VERSION "created by canmatrix"

NS_ :

BS_:

BU_: BDC_Body CHC DME1 EME FLA NiVi ZGW Kombi Kombi_Basis Diagnosetool_FA_CAN CDC_ZGW DME2 ELV Gliwa_T1_Host FA_CAN_Dummy

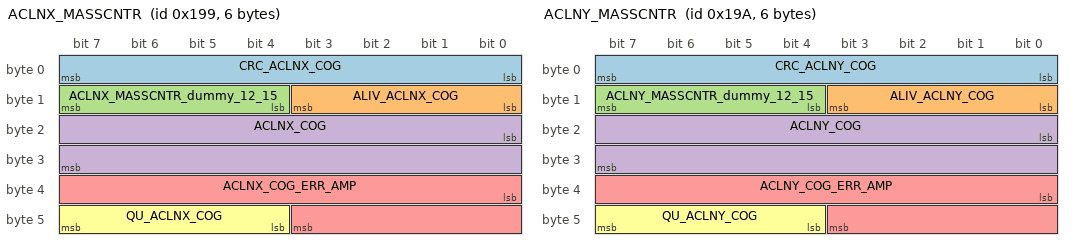
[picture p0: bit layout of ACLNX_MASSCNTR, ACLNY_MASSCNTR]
BO_ 409 ACLNX_MASSCNTR: 6 ZGW
 SG_ CRC_ACLNX_COG : 0|8@1+ (1,0) [0|255] "This unit fulfills the required AUTOSAR reference to a unit. No real unit is defined." Vector__XXX
 SG_ ALIV_ACLNX_COG : 8|4@1+ (1,0) [0|14] "This unit fulfills the required AUTOSAR reference to a unit. No real unit is defined." Vector__XXX
 SG_ ACLNX_MASSCNTR_dummy_12_15 : 12|4@1+ (1,0) [-8|7] "" Vector__XXX
 SG_ ACLNX_COG : 16|16@1+ (0.002,-65) [-65.130|-64.870] "m/s²" Vector__XXX
 SG_ ACLNX_COG_ERR_AMP : 32|12@1+ (0.005,0) [0.000|0.100] "m/s²" Vector__XXX
 SG_ QU_ACLNX_COG : 44|4@1+ (1,0) [0|15] "" Vector__XXX

BO_ 410 ACLNY_MASSCNTR: 6 ZGW
 SG_ CRC_ACLNY_COG : 0|8@1+ (1,0) [0|255] "This unit fulfills the required AUTOSAR reference to a unit. No real unit is defined." Vector__XXX
 SG_ ALIV_ACLNY_COG : 8|4@1+ (1,0) [0|14] "This unit fulfills the required AUTOSAR reference to a unit. No real unit is defined." Vector__XXX
 SG_ ACLNY_MASSCNTR_dummy_12_15 : 12|4@1+ (1,0) [-8|7] "" Vector__XXX
 SG_ ACLNY_COG : 16|16@1+ (0.002,-65) [-65.130|-64.870] "m/s²" Vector__XXX
 SG_ ACLNY_COG_ERR_AMP : 32|12@1+ (0.005,0) [0.000|0.100] "m/s²" Vector__XXX
 SG_ QU_ACLNY_COG : 44|4@1+ (1,0) [0|15] "" Vector__XXX

BO_ 517 ACOU_RQ_KI: 2 Kombi
 SG_ RQ_ACOU_KI : 0|4@1+ (1,0) [0|15] "" ZGW

BO_ 999 ACTVN_CARS: 8 ZGW
 SG_ CTR_ACTVN_CARS : 0|8@1+ (1,0) [0|255] "" BDC_Body
 SG_ CTR_FBD_CARS : 8|8@1+ (1,0) [0|255] "" BDC_Body
 SG_ CTR_PRSL_PROFIL_CARS : 16|8@1+ (1,0) [0|255] "" BDC_Body

BO_ 192 ALIVE_ZGM: 2 ZGW
 SG_ ALIV_COU_ZGM : 0|4@1+ (1,0) [0|15] "" Kombi,Diagnosetool_FA_CAN,Kombi_Basis
 SG_ INFO_BUS_ZGM : 8|8@1+ (1,0) [0|255] "" Diagnosetool_FA_CAN

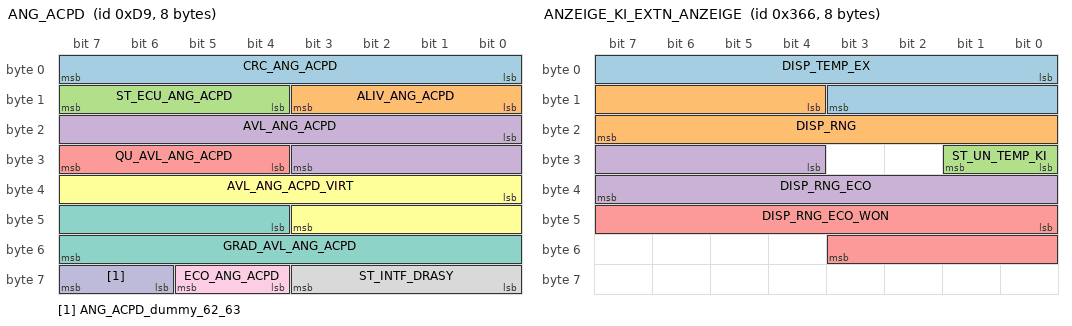
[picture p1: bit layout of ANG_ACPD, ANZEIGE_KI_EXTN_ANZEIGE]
BO_ 217 ANG_ACPD: 8 DME1
 SG_ CRC_ANG_ACPD : 0|8@1+ (1,0) [0|255] "This unit fulfills the required AUTOSAR reference to a unit. No real unit is defined." Vector__XXX
 SG_ ALIV_ANG_ACPD : 8|4@1+ (1,0) [0|14] "This unit fulfills the required AUTOSAR reference to a unit. No real unit is defined." Vector__XXX
 SG_ ST_ECU_ANG_ACPD : 12|4@1+ (1,0) [0|15] "" Vector__XXX
 SG_ AVL_ANG_ACPD : 16|12@1+ (0.025,0) [0.000|2.500] "%" Vector__XXX
 SG_ QU_AVL_ANG_ACPD : 28|4@1+ (1,0) [0|15] "" Vector__XXX
 SG_ AVL_ANG_ACPD_VIRT : 32|12@1+ (0.025,0) [0.000|2.500] "%" Vector__XXX
 SG_ GRAD_AVL_ANG_ACPD : 44|12@1+ (4,-8187) [-40935|24569] "%/s" Vector__XXX
 SG_ ST_INTF_DRASY : 56|4@1+ (1,0) [0|15] "" Vector__XXX
 SG_ ECO_ANG_ACPD : 60|2@1+ (1,0) [0|3] "" Vector__XXX
 SG_ ANG_ACPD_dummy_62_63 : 62|2@1+ (1,0) [-2|1] "" Vector__XXX

BO_ 870 ANZEIGE_KI_EXTN_ANZEIGE: 8 Kombi
 SG_ DISP_TEMP_EX : 0|12@1+ (0.5,-40) [-60|44] "This unit fulfills the required AUTOSAR reference to a unit. No real unit is defined." ZGW
 SG_ DISP_RNG : 12|12@1+ (1,0) [0|4000] "This unit fulfills the required AUTOSAR reference to a unit. No real unit is defined." ZGW
 SG_ ST_UN_TEMP_KI : 24|2@1+ (1,0) [0|3] "" ZGW
 SG_ DISP_RNG_ECO : 28|12@1+ (1,0) [0|4000] "This unit fulfills the required AUTOSAR reference to a unit. No real unit is defined." ZGW
 SG_ DISP_RNG_ECO_WON : 40|12@1+ (0.1,0) [0|40.92] "This unit fulfills the required AUTOSAR reference to a unit. No real unit is defined." ZGW

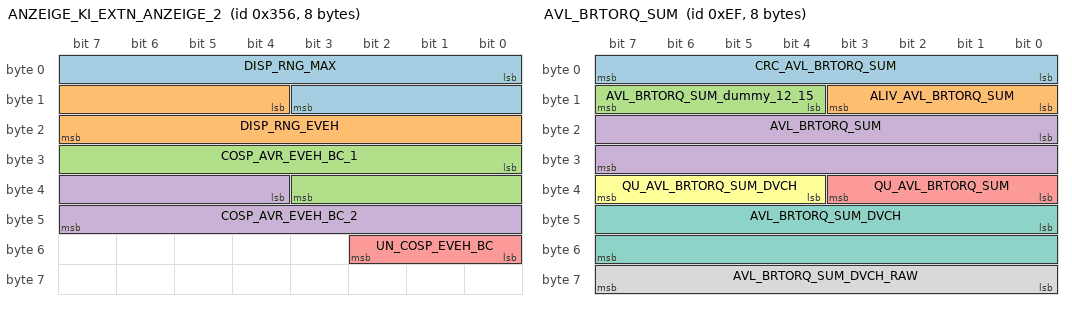
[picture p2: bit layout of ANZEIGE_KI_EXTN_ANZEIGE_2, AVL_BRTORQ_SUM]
BO_ 854 ANZEIGE_KI_EXTN_ANZEIGE_2: 8 Kombi
 SG_ DISP_RNG_MAX : 0|12@1+ (1,0) [0|4000] "This unit fulfills the required AUTOSAR reference to a unit. No real unit is defined." ZGW
 SG_ DISP_RNG_EVEH : 12|12@1+ (1,0) [0|4000] "This unit fulfills the required AUTOSAR reference to a unit. No real unit is defined." ZGW,BDC_Body
 SG_ COSP_AVR_EVEH_BC_1 : 24|12@1+ (0.1,0) [0|40] "This unit fulfills the required AUTOSAR reference to a unit. No real unit is defined." ZGW
 SG_ COSP_AVR_EVEH_BC_2 : 36|12@1+ (0.1,0) [0|40] "This unit fulfills the required AUTOSAR reference to a unit. No real unit is defined." ZGW
 SG_ UN_COSP_EVEH_BC : 48|3@1+ (1,0) [0|7] "" ZGW

BO_ 239 AVL_BRTORQ_SUM: 8 ZGW
 SG_ CRC_AVL_BRTORQ_SUM : 0|8@1+ (1,0) [0|255] "This unit fulfills the required AUTOSAR reference to a unit. No real unit is defined." Vector__XXX
 SG_ ALIV_AVL_BRTORQ_SUM : 8|4@1+ (1,0) [0|14] "This unit fulfills the required AUTOSAR reference to a unit. No real unit is defined." Vector__XXX
 SG_ AVL_BRTORQ_SUM_dummy_12_15 : 12|4@1+ (1,0) [-8|7] "" Vector__XXX
 SG_ AVL_BRTORQ_SUM : 16|16@1+ (1,-32000) [-64000|-32000] "Nm" Vector__XXX
 SG_ QU_AVL_BRTORQ_SUM : 32|4@1+ (1,0) [0|15] "" Vector__XXX
 SG_ QU_AVL_BRTORQ_SUM_DVCH : 36|4@1+ (1,0) [0|15] "" Vector__XXX
 SG_ AVL_BRTORQ_SUM_DVCH : 40|16@1+ (1,-32000) [-64000|-32000] "Nm" Vector__XXX
 SG_ AVL_BRTORQ_SUM_DVCH_RAW : 56|8@1+ (1,-252) [-504|-252] "Nm" Vector__XXX

BO_ 264 AVL_DT_LE: 8 EME
 SG_ AVL_OPMO_CHGE : 40|4@1+ (1,0) [0|15] "" Vector__XXX

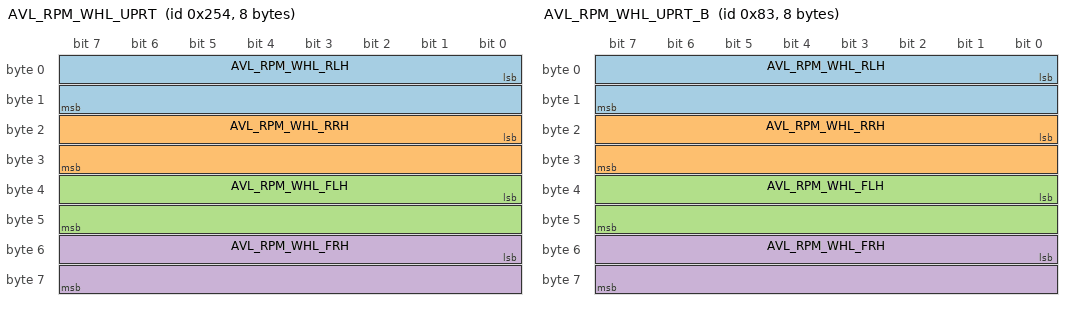
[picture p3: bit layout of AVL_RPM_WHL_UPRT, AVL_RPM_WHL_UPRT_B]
BO_ 596 AVL_RPM_WHL_UPRT: 8 ZGW
 SG_ AVL_RPM_WHL_RLH : 0|16@1+ (0.015625,-511.984375) [-518.234375|-505.734375] "rad/s" Kombi,BDC_Body,Kombi_Basis,DME1
 SG_ AVL_RPM_WHL_RRH : 16|16@1+ (0.015625,-511.984375) [-518.234375|-505.734375] "rad/s" Kombi,BDC_Body,Kombi_Basis,DME1
 SG_ AVL_RPM_WHL_FLH : 32|16@1+ (0.015625,-511.984375) [-518.234375|-505.734375] "rad/s" Kombi,BDC_Body,Kombi_Basis,DME1
 SG_ AVL_RPM_WHL_FRH : 48|16@1+ (0.015625,-511.984375) [-518.234375|-505.734375] "rad/s" Kombi,BDC_Body,Kombi_Basis,DME1

BO_ 131 AVL_RPM_WHL_UPRT_B: 8 ZGW
 SG_ AVL_RPM_WHL_RLH : 0|16@1+ (0.015625,-511.984375) [-518.234375|-505.734375] "rad/s" Kombi,DME1
 SG_ AVL_RPM_WHL_RRH : 16|16@1+ (0.015625,-511.984375) [-518.234375|-505.734375] "rad/s" Kombi,DME1
 SG_ AVL_RPM_WHL_FLH : 32|16@1+ (0.015625,-511.984375) [-518.234375|-505.734375] "rad/s" Kombi,DME1
 SG_ AVL_RPM_WHL_FRH : 48|16@1+ (0.015625,-511.984375) [-518.234375|-505.734375] "rad/s" Kombi,DME1

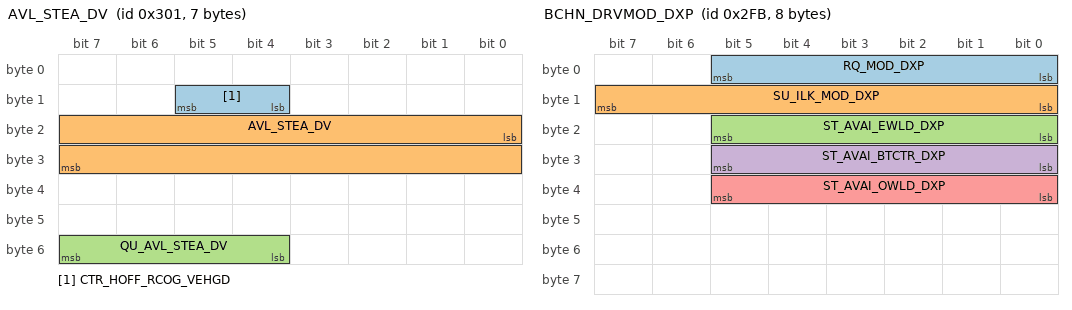
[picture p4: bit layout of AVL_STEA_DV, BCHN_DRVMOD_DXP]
BO_ 769 AVL_STEA_DV: 7 ZGW
 SG_ CTR_HOFF_RCOG_VEHGD : 12|2@1+ (1,0) [0|3] "" BDC_Body
 SG_ AVL_STEA_DV : 16|16@1+ (0.0439453125,-1439.9560546875) [-1503.23537349700927734375|-1376.67673587799072265625] "°" BDC_Body
 SG_ QU_AVL_STEA_DV : 52|4@1+ (1,0) [0|15] "" BDC_Body

BO_ 714 A_TEMP: 2 Kombi
 SG_ TEMP_EX : 0|8@1+ (0.5,-40) [-40|85] "°C" CDC_ZGW,BDC_Body,FLA,ELV,EME,DME2,DME1,CHC,ZGW,NiVi
 SG_ TEMP_EX_UNFILT : 8|8@1+ (0.5,-40) [-40|85] "°C" ZGW,DME2,DME1

BO_ 763 BCHN_DRVMOD_DXP: 8 DME1
 SG_ RQ_MOD_DXP : 0|6@1+ (1,0) [0|63] "" BDC_Body
 SG_ SU_ILK_MOD_DXP : 8|8@1+ (1,0) [0|255] "" BDC_Body
 SG_ ST_AVAI_EWLD_DXP : 16|6@1+ (1,0) [0|63] "" ZGW,BDC_Body
 SG_ ST_AVAI_BTCTR_DXP : 24|6@1+ (1,0) [0|63] "" ZGW,BDC_Body
 SG_ ST_AVAI_OWLD_DXP : 32|6@1+ (1,0) [0|63] "" ZGW,BDC_Body

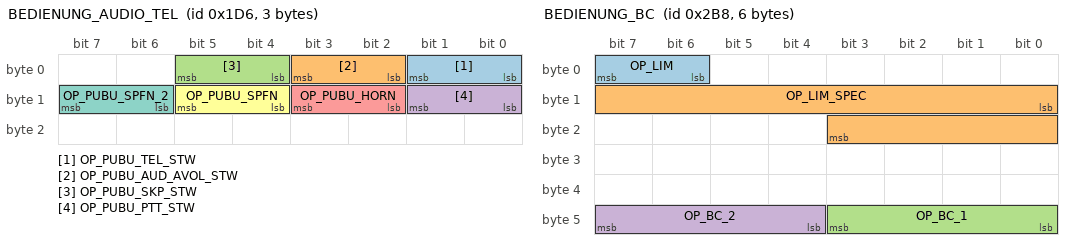
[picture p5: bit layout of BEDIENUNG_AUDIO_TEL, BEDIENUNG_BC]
BO_ 470 BEDIENUNG_AUDIO_TEL: 3 BDC_Body
 SG_ OP_PUBU_TEL_STW : 0|2@1+ (1,0) [0|3] "" ZGW
 SG_ OP_PUBU_AUD_AVOL_STW : 2|2@1+ (1,0) [0|3] "" ZGW
 SG_ OP_PUBU_SKP_STW : 4|2@1+ (1,0) [0|3] "" ZGW
 SG_ OP_PUBU_PTT_STW : 8|2@1+ (1,0) [0|3] "" ZGW
 SG_ OP_PUBU_HORN : 10|2@1+ (1,0) [0|3] "" ZGW
 SG_ OP_PUBU_SPFN : 12|2@1+ (1,0) [0|3] "" ZGW
 SG_ OP_PUBU_SPFN_2 : 14|2@1+ (1,0) [0|3] "" ZGW

BO_ 696 BEDIENUNG_BC: 6 ZGW
 SG_ OP_LIM : 6|2@1+ (1,0) [0|3] "" Kombi,Kombi_Basis
 SG_ OP_LIM_SPEC : 8|12@1+ (1,0) [0|4094] "This unit fulfills the required AUTOSAR reference to a unit. No real unit is defined." Kombi,Kombi_Basis
 SG_ OP_BC_1 : 40|4@1+ (1,0) [0|15] "" Kombi,Kombi_Basis
 SG_ OP_BC_2 : 44|4@1+ (1,0) [0|15] "" Kombi,Kombi_Basis

BO_ 494 BEDIENUNG_LENKSTOCK: 2 BDC_Body
 SG_ OP_COLS : 0|8@1+ (1,0) [0|255] "" NiVi,FLA,Kombi_Basis,ZGW,Kombi
 SG_ ST_PUBU_MAB_ASST : 8|2@1+ (1,0) [0|3] "" ZGW

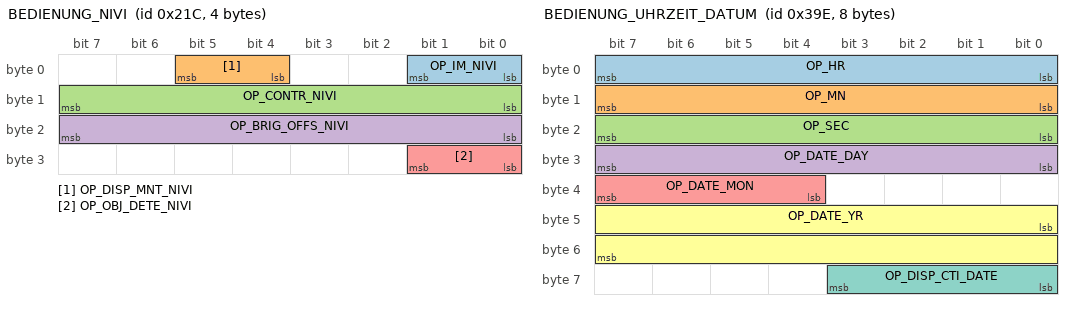
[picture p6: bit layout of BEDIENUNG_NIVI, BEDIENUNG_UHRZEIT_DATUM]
BO_ 540 BEDIENUNG_NIVI: 4 ZGW
 SG_ OP_IM_NIVI : 0|2@1+ (1,0) [0|3] "" NiVi
 SG_ OP_DISP_MNT_NIVI : 4|2@1+ (1,0) [0|3] "" NiVi
 SG_ OP_CONTR_NIVI : 8|8@1+ (1,0) [0|100] "%" NiVi
 SG_ OP_BRIG_OFFS_NIVI : 16|8@1+ (1,0) [0|100] "%" NiVi
 SG_ OP_OBJ_DETE_NIVI : 24|2@1+ (1,0) [0|3] "" NiVi

BO_ 552 BEDIENUNG_SONDERFUNKTION: 2 ZGW
 SG_ ID_SPFN : 0|16@1+ (1,0) [0|65534] "This unit fulfills the required AUTOSAR reference to a unit. No real unit is defined." DME2,DME1

BO_ 926 BEDIENUNG_UHRZEIT_DATUM: 8 ZGW
 SG_ OP_HR : 0|8@1+ (1,0) [0|254] "h" Kombi,Kombi_Basis
 SG_ OP_MN : 8|8@1+ (1,0) [0|254] "min" Kombi,Kombi_Basis
 SG_ OP_SEC : 16|8@1+ (1,0) [0|254] "s" Kombi,Kombi_Basis
 SG_ OP_DATE_DAY : 24|8@1+ (1,0) [0|254] "This unit fulfills the required AUTOSAR reference to a unit. No real unit is defined." Kombi,Kombi_Basis
 SG_ OP_DATE_MON : 36|4@1+ (1,0) [0|14] "This unit fulfills the required AUTOSAR reference to a unit. No real unit is defined." Kombi,Kombi_Basis
 SG_ OP_DATE_YR : 40|16@1+ (1,0) [0|65534] "This unit fulfills the required AUTOSAR reference to a unit. No real unit is defined." Kombi,Kombi_Basis
 SG_ OP_DISP_CTI_DATE : 56|4@1+ (1,0) [0|15] "" Kombi,Kombi_Basis

BO_ 678 BEDIENUNG_WISCHER: 2 BDC_Body
 SG_ OP_WISW : 0|8@1+ (1,0) [0|255] "" ZGW
 SG_ OP_WIPO : 8|3@1+ (1,0) [0|7] "" ZGW
 SG_ ALIV_WISW : 11|4@1+ (1,0) [0|15] "" ZGW

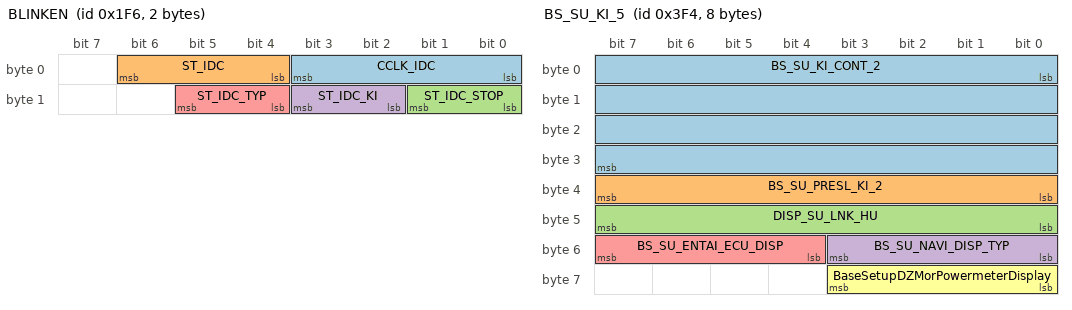
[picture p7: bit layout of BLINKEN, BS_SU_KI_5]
BO_ 502 BLINKEN: 2 BDC_Body
 SG_ CCLK_IDC : 0|4@1+ (1,0) [0|15] "" ZGW,Kombi,Kombi_Basis
 SG_ ST_IDC : 4|3@1+ (1,0) [0|7] "" DME2,DME1,Kombi_Basis,ZGW,Kombi
 SG_ ST_IDC_STOP : 8|2@1+ (1,0) [0|3] "" ZGW,Kombi,Kombi_Basis
 SG_ ST_IDC_KI : 10|2@1+ (1,0) [0|3] "" ZGW,Kombi,Kombi_Basis
 SG_ ST_IDC_TYP : 12|2@1+ (1,0) [0|3] "" ZGW

BO_ 641 BN_UVL: 2 DME1
 SG_ MEAQ_U_14V : 0|12@1+ (15,0) [0|900000] "mV" ZGW,BDC_Body

BO_ 677 BRIG_SURR: 2 BDC_Body
 SG_ VL_BRIG_ENVI : 0|8@1+ (100,0) [0|2540000] "lx" ZGW,Kombi,Kombi_Basis,NiVi
 SG_ VL_BRIG_PFIE : 8|8@1+ (0.0067,0) [0.0000|0.01140206] "W/m²" ZGW,Kombi,Kombi_Basis

BO_ 946 BS_SU_KI_4: 8 Kombi
 SG_ BS_SU_KI_BC : 0|32@1+ (1,0) [0|4294967295] "" ZGW
 SG_ BS_SU_KI_CONT : 32|16@1+ (1,0) [0|65535] "" ZGW
 SG_ BS_SU_PRESL_KI : 48|8@1+ (1,0) [0|255] "" ZGW

BO_ 1012 BS_SU_KI_5: 8 Kombi
 SG_ BS_SU_KI_CONT_2 : 0|32@1+ (1,0) [0|4294967295] "" ZGW
 SG_ BS_SU_PRESL_KI_2 : 32|8@1+ (1,0) [0|255] "" ZGW
 SG_ DISP_SU_LNK_HU : 40|8@1+ (1,0) [0|255] "" ZGW
 SG_ BS_SU_NAVI_DISP_TYP : 48|4@1+ (1,0) [0|15] "" ZGW
 SG_ BS_SU_ENTAI_ECU_DISP : 52|4@1+ (1,0) [0|15] "" ZGW
 SG_ BaseSetupDZMorPowermeterDisplay : 56|4@1+ (1,0) [0|15] "" ZGW

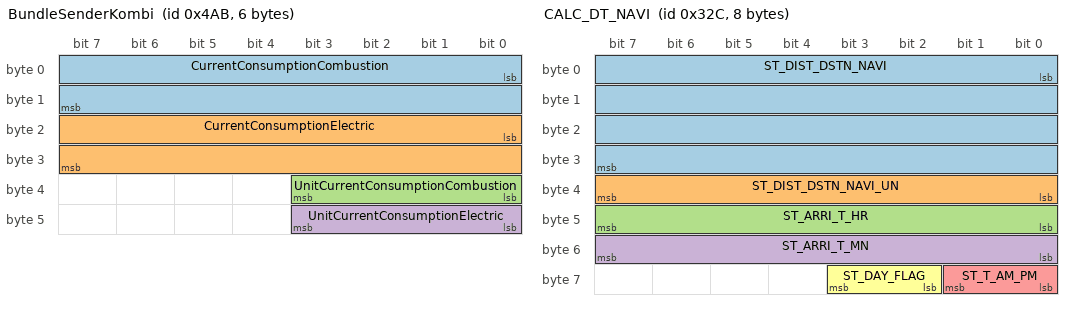
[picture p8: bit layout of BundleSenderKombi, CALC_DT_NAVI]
BO_ 1195 BundleSenderKombi: 6 Kombi
 SG_ CurrentConsumptionCombustion : 0|16@1+ (0.1,0) [0|655.32] "This unit fulfills the required AUTOSAR reference to a unit. No real unit is defined." CDC_ZGW
 SG_ CurrentConsumptionElectric : 16|16@1+ (0.1,0) [0|655.32] "This unit fulfills the required AUTOSAR reference to a unit. No real unit is defined." CDC_ZGW
 SG_ UnitCurrentConsumptionCombustion : 32|4@1+ (1,0) [0|15] "" CDC_ZGW
 SG_ UnitCurrentConsumptionElectric : 40|4@1+ (1,0) [0|15] "" CDC_ZGW

BO_ 812 CALC_DT_NAVI: 8 ZGW
 SG_ ST_DIST_DSTN_NAVI : 0|32@1+ (0.001,0) [0.000|4294.967294] "This unit fulfills the required AUTOSAR reference to a unit. No real unit is defined." Kombi,Kombi_Basis
 SG_ ST_DIST_DSTN_NAVI_UN : 32|8@1+ (1,0) [0|255] "" Kombi,Kombi_Basis
 SG_ ST_ARRI_T_HR : 40|8@1+ (1,0) [0|23] "h" Kombi,Kombi_Basis
 SG_ ST_ARRI_T_MN : 48|8@1+ (1,0) [0|59] "min" Kombi,Kombi_Basis
 SG_ ST_T_AM_PM : 56|2@1+ (1,0) [0|3] "" Kombi,Kombi_Basis
 SG_ ST_DAY_FLAG : 58|2@1+ (1,0) [0|3] "" Kombi,Kombi_Basis

BO_ 1184 CAS_ST_1: 8 BDC_Body
 SG_ DT_APPL_CAS_ST_1 : 0|64@1+ (1,0) [0|18446744073709551615] "This unit fulfills the required AUTOSAR reference to a unit. No real unit is defined." BDC_Body

BO_ 1186 CAS_ST_2: 8 BDC_Body
 SG_ DT_APPL_CAS_ST_2 : 0|64@1+ (1,0) [0|18446744073709551615] "This unit fulfills the required AUTOSAR reference to a unit. No real unit is defined." BDC_Body

BO_ 110 CCLK_COU_SYNCN_CAN: 8 ZGW
 SG_ CCLK_COU_SYNCN_CAN_TYP : 0|8@1+ (1,0) [0|255] "" Vector__XXX
 SG_ CCLK_COU_SYNCN_CAN_IDENT : 8|16@1+ (1,0) [0|65532] "This unit fulfills the required AUTOSAR reference to a unit. No real unit is defined." Vector__XXX
 SG_ CCLK_COU_SYNCN_CAN_SEC : 24|32@1+ (1,0) [0|4294967292] "s" Vector__XXX

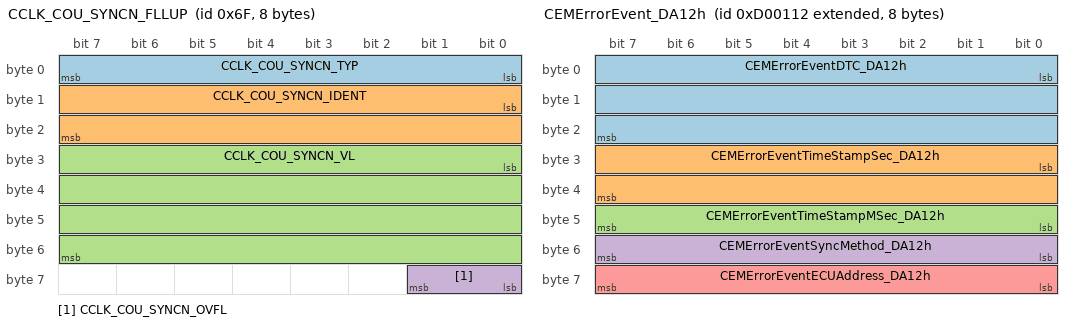
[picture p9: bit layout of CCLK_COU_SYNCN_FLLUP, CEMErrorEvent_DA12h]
BO_ 111 CCLK_COU_SYNCN_FLLUP: 8 ZGW
 SG_ CCLK_COU_SYNCN_TYP : 0|8@1+ (1,0) [0|255] "" Vector__XXX
 SG_ CCLK_COU_SYNCN_IDENT : 8|16@1+ (1,0) [0|65532] "This unit fulfills the required AUTOSAR reference to a unit. No real unit is defined." Vector__XXX
 SG_ CCLK_COU_SYNCN_VL : 24|32@1+ (1,0) [0|3999999999] "ns/4" Vector__XXX
 SG_ CCLK_COU_SYNCN_OVFL : 56|2@1+ (1,0) [0|3] "" Vector__XXX

BO_ 2161115410 CEMErrorEvent_DA12h: 8 DME1
 SG_ CEMErrorEventDTC_DA12h : 0|24@1+ (1,0) [0|16777212] "This unit fulfills the required AUTOSAR reference to a unit. No real unit is defined." Vector__XXX
 SG_ CEMErrorEventTimeStampSec_DA12h : 24|16@1+ (1,0) [0|65532] "s" Vector__XXX
 SG_ CEMErrorEventTimeStampMSec_DA12h : 40|8@1+ (1,0) [0|199] "ms" Vector__XXX
 SG_ CEMErrorEventSyncMethod_DA12h : 48|8@1+ (1,0) [0|252] "This unit fulfills the required AUTOSAR reference to a unit. No real unit is defined." Vector__XXX
 SG_ CEMErrorEventECUAddress_DA12h : 56|8@1+ (1,0) [0|207] "This unit fulfills the required AUTOSAR reference to a unit. No real unit is defined." Vector__XXX

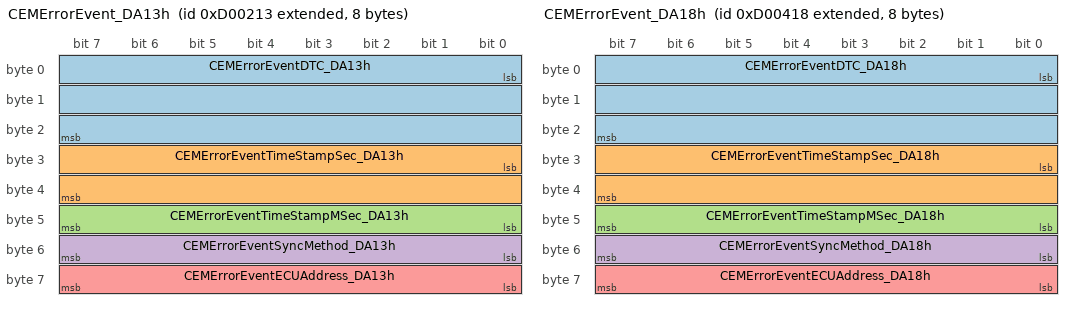
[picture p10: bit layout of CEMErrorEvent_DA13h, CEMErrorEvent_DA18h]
BO_ 2161115667 CEMErrorEvent_DA13h: 8 DME2
 SG_ CEMErrorEventDTC_DA13h : 0|24@1+ (1,0) [0|16777212] "This unit fulfills the required AUTOSAR reference to a unit. No real unit is defined." Vector__XXX
 SG_ CEMErrorEventTimeStampSec_DA13h : 24|16@1+ (1,0) [0|65532] "s" Vector__XXX
 SG_ CEMErrorEventTimeStampMSec_DA13h : 40|8@1+ (1,0) [0|199] "ms" Vector__XXX
 SG_ CEMErrorEventSyncMethod_DA13h : 48|8@1+ (1,0) [0|252] "This unit fulfills the required AUTOSAR reference to a unit. No real unit is defined." Vector__XXX
 SG_ CEMErrorEventECUAddress_DA13h : 56|8@1+ (1,0) [0|207] "This unit fulfills the required AUTOSAR reference to a unit. No real unit is defined." Vector__XXX

BO_ 2161116184 CEMErrorEvent_DA18h: 8 DME1
 SG_ CEMErrorEventDTC_DA18h : 0|24@1+ (1,0) [0|16777212] "This unit fulfills the required AUTOSAR reference to a unit. No real unit is defined." Vector__XXX
 SG_ CEMErrorEventTimeStampSec_DA18h : 24|16@1+ (1,0) [0|65532] "s" Vector__XXX
 SG_ CEMErrorEventTimeStampMSec_DA18h : 40|8@1+ (1,0) [0|199] "ms" Vector__XXX
 SG_ CEMErrorEventSyncMethod_DA18h : 48|8@1+ (1,0) [0|252] "This unit fulfills the required AUTOSAR reference to a unit. No real unit is defined." Vector__XXX
 SG_ CEMErrorEventECUAddress_DA18h : 56|8@1+ (1,0) [0|207] "This unit fulfills the required AUTOSAR reference to a unit. No real unit is defined." Vector__XXX

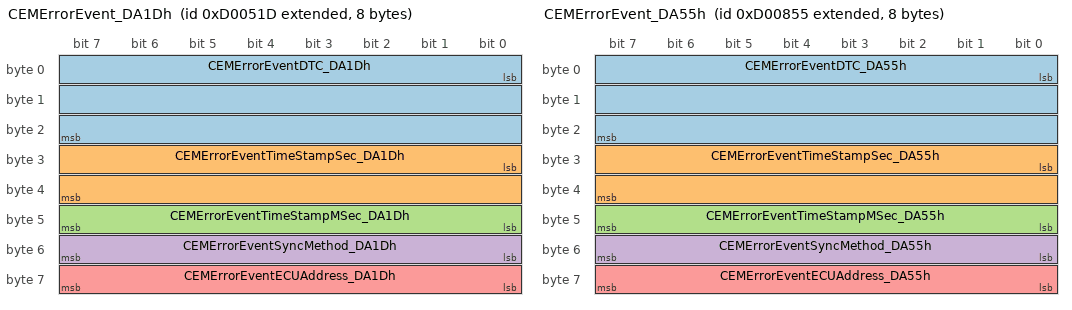
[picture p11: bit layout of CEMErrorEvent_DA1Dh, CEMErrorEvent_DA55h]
BO_ 2161116445 CEMErrorEvent_DA1Dh: 8 DME1
 SG_ CEMErrorEventDTC_DA1Dh : 0|24@1+ (1,0) [0|16777212] "This unit fulfills the required AUTOSAR reference to a unit. No real unit is defined." Vector__XXX
 SG_ CEMErrorEventTimeStampSec_DA1Dh : 24|16@1+ (1,0) [0|65532] "s" Vector__XXX
 SG_ CEMErrorEventTimeStampMSec_DA1Dh : 40|8@1+ (1,0) [0|199] "ms" Vector__XXX
 SG_ CEMErrorEventSyncMethod_DA1Dh : 48|8@1+ (1,0) [0|252] "This unit fulfills the required AUTOSAR reference to a unit. No real unit is defined." Vector__XXX
 SG_ CEMErrorEventECUAddress_DA1Dh : 56|8@1+ (1,0) [0|207] "This unit fulfills the required AUTOSAR reference to a unit. No real unit is defined." Vector__XXX

BO_ 2161117269 CEMErrorEvent_DA55h: 8 DME1
 SG_ CEMErrorEventDTC_DA55h : 0|24@1+ (1,0) [0|16777212] "This unit fulfills the required AUTOSAR reference to a unit. No real unit is defined." Vector__XXX
 SG_ CEMErrorEventTimeStampSec_DA55h : 24|16@1+ (1,0) [0|65532] "s" Vector__XXX
 SG_ CEMErrorEventTimeStampMSec_DA55h : 40|8@1+ (1,0) [0|199] "ms" Vector__XXX
 SG_ CEMErrorEventSyncMethod_DA55h : 48|8@1+ (1,0) [0|252] "This unit fulfills the required AUTOSAR reference to a unit. No real unit is defined." Vector__XXX
 SG_ CEMErrorEventECUAddress_DA55h : 56|8@1+ (1,0) [0|207] "This unit fulfills the required AUTOSAR reference to a unit. No real unit is defined." Vector__XXX

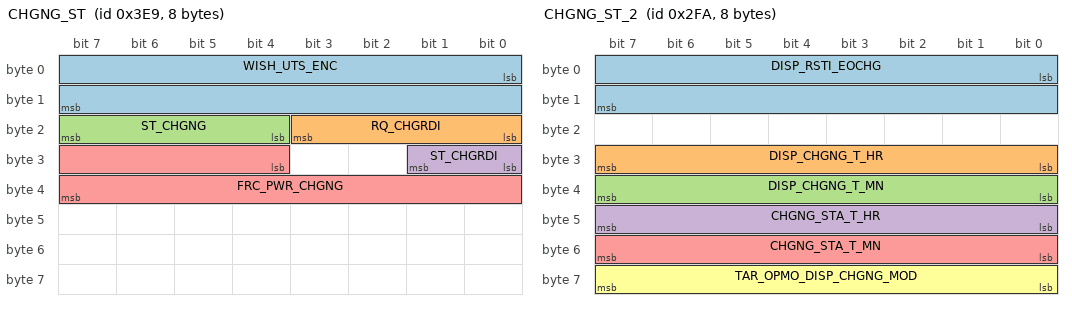
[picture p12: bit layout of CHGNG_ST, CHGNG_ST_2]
BO_ 1001 CHGNG_ST: 8 EME
 SG_ WISH_UTS_ENC : 0|16@1+ (1,0) [0|65534] "Wh" Vector__XXX
 SG_ RQ_CHGRDI : 16|4@1+ (1,0) [0|15] "" Vector__XXX
 SG_ ST_CHGNG : 20|4@1+ (1,0) [0|15] "" CDC_ZGW,Kombi,BDC_Body,ZGW
 SG_ ST_CHGRDI : 24|2@1+ (1,0) [0|3] "" Vector__XXX
 SG_ FRC_PWR_CHGNG : 28|12@1+ (25,0) [0|2558750] "W" ZGW

BO_ 762 CHGNG_ST_2: 8 EME
 SG_ DISP_RSTI_EOCHG : 0|16@1+ (1,0) [0|65532] "min" ZGW,Kombi,BDC_Body,Kombi_Basis
 SG_ DISP_CHGNG_T_HR : 24|8@1+ (1,0) [0|23] "h" ZGW,Kombi,Kombi_Basis
 SG_ DISP_CHGNG_T_MN : 32|8@1+ (1,0) [0|59] "min" ZGW,Kombi,Kombi_Basis
 SG_ CHGNG_STA_T_HR : 40|8@1+ (1,0) [0|23] "h" ZGW,Kombi,Kombi_Basis
 SG_ CHGNG_STA_T_MN : 48|8@1+ (1,0) [0|59] "min" ZGW,Kombi,Kombi_Basis
 SG_ TAR_OPMO_DISP_CHGNG_MOD : 56|8@1+ (1,0) [0|255] "" ZGW,Kombi,Kombi_Basis

BO_ 971 CHNO_COV_V: 4 ZGW
 SG_ CHNO_MILE_WHL : 0|16@1+ (1,0) [0|65534] "1/km" Kombi,Kombi_Basis
 SG_ CHNO_V_VEH_COG : 16|16@1+ (1,0) [0|65534] "1/km" Kombi,Kombi_Basis

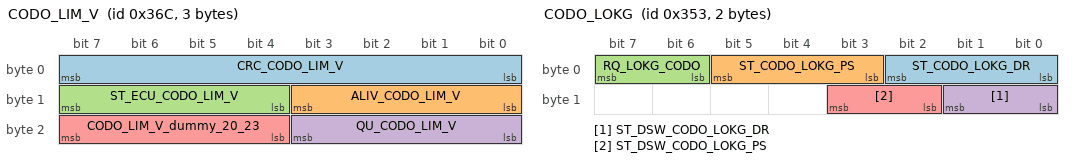
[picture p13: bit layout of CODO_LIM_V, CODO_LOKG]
BO_ 876 CODO_LIM_V: 3 ZGW
 SG_ CRC_CODO_LIM_V : 0|8@1+ (1,0) [0|255] "This unit fulfills the required AUTOSAR reference to a unit. No real unit is defined." Vector__XXX
 SG_ ALIV_CODO_LIM_V : 8|4@1+ (1,0) [0|14] "This unit fulfills the required AUTOSAR reference to a unit. No real unit is defined." Vector__XXX
 SG_ ST_ECU_CODO_LIM_V : 12|4@1+ (1,0) [0|15] "" Vector__XXX
 SG_ QU_CODO_LIM_V : 16|4@1+ (1,0) [0|15] "" Vector__XXX
 SG_ CODO_LIM_V_dummy_20_23 : 20|4@1+ (1,0) [-8|7] "" Vector__XXX

BO_ 851 CODO_LOKG: 2 ZGW
 SG_ ST_CODO_LOKG_DR : 0|3@1+ (1,0) [0|7] "" BDC_Body
 SG_ ST_CODO_LOKG_PS : 3|3@1+ (1,0) [0|7] "" BDC_Body
 SG_ RQ_LOKG_CODO : 6|2@1+ (1,0) [0|3] "" BDC_Body
 SG_ ST_DSW_CODO_LOKG_DR : 8|2@1+ (1,0) [0|3] "" BDC_Body
 SG_ ST_DSW_CODO_LOKG_PS : 10|2@1+ (1,0) [0|3] "" BDC_Body

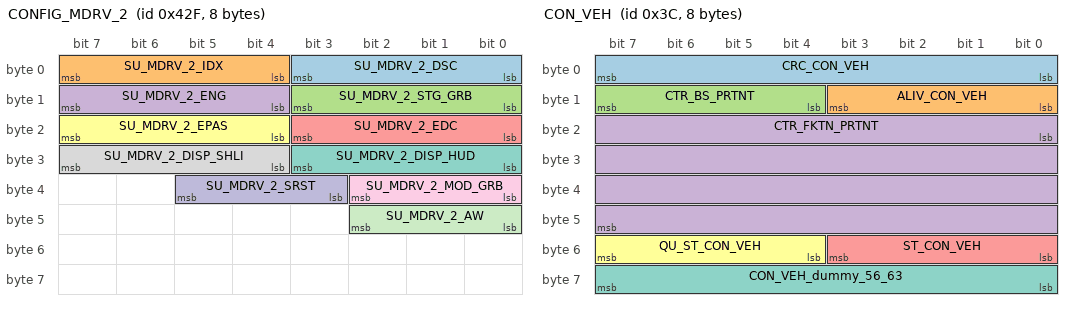
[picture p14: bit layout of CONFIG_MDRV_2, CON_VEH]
BO_ 1071 CONFIG_MDRV_2: 8 ZGW
 SG_ SU_MDRV_2_DSC : 0|4@1+ (1,0) [0|15] "" DME2,DME1
 SG_ SU_MDRV_2_IDX : 4|4@1+ (1,0) [0|15] "" DME2,DME1
 SG_ SU_MDRV_2_STG_GRB : 8|4@1+ (1,0) [0|15] "" DME2,DME1
 SG_ SU_MDRV_2_ENG : 12|4@1+ (1,0) [0|15] "" DME2,DME1
 SG_ SU_MDRV_2_EDC : 16|4@1+ (1,0) [0|15] "" DME2,DME1
 SG_ SU_MDRV_2_EPAS : 20|4@1+ (1,0) [0|15] "" DME2,DME1
 SG_ SU_MDRV_2_DISP_HUD : 24|4@1+ (1,0) [0|15] "" DME2,DME1
 SG_ SU_MDRV_2_DISP_SHLI : 28|4@1+ (1,0) [0|15] "" DME2,DME1
 SG_ SU_MDRV_2_MOD_GRB : 32|3@1+ (1,0) [0|7] "" DME2,DME1
 SG_ SU_MDRV_2_SRST : 35|3@1+ (1,0) [0|7] "" DME2,DME1
 SG_ SU_MDRV_2_AW : 40|3@1+ (1,0) [0|7] "" DME2,DME1

BO_ 775 CON_LVCH: 4 CHC
 SG_ CON_LVCH : 0|8@1+ (1,0) [0|255] "" ZGW
 SG_ REAS_PREV_LVCH : 8|10@1+ (1,0) [0|1023] "" ZGW

BO_ 60 CON_VEH: 8 BDC_Body
 SG_ CRC_CON_VEH : 0|8@1+ (1,0) [0|255] "This unit fulfills the required AUTOSAR reference to a unit. No real unit is defined." Vector__XXX
 SG_ ALIV_CON_VEH : 8|4@1+ (1,0) [0|14] "This unit fulfills the required AUTOSAR reference to a unit. No real unit is defined." Vector__XXX
 SG_ CTR_BS_PRTNT : 12|4@1+ (1,0) [0|15] "" Vector__XXX
 SG_ CTR_FKTN_PRTNT : 16|32@1+ (1,0) [0|4294967295] "" Vector__XXX
 SG_ ST_CON_VEH : 48|4@1+ (1,0) [0|15] "" Vector__XXX
 SG_ QU_ST_CON_VEH : 52|4@1+ (1,0) [0|15] "" Vector__XXX
 SG_ CON_VEH_dummy_56_63 : 56|8@1+ (1,0) [-128|127] "" Vector__XXX

BO_ 818 COSP_INFO_DT: 7 Kombi
 SG_ Multiplexor M : 0|8@1+ (1,0) [-128|127] "" Vector__XXX

BO_ 908 CTR_ACCM: 2 EME
 SG_ RLS_ACCM : 0|2@1+ (1,0) [0|3] "" ZGW
 SG_ RLS_PRECOND_PAIC : 2|2@1+ (1,0) [0|3] "" ZGW,BDC_Body

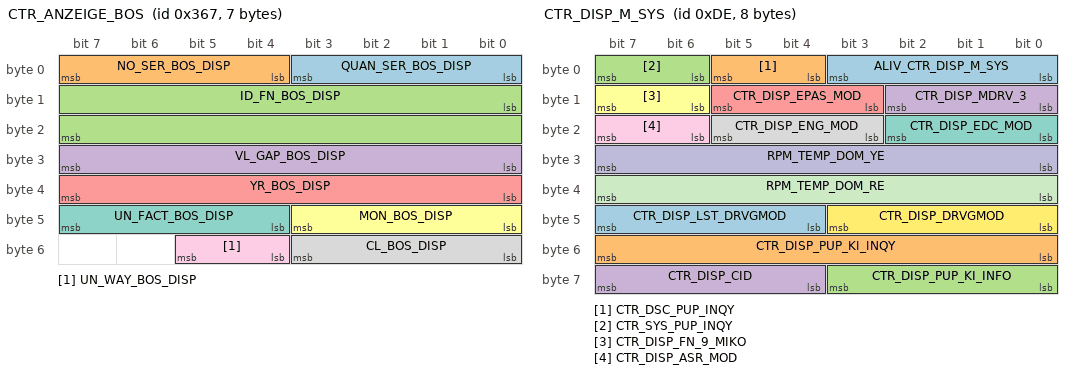
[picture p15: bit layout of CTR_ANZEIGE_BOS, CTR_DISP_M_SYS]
BO_ 871 CTR_ANZEIGE_BOS: 7 Kombi_Basis
 SG_ QUAN_SER_BOS_DISP : 0|4@1+ (1,0) [1|14] "This unit fulfills the required AUTOSAR reference to a unit. No real unit is defined." ZGW
 SG_ NO_SER_BOS_DISP : 4|4@1+ (1,0) [1|14] "This unit fulfills the required AUTOSAR reference to a unit. No real unit is defined." ZGW
 SG_ ID_FN_BOS_DISP : 8|16@1+ (1,0) [0|65535] "" ZGW
 SG_ VL_GAP_BOS_DISP : 24|8@1+ (1,0) [-64|63] "This unit fulfills the required AUTOSAR reference to a unit. No real unit is defined." ZGW
 SG_ YR_BOS_DISP : 32|8@1+ (1,2000) [4001|4254] "This unit fulfills the required AUTOSAR reference to a unit. No real unit is defined." ZGW
 SG_ MON_BOS_DISP : 40|4@1+ (1,0) [1|12] "This unit fulfills the required AUTOSAR reference to a unit. No real unit is defined." ZGW
 SG_ UN_FACT_BOS_DISP : 44|4@1+ (1,0) [0|15] "" ZGW
 SG_ CL_BOS_DISP : 48|4@1+ (1,0) [0|15] "" ZGW
 SG_ UN_WAY_BOS_DISP : 52|2@1+ (1,0) [0|3] "" ZGW

BO_ 700 CTR_CHGINTF_CSM: 2 ZGW
 SG_ CTR_CHGP_LOK_CSM : 0|2@1+ (1,0) [0|3] "" EME

BO_ 524 CTR_CONN_IDT_CHGNG: 8 ZGW
 SG_ CTR_SLCTN_RMV : 0|2@1+ (1,0) [0|3] "" EME

BO_ 978 CTR_DIAG_OBD_ENGMG: 2 DME1
 SG_ RQ_ENGMG_RST_OBD_DIAG : 2|2@1+ (1,0) [0|3] "" BDC_Body

BO_ 222 CTR_DISP_M_SYS: 8 DME1
 SG_ ALIV_CTR_DISP_M_SYS : 0|4@1+ (1,0) [0|14] "This unit fulfills the required AUTOSAR reference to a unit. No real unit is defined." ZGW,Kombi,DME2
 SG_ CTR_DSC_PUP_INQY : 4|2@1+ (1,0) [0|3] "" Kombi,DME2
 SG_ CTR_SYS_PUP_INQY : 6|2@1+ (1,0) [0|3] "" Kombi,DME2
 SG_ CTR_DISP_MDRV_3 : 8|3@1+ (1,0) [0|7] "" Kombi,DME2
 SG_ CTR_DISP_EPAS_MOD : 11|3@1+ (1,0) [0|7] "" ZGW,Kombi,DME2
 SG_ CTR_DISP_FN_9_MIKO : 14|2@1+ (1,0) [0|3] "" BDC_Body
 SG_ CTR_DISP_EDC_MOD : 16|3@1+ (1,0) [0|7] "" ZGW,Kombi,DME2
 SG_ CTR_DISP_ENG_MOD : 19|3@1+ (1,0) [0|7] "" ZGW,Kombi,DME2
 SG_ CTR_DISP_ASR_MOD : 22|2@1+ (1,0) [0|3] "" ZGW
 SG_ RPM_TEMP_DOM_YE : 24|8@1+ (50,0) [0|635000] "1/min" Kombi,DME2
 SG_ RPM_TEMP_DOM_RE : 32|8@1+ (50,0) [0|635000] "1/min" Kombi,DME2
 SG_ CTR_DISP_DRVGMOD : 40|4@1+ (1,0) [0|15] "" ZGW,Kombi
 SG_ CTR_DISP_LST_DRVGMOD : 44|4@1+ (1,0) [0|15] "" Kombi
 SG_ CTR_DISP_PUP_KI_INQY : 48|8@1+ (1,0) [0|255] "" Kombi
 SG_ CTR_DISP_PUP_KI_INFO : 56|4@1+ (1,0) [0|15] "" Kombi
 SG_ CTR_DISP_CID : 60|4@1+ (1,0) [0|15] "" ZGW

BO_ 853 CTR_DRVBH_2: 2 ZGW
 SG_ CTR_DRVBH_2_DISP : 0|3@1+ (1,0) [0|7] "" Kombi,Kombi_Basis

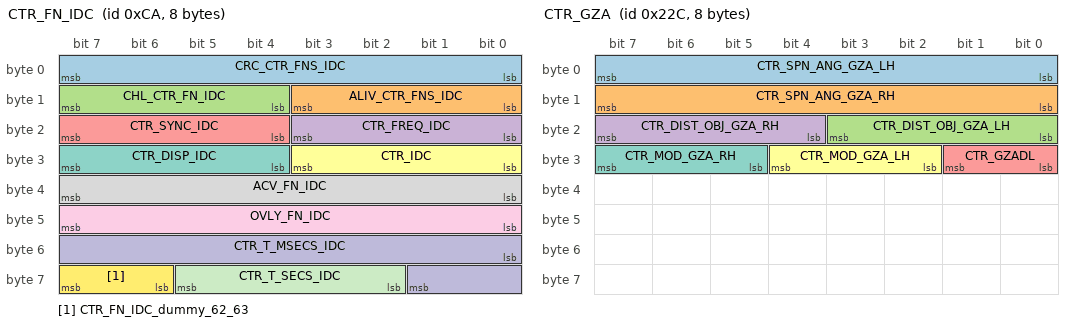
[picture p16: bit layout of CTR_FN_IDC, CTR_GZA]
BO_ 202 CTR_FN_IDC: 8 BDC_Body
 SG_ CRC_CTR_FNS_IDC : 0|8@1+ (1,0) [0|255] "This unit fulfills the required AUTOSAR reference to a unit. No real unit is defined." Vector__XXX
 SG_ ALIV_CTR_FNS_IDC : 8|4@1+ (1,0) [0|14] "This unit fulfills the required AUTOSAR reference to a unit. No real unit is defined." Vector__XXX
 SG_ CHL_CTR_FN_IDC : 12|4@1+ (1,0) [0|14] "This unit fulfills the required AUTOSAR reference to a unit. No real unit is defined." Vector__XXX
 SG_ CTR_FREQ_IDC : 16|4@1+ (1,0) [0|15] "" Vector__XXX
 SG_ CTR_SYNC_IDC : 20|4@1+ (1,0) [0|15] "" Vector__XXX
 SG_ CTR_IDC : 24|4@1+ (1,0) [0|15] "" Vector__XXX
 SG_ CTR_DISP_IDC : 28|4@1+ (1,0) [0|15] "" Vector__XXX
 SG_ ACV_FN_IDC : 32|8@1+ (1,0) [0|255] "" Vector__XXX
 SG_ OVLY_FN_IDC : 40|8@1+ (1,0) [0|255] "" Vector__XXX
 SG_ CTR_T_MSECS_IDC : 48|10@1+ (4194304,0) [0|16765353300328448] "StbmTicks" Vector__XXX
 SG_ CTR_T_SECS_IDC : 58|4@1+ (1,0) [0|9] "s" Vector__XXX
 SG_ CTR_FN_IDC_dummy_62_63 : 62|2@1+ (1,0) [-2|1] "" Vector__XXX

BO_ 556 CTR_GZA: 8 NiVi
 SG_ CTR_SPN_ANG_GZA_LH : 0|8@1+ (0.1,-12.5) [-13.75|-11.25] "°" BDC_Body
 SG_ CTR_SPN_ANG_GZA_RH : 8|8@1+ (0.1,-12.5) [-13.75|-11.25] "°" BDC_Body
 SG_ CTR_DIST_OBJ_GZA_LH : 16|4@1+ (5,20) [120|470] "m" BDC_Body
 SG_ CTR_DIST_OBJ_GZA_RH : 20|4@1+ (5,20) [120|470] "m" BDC_Body
 SG_ CTR_GZADL : 24|2@1+ (1,0) [0|3] "" BDC_Body
 SG_ CTR_MOD_GZA_LH : 26|3@1+ (1,0) [0|7] "" BDC_Body
 SG_ CTR_MOD_GZA_RH : 29|3@1+ (1,0) [0|7] "" BDC_Body

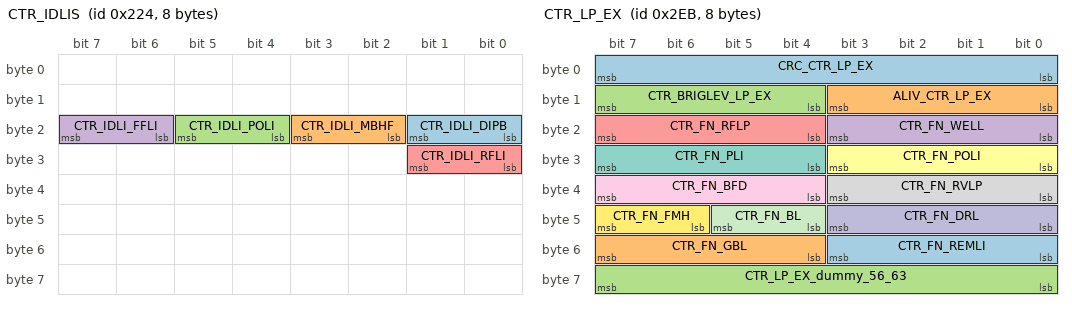
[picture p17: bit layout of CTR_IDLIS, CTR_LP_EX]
BO_ 548 CTR_IDLIS: 8 BDC_Body
 SG_ CTR_IDLI_DIPB : 16|2@1+ (1,0) [0|3] "" Kombi,Kombi_Basis
 SG_ CTR_IDLI_MBHF : 18|2@1+ (1,0) [0|3] "" Kombi,Kombi_Basis
 SG_ CTR_IDLI_POLI : 20|2@1+ (1,0) [0|3] "" Kombi,Kombi_Basis
 SG_ CTR_IDLI_FFLI : 22|2@1+ (1,0) [0|3] "" Kombi,Kombi_Basis
 SG_ CTR_IDLI_RFLI : 24|2@1+ (1,0) [0|3] "" Kombi,Kombi_Basis

BO_ 574 CTR_IDT_CHGNG_CA: 8 BDC_Body
 SG_ CTR_SWO_IDT_CHGNG_CA : 0|2@1+ (1,0) [0|3] "" EME

BO_ 747 CTR_LP_EX: 8 ZGW
 SG_ CRC_CTR_LP_EX : 0|8@1+ (1,0) [0|255] "This unit fulfills the required AUTOSAR reference to a unit. No real unit is defined." Vector__XXX
 SG_ ALIV_CTR_LP_EX : 8|4@1+ (1,0) [0|14] "This unit fulfills the required AUTOSAR reference to a unit. No real unit is defined." Vector__XXX
 SG_ CTR_BRIGLEV_LP_EX : 12|4@1+ (1,0) [0|15] "" Vector__XXX
 SG_ CTR_FN_WELL : 16|4@1+ (1,0) [0|15] "" Vector__XXX
 SG_ CTR_FN_RFLP : 20|4@1+ (1,0) [0|15] "" Vector__XXX
 SG_ CTR_FN_POLI : 24|4@1+ (1,0) [0|15] "" Vector__XXX
 SG_ CTR_FN_PLI : 28|4@1+ (1,0) [0|15] "" Vector__XXX
 SG_ CTR_FN_RVLP : 32|4@1+ (1,0) [0|15] "" Vector__XXX
 SG_ CTR_FN_BFD : 36|4@1+ (1,0) [0|15] "" Vector__XXX
 SG_ CTR_FN_DRL : 40|4@1+ (1,0) [0|15] "" Vector__XXX
 SG_ CTR_FN_BL : 44|2@1+ (1,0) [0|3] "" Vector__XXX
 SG_ CTR_FN_FMH : 46|2@1+ (1,0) [0|3] "" Vector__XXX
 SG_ CTR_FN_REMLI : 48|4@1+ (1,0) [0|15] "" Vector__XXX
 SG_ CTR_FN_GBL : 52|4@1+ (1,0) [0|15] "" Vector__XXX
 SG_ CTR_LP_EX_dummy_56_63 : 56|8@1+ (1,0) [-128|127] "" Vector__XXX

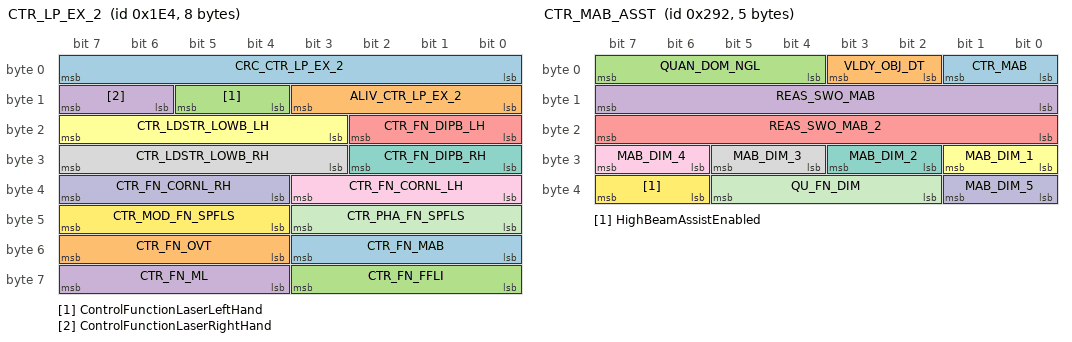
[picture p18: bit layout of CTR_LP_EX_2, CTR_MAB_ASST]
BO_ 484 CTR_LP_EX_2: 8 ZGW
 SG_ CRC_CTR_LP_EX_2 : 0|8@1+ (1,0) [0|255] "This unit fulfills the required AUTOSAR reference to a unit. No real unit is defined." Vector__XXX
 SG_ ALIV_CTR_LP_EX_2 : 8|4@1+ (1,0) [0|14] "This unit fulfills the required AUTOSAR reference to a unit. No real unit is defined." Vector__XXX
 SG_ ControlFunctionLaserLeftHand : 12|2@1+ (1,0) [0|3] "" Vector__XXX
 SG_ ControlFunctionLaserRightHand : 14|2@1+ (1,0) [0|3] "" Vector__XXX
 SG_ CTR_FN_DIPB_LH : 16|3@1+ (1,0) [0|7] "" Vector__XXX
 SG_ CTR_LDSTR_LOWB_LH : 19|5@1+ (1,0) [0|31] "" Vector__XXX
 SG_ CTR_FN_DIPB_RH : 24|3@1+ (1,0) [0|7] "" Vector__XXX
 SG_ CTR_LDSTR_LOWB_RH : 27|5@1+ (1,0) [0|31] "" Vector__XXX
 SG_ CTR_FN_CORNL_LH : 32|4@1+ (1,0) [0|15] "" Vector__XXX
 SG_ CTR_FN_CORNL_RH : 36|4@1+ (1,0) [0|15] "" Vector__XXX
 SG_ CTR_PHA_FN_SPFLS : 40|4@1+ (1,0) [0|15] "" Vector__XXX
 SG_ CTR_MOD_FN_SPFLS : 44|4@1+ (1,0) [0|15] "" Vector__XXX
 SG_ CTR_FN_MAB : 48|4@1+ (1,0) [0|15] "" Vector__XXX
 SG_ CTR_FN_OVT : 52|4@1+ (1,0) [0|15] "" Vector__XXX
 SG_ CTR_FN_FFLI : 56|4@1+ (1,0) [0|15] "" Vector__XXX
 SG_ CTR_FN_ML : 60|4@1+ (1,0) [0|15] "" Vector__XXX

BO_ 773 CTR_LVCH: 4 ZGW
 SG_ TAR_LEV_LVCH : 0|4@1+ (1,0) [0|15] "" CHC

BO_ 658 CTR_MAB_ASST: 5 FLA
 SG_ CTR_MAB : 0|2@1+ (1,0) [0|3] "" BDC_Body
 SG_ VLDY_OBJ_DT : 2|2@1+ (1,0) [0|3] "" NiVi
 SG_ QUAN_DOM_NGL : 4|4@1+ (1,0) [0|12] "This unit fulfills the required AUTOSAR reference to a unit. No real unit is defined." BDC_Body
 SG_ REAS_SWO_MAB : 8|8@1+ (1,0) [0|255] "" BDC_Body
 SG_ REAS_SWO_MAB_2 : 16|8@1+ (1,0) [0|255] "" BDC_Body
 SG_ MAB_DIM_1 : 24|2@1+ (1,0) [0|3] "" BDC_Body
 SG_ MAB_DIM_2 : 26|2@1+ (1,0) [0|3] "" BDC_Body
 SG_ MAB_DIM_3 : 28|2@1+ (1,0) [0|3] "" BDC_Body
 SG_ MAB_DIM_4 : 30|2@1+ (1,0) [0|3] "" BDC_Body
 SG_ MAB_DIM_5 : 32|2@1+ (1,0) [0|3] "" BDC_Body
 SG_ QU_FN_DIM : 34|4@1+ (1,0) [0|15] "" BDC_Body
 SG_ HighBeamAssistEnabled : 38|2@1+ (1,0) [0|3] "" BDC_Body

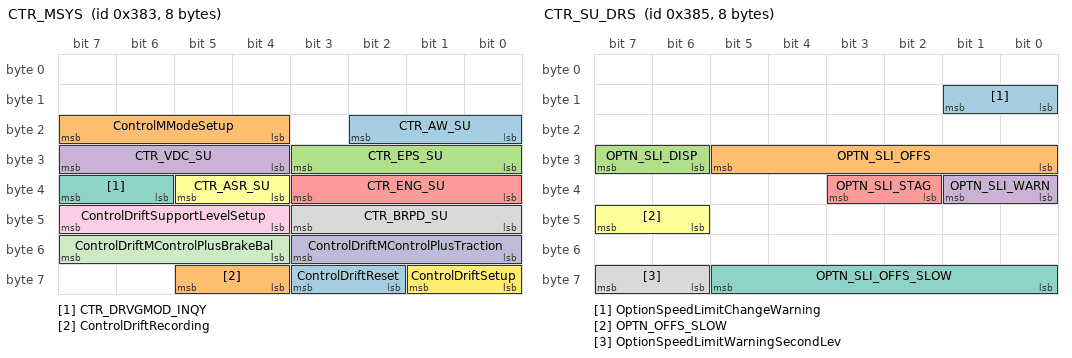
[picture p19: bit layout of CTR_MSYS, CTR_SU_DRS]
BO_ 899 CTR_MSYS: 8 ZGW
 SG_ CTR_AW_SU : 16|3@1+ (1,0) [0|7] "" DME2,DME1
 SG_ ControlMModeSetup : 20|4@1+ (1,0) [0|15] "" DME1
 SG_ CTR_EPS_SU : 24|4@1+ (1,0) [0|15] "" DME2,DME1
 SG_ CTR_VDC_SU : 28|4@1+ (1,0) [0|15] "" DME2,DME1
 SG_ CTR_ENG_SU : 32|4@1+ (1,0) [0|15] "" DME2,DME1
 SG_ CTR_ASR_SU : 36|2@1+ (1,0) [0|3] "" DME2,DME1
 SG_ CTR_DRVGMOD_INQY : 38|2@1+ (1,0) [0|3] "" DME2,DME1
 SG_ CTR_BRPD_SU : 40|4@1+ (1,0) [0|15] "" DME2,DME1
 SG_ ControlDriftSupportLevelSetup : 44|4@1+ (1,0) [0|15] "" DME1
 SG_ ControlDriftMControlPlusTraction : 48|4@1+ (1,0) [0|15] "" DME1
 SG_ ControlDriftMControlPlusBrakeBal : 52|4@1+ (1,0) [0|15] "" DME1
 SG_ ControlDriftSetup : 56|2@1+ (1,0) [0|3] "" DME1
 SG_ ControlDriftReset : 58|2@1+ (1,0) [0|3] "" DME1
 SG_ ControlDriftRecording : 60|2@1+ (1,0) [0|3] "" DME1

BO_ 640 CTR_SFYC_1: 2 ZGW
 SG_ RQ_BST_RPM_IDLG_SFYC : 12|2@1+ (1,0) [0|3] "" DME2,DME1

BO_ 223 CTR_SHLI: 2 DME1
 SG_ CTR_DISP_SHLI_SEG : 0|4@1+ (1,0) [0|15] "" ZGW,Kombi
 SG_ CTR_DISP_SHLI_FLS : 4|2@1+ (1,0) [0|3] "" ZGW,Kombi

BO_ 901 CTR_SU_DRS: 8 ZGW
 SG_ OptionSpeedLimitChangeWarning : 8|2@1+ (1,0) [0|3] "" Kombi
 SG_ OPTN_SLI_OFFS : 24|6@1+ (1,-30) [-60|0] "This unit fulfills the required AUTOSAR reference to a unit. No real unit is defined." Kombi,Kombi_Basis
 SG_ OPTN_SLI_DISP : 30|2@1+ (1,0) [0|3] "" Kombi,Kombi_Basis
 SG_ OPTN_SLI_WARN : 32|2@1+ (1,0) [0|3] "" Kombi,Kombi_Basis
 SG_ OPTN_SLI_STAG : 34|2@1+ (1,0) [0|3] "" Kombi,Kombi_Basis
 SG_ OPTN_OFFS_SLOW : 46|2@1+ (1,0) [0|3] "" Kombi,Kombi_Basis
 SG_ OPTN_SLI_OFFS_SLOW : 56|6@1+ (1,-30) [-60|0] "This unit fulfills the required AUTOSAR reference to a unit. No real unit is defined." Kombi,Kombi_Basis
 SG_ OptionSpeedLimitWarningSecondLev : 62|2@1+ (1,0) [0|3] "" Kombi

BO_TX_BU_ 517 : Kombi,Kombi_Basis;
BO_TX_BU_ 870 : Kombi,Kombi_Basis;
BO_TX_BU_ 854 : Kombi,Kombi_Basis;
BO_TX_BU_ 714 : Kombi,Kombi_Basis;
BO_TX_BU_ 946 : Kombi,Kombi_Basis;
BO_TX_BU_ 1012 : Kombi,Kombi_Basis;
BO_TX_BU_ 818 : Kombi,Kombi_Basis;
BO_TX_BU_ 658 : FLA,ZGW;
CM_ BO_ 2161115410  "Botschaft zur aktiven Fehlermeldung der SG zum Diagnosemaster, siehe LH 10000504, DMA_PA_9071. Ersetzt DID 1704 zu SP2021.
==========
PDU for active error messages from ECUs to the Diagnosemaster, q.v. LH 10000504, DMA_PA_9071. Replaces DID 1704h with SP2021.";
CM_ BO_ 2161115667  "Botschaft zur aktiven Fehlermeldung der SG zum Diagnosemaster, siehe LH 10000504, DMA_PA_9071. Ersetzt DID 1704 zu SP2021.
==========
PDU for active error messages from ECUs to the Diagnosemaster, q.v. LH 10000504, DMA_PA_9071. Replaces DID 1704h with SP2021.";
CM_ BO_ 2161116184  "Botschaft zur aktiven Fehlermeldung der SG zum Diagnosemaster, siehe LH 10000504, DMA_PA_9071. Ersetzt DID 1704 zu SP2021.
==========
PDU for active error messages from ECUs to the Diagnosemaster, q.v. LH 10000504, DMA_PA_9071. Replaces DID 1704h with SP2021.";
CM_ BO_ 2161116445  "Botschaft zur aktiven Fehlermeldung der SG zum Diagnosemaster, siehe LH 10000504, DMA_PA_9071. Ersetzt DID 1704 zu SP2021.
==========
PDU for active error messages from ECUs to the Diagnosemaster, q.v. LH 10000504, DMA_PA_9071. Replaces DID 1704h with SP2021.";
CM_ BO_ 2161117269  "Botschaft zur aktiven Fehlermeldung der SG zum Diagnosemaster, siehe LH 10000504, DMA_PA_9071. Ersetzt DID 1704 zu SP2021.
==========
PDU for active error messages from ECUs to the Diagnosemaster, q.v. LH 10000504, DMA_PA_9071. Replaces DID 1704h with SP2021.";
CM_ BO_ 818  "Die gemultiplexten PDUs werden auf Anfrage versendet, indem die PDU 0 auf Anfrage und anschlie�end alle folgenden PDUs in aufsteigender Reihenfolge mit einer Entprellzeit von 200ms untereinander versendet werden.
Die Entprellzeit von 200ms der einzelnen PDUs untereinander ist vom Sender der Nachricht zu garantieren.
Wenn w�hrend des Versendevorgangs eine neue Anfrage eintrifft, so wird der aktuelle Sendevorgang abgebrochen und die �bertragung mit der Versendung der PDU 0 mit einer Entprellzeit von 200ms erneut begonnen.
Diese gemultiplexten PDUs beschreiben die Verbrauchscharakteristik der Fahrer-Fahrzeug-Einheit �ber der Geschwindigkeit.
==========
The multiplexed PDUs are sent upon request by sending the PDU 0 upon request and subsequently all following PDUs in ascending order with a debounce time of 200 ms to each other.
The debounce time of 200 ms of the individual PDUs to each other, shall be ensured by the sender of the message.
If, during the sending procedure, a new request arrives, then the current sending procedure is canceled and the transmission is restarted with sending the PDU 0 with a debounce time of 200 ms.
These multiplexed PDUs describe the consumption characteristics of the driver-vehicle unit across speed.";
CM_ BO_ 202  "Mit dieser Nachricht werden Richtungs- und Warnblinkfunktionen im Fahrzeug angefordert.
==========
Turn indicator light and hazard warning flasher functions in the vehicle are requested with this message.";
CM_ BO_ 223  "In diesem Frame wird die Ansteuerung der Shiftlights versendet.
==========
The actuation of the shift lights is sent in this frame.";

CM_ BU_ DME1 "Use this for all petrol engines with 8 or less cylinders. For 12 cylinder engines use a second DME e.g. DME1 & DME2";
CM_ BU_ NiVi "NIVI3 ist 2018-2020 �bernahme-SG.
Nachfolger (NiVi4) wird nicht zur Initialanlage angelegt.
Es wird eine \"Night Vision 2\" erstmalig im PL6 verbaut (Aufgrund der BNDB Namenskonvention wird aber der Name NiVi beibehalten).
In diesem erfolgt aus funktionaler Sicht keine Trennung zwischen Nachtsichtkamera und Steuerger�t.
Die Kamera erfasst die Umgebung und leitet das Videosignal �ber eine LVDS-oder Differential FBAS-Verbindung an das Steuerger�t.
In diesem erfolgt die Bearbeitung der Bilder, die Weiterleitung an das Wiedergabeger�t, sowie die Bearbeitung der Einstellungen der Kamera bzw. der Einstellm�glichkeiten durch den Nutzer.
Funktionsumfang NiVi2 (Objekterkennung) f�r I250 best�tigt, bis dahin Funktionsumfang NiVi1 f�r EBG abgebildet!";
CM_ BU_ Kombi "Das Kombi ist der Check-Control-Master. Es ist berechtigt alle Fahrer-Check-Warnungen zu steuern (z.B.: T�r offen, �lstand niedrig...)";
CM_ BU_ Kombi_Basis "In the PL2 the Kombi is the check control master.  It authorises and controls the display of all driver check warnings (eg: door open, oil low...)";
CM_ BU_ Diagnosetool_FA_CAN "Diagnosetool f�r den direkten Anschlu� an den FA-CAN ab L6";
CM_ BU_ CDC_ZGW "Virtuelles Steuerger�t";
CM_ BU_ DME2 "F�r 8 und 12 Zylinder Motor";

BA_DEF_ BO_ "FrameTriggeringName" STRING;
BA_DEF_ BO_ "GenMsgCycleTime" INT 0 65535;
BA_DEF_ BO_ "GenMsgDelayTime" INT 0 65535;
BA_DEF_ BO_ "GenMsgSendType" ENUM  "cyclicX","spontanX","cyclicIfActiveX","spontanWithDelay","cyclicAndSpontanX","cyclicAndSpontanWithDelay","spontanWithRepitition","cyclicIfActiveAndSpontanWD","cyclicIfActiveFast","cyclicWithRepeatOnDemand","none";
BA_DEF_ BO_ "GenMsgStartValue" STRING;
BA_DEF_ BO_ "PduName" STRING;
BA_DEF_ BO_ "SystemMessageLongSymbol" STRING;
BA_DEF_ SG_ "CompuMethodName" STRING;
BA_DEF_ SG_ "GenSigStartValue" FLOAT 0 100000000000;
BA_DEF_ SG_ "ISignalName" STRING;
BA_DEF_ SG_ "LongName" STRING;
BA_DEF_ SG_ "SysSignalName" STRING;
BA_DEF_ SG_ "SystemSignalLongSymbol" STRING;
BA_DEF_ BU_ "NWM-Knoten" ENUM  "nein","ja";
BA_DEF_ BU_ "NWM-Stationsadresse" HEX 0 63;
BA_ "NWM-Knoten" BU_ BDC_Body 0;
BA_ "NWM-Stationsadresse" BU_ BDC_Body 0;
BA_ "NWM-Knoten" BU_ CHC 0;
BA_ "NWM-Stationsadresse" BU_ CHC 0;
BA_ "NWM-Knoten" BU_ DME1 0;
BA_ "NWM-Stationsadresse" BU_ DME1 0;
BA_ "NWM-Knoten" BU_ EME 0;
BA_ "NWM-Stationsadresse" BU_ EME 0;
BA_ "NWM-Knoten" BU_ FLA 0;
BA_ "NWM-Stationsadresse" BU_ FLA 0;
BA_ "NWM-Knoten" BU_ NiVi 0;
BA_ "NWM-Stationsadresse" BU_ NiVi 0;
BA_ "NWM-Knoten" BU_ ZGW 0;
BA_ "NWM-Stationsadresse" BU_ ZGW 0;
BA_ "NWM-Knoten" BU_ Kombi 0;
BA_ "NWM-Stationsadresse" BU_ Kombi 0;
BA_ "NWM-Knoten" BU_ Kombi_Basis 0;
BA_ "NWM-Stationsadresse" BU_ Kombi_Basis 0;
BA_ "NWM-Knoten" BU_ Diagnosetool_FA_CAN 0;
BA_ "NWM-Stationsadresse" BU_ Diagnosetool_FA_CAN 0;
BA_ "NWM-Knoten" BU_ CDC_ZGW 0;
BA_ "NWM-Stationsadresse" BU_ CDC_ZGW 0;
BA_ "NWM-Knoten" BU_ DME2 0;
BA_ "NWM-Stationsadresse" BU_ DME2 0;
BA_ "NWM-Knoten" BU_ ELV 0;
BA_ "NWM-Stationsadresse" BU_ ELV 0;
BA_ "NWM-Knoten" BU_ Gliwa_T1_Host 0;
BA_ "NWM-Stationsadresse" BU_ Gliwa_T1_Host 0;
BA_ "NWM-Knoten" BU_ FA_CAN_Dummy 0;
BA_ "NWM-Stationsadresse" BU_ FA_CAN_Dummy 0;

BA_ "FrameTriggeringName" BO_ 409 "frTrig_CAN_963411889_409_963393525_963411732_963424759_FA_CAN";
BA_ "GenMsgCycleTime" BO_ 409 20;
BA_ "GenMsgSendType" BO_ 409 0;
BA_ "GenMsgStartValue" BO_ 409 "0080bfff0000";
BA_ "PduName" BO_ 409 "ACLNX_MASSCNTR";
BA_ "FrameTriggeringName" BO_ 410 "frTrig_CAN_963411810_410_963398219_963411732_963424759_FA_CAN";
BA_ "GenMsgCycleTime" BO_ 410 20;
BA_ "GenMsgSendType" BO_ 410 0;
BA_ "GenMsgStartValue" BO_ 410 "0080bfff0000";
BA_ "PduName" BO_ 410 "ACLNY_MASSCNTR";
BA_ "FrameTriggeringName" BO_ 517 "frTrig_CAN_963411900_517_963391935_963411732_963424759_FA_CAN";
BA_ "GenMsgCycleTime" BO_ 517 2000;
BA_ "GenMsgDelayTime" BO_ 517 50;
BA_ "GenMsgSendType" BO_ 517 4;
BA_ "GenMsgStartValue" BO_ 517 "0000";
BA_ "PduName" BO_ 517 "ACOU_RQ_KI";
BA_ "FrameTriggeringName" BO_ 999 "frTrig_CAN_963412051_999_963403428_963411732_963424759_FA_CAN";
BA_ "GenMsgCycleTime" BO_ 999 5000;
BA_ "GenMsgDelayTime" BO_ 999 100;
BA_ "GenMsgSendType" BO_ 999 4;
BA_ "GenMsgStartValue" BO_ 999 "0000000000000000";
BA_ "PduName" BO_ 999 "ACTVN_CARS";
BA_ "FrameTriggeringName" BO_ 192 "frTrig_CAN_963412038_192_963393653_963411732_963424759_FA_CAN";
BA_ "GenMsgCycleTime" BO_ 192 200;
BA_ "GenMsgSendType" BO_ 192 0;
BA_ "GenMsgStartValue" BO_ 192 "0000";
BA_ "PduName" BO_ 192 "ALIVE_ZGM";
BA_ "FrameTriggeringName" BO_ 217 "frTrig_CAN_963411847_217_963396007_963411732_963424759_FA_CAN";
BA_ "GenMsgCycleTime" BO_ 217 10;
BA_ "GenMsgSendType" BO_ 217 0;
BA_ "GenMsgStartValue" BO_ 217 "0000000000f07f80";
BA_ "PduName" BO_ 217 "ANG_ACPD";
BA_ "FrameTriggeringName" BO_ 870 "frTrig_CAN_963411804_870_963403204_963411732_963424759_FA_CAN";
BA_ "GenMsgCycleTime" BO_ 870 5000;
BA_ "GenMsgDelayTime" BO_ 870 100;
BA_ "GenMsgSendType" BO_ 870 4;
BA_ "GenMsgStartValue" BO_ 870 "5000000000000000";
BA_ "PduName" BO_ 870 "ANZEIGE_KI_EXTN_ANZEIGE";
BA_ "FrameTriggeringName" BO_ 854 "frTrig_CAN_963412073_854_963401013_963411732_963424759_FA_CAN";
BA_ "GenMsgCycleTime" BO_ 854 5000;
BA_ "GenMsgDelayTime" BO_ 854 50;
BA_ "GenMsgSendType" BO_ 854 4;
BA_ "GenMsgStartValue" BO_ 854 "0000000000000000";
BA_ "PduName" BO_ 854 "ANZEIGE_KI_EXTN_ANZEIGE_2";
BA_ "FrameTriggeringName" BO_ 239 "frTrig_CAN_963411989_239_963401190_963411732_963424759_FA_CAN";
BA_ "GenMsgCycleTime" BO_ 239 20;
BA_ "GenMsgSendType" BO_ 239 0;
BA_ "GenMsgStartValue" BO_ 239 "0080008300008304";
BA_ "PduName" BO_ 239 "AVL_BRTORQ_SUM";
BA_ "FrameTriggeringName" BO_ 264 "frTrig_CAN_963412045_264_963391881_963411732_963424759_FA_CAN";
BA_ "GenMsgCycleTime" BO_ 264 100;
BA_ "GenMsgSendType" BO_ 264 0;
BA_ "GenMsgStartValue" BO_ 264 "0000000000000000";
BA_ "PduName" BO_ 264 "AVL_DT_LE";
BA_ "FrameTriggeringName" BO_ 596 "frTrig_CAN_963411953_596_963393769_963411732_963424759_FA_CAN";
BA_ "GenMsgCycleTime" BO_ 596 20;
BA_ "GenMsgSendType" BO_ 596 0;
BA_ "GenMsgStartValue" BO_ 596 "70fe70fe70fe70fe";
BA_ "PduName" BO_ 596 "AVL_RPM_WHL_UPRT";
BA_ "FrameTriggeringName" BO_ 131 "frTrig_CAN_963411835_131_963403214_963411732_963424759_FA_CAN";
BA_ "GenMsgCycleTime" BO_ 131 20;
BA_ "GenMsgSendType" BO_ 131 0;
BA_ "GenMsgStartValue" BO_ 131 "70fe70fe70fe70fe";
BA_ "PduName" BO_ 131 "AVL_RPM_WHL_UPRT";
BA_ "FrameTriggeringName" BO_ 769 "frTrig_CAN_963412114_769_963405073_963411732_963424759_FA_CAN";
BA_ "GenMsgCycleTime" BO_ 769 200;
BA_ "GenMsgSendType" BO_ 769 0;
BA_ "GenMsgStartValue" BO_ 769 "000060fa000000";
BA_ "PduName" BO_ 769 "AVL_STEA_DV";
BA_ "FrameTriggeringName" BO_ 714 "frTrig_CAN_963412015_714_963391250_963411732_963424759_FA_CAN";
BA_ "GenMsgCycleTime" BO_ 714 1000;
BA_ "GenMsgDelayTime" BO_ 714 100;
BA_ "GenMsgSendType" BO_ 714 4;
BA_ "GenMsgStartValue" BO_ 714 "5050";
BA_ "PduName" BO_ 714 "A_TEMP";
BA_ "FrameTriggeringName" BO_ 763 "frTrig_CAN_963411765_763_963401070_963411732_963424759_FA_CAN";
BA_ "GenMsgCycleTime" BO_ 763 1000;
BA_ "GenMsgDelayTime" BO_ 763 100;
BA_ "GenMsgSendType" BO_ 763 4;
BA_ "GenMsgStartValue" BO_ 763 "0000000000000000";
BA_ "PduName" BO_ 763 "BCHN_DRVMOD_DXP";
BA_ "FrameTriggeringName" BO_ 470 "frTrig_CAN_963412158_470_963388908_963411732_963424759_FA_CAN";
BA_ "GenMsgCycleTime" BO_ 470 1000;
BA_ "GenMsgDelayTime" BO_ 470 100;
BA_ "GenMsgSendType" BO_ 470 4;
BA_ "GenMsgStartValue" BO_ 470 "000000";
BA_ "PduName" BO_ 470 "BEDIENUNG_AUDIO_TEL";
BA_ "FrameTriggeringName" BO_ 696 "frTrig_CAN_963412050_696_963398947_963411732_963424759_FA_CAN";
BA_ "GenMsgDelayTime" BO_ 696 200;
BA_ "GenMsgSendType" BO_ 696 1;
BA_ "GenMsgStartValue" BO_ 696 "000000000000";
BA_ "PduName" BO_ 696 "BEDIENUNG_BC";
BA_ "FrameTriggeringName" BO_ 494 "frTrig_CAN_963411743_494_963398875_963411732_963424759_FA_CAN";
BA_ "GenMsgCycleTime" BO_ 494 1000;
BA_ "GenMsgDelayTime" BO_ 494 100;
BA_ "GenMsgSendType" BO_ 494 4;
BA_ "GenMsgStartValue" BO_ 494 "0000";
BA_ "PduName" BO_ 494 "BEDIENUNG_LENKSTOCK";
BA_ "FrameTriggeringName" BO_ 540 "frTrig_CAN_963411904_540_963394189_963411732_963424759_FA_CAN";
BA_ "GenMsgDelayTime" BO_ 540 0;
BA_ "GenMsgSendType" BO_ 540 1;
BA_ "GenMsgStartValue" BO_ 540 "00000000";
BA_ "PduName" BO_ 540 "BEDIENUNG_NIVI";
BA_ "FrameTriggeringName" BO_ 552 "frTrig_CAN_963412028_552_963395902_963411732_963424759_FA_CAN";
BA_ "GenMsgDelayTime" BO_ 552 200;
BA_ "GenMsgSendType" BO_ 552 1;
BA_ "GenMsgStartValue" BO_ 552 "0000";
BA_ "PduName" BO_ 552 "BEDIENUNG_SONDERFUNKTION";
BA_ "FrameTriggeringName" BO_ 926 "frTrig_CAN_963412087_926_963391787_963411732_963424759_FA_CAN";
BA_ "GenMsgDelayTime" BO_ 926 200;
BA_ "GenMsgSendType" BO_ 926 1;
BA_ "GenMsgStartValue" BO_ 926 "0000000000000000";
BA_ "PduName" BO_ 926 "BEDIENUNG_UHRZEIT_DATUM";
BA_ "FrameTriggeringName" BO_ 678 "frTrig_CAN_963412136_678_963395969_963411732_963424759_FA_CAN";
BA_ "GenMsgCycleTime" BO_ 678 1000;
BA_ "GenMsgDelayTime" BO_ 678 100;
BA_ "GenMsgSendType" BO_ 678 4;
BA_ "GenMsgStartValue" BO_ 678 "0000";
BA_ "PduName" BO_ 678 "BEDIENUNG_WISCHER";
BA_ "FrameTriggeringName" BO_ 502 "frTrig_CAN_963411866_502_963388818_963411732_963424759_FA_CAN";
BA_ "GenMsgCycleTime" BO_ 502 640;
BA_ "GenMsgDelayTime" BO_ 502 50;
BA_ "GenMsgSendType" BO_ 502 4;
BA_ "GenMsgStartValue" BO_ 502 "0000";
BA_ "PduName" BO_ 502 "BLINKEN";
BA_ "FrameTriggeringName" BO_ 641 "frTrig_CAN_963412036_641_963391960_963411732_963424759_FA_CAN";
BA_ "GenMsgCycleTime" BO_ 641 100;
BA_ "GenMsgSendType" BO_ 641 0;
BA_ "GenMsgStartValue" BO_ 641 "0000";
BA_ "PduName" BO_ 641 "BN_UVL";
BA_ "FrameTriggeringName" BO_ 677 "frTrig_CAN_963412052_677_963396693_963411732_963424759_FA_CAN";
BA_ "GenMsgCycleTime" BO_ 677 200;
BA_ "GenMsgSendType" BO_ 677 0;
BA_ "GenMsgStartValue" BO_ 677 "0000";
BA_ "PduName" BO_ 677 "BRIG_SURR";
BA_ "FrameTriggeringName" BO_ 946 "frTrig_CAN_963411885_946_963394209_963411732_963424759_FA_CAN";
BA_ "GenMsgCycleTime" BO_ 946 5000;
BA_ "GenMsgDelayTime" BO_ 946 200;
BA_ "GenMsgSendType" BO_ 946 4;
BA_ "GenMsgStartValue" BO_ 946 "0000000000000000";
BA_ "PduName" BO_ 946 "BS_SU_KI_4";
BA_ "FrameTriggeringName" BO_ 1012 "frTrig_CAN_963411781_1012_963398753_963411732_963424759_FA_CAN";
BA_ "GenMsgCycleTime" BO_ 1012 5000;
BA_ "GenMsgDelayTime" BO_ 1012 200;
BA_ "GenMsgSendType" BO_ 1012 4;
BA_ "GenMsgStartValue" BO_ 1012 "0000000000000000";
BA_ "PduName" BO_ 1012 "BS_SU_KI_5";
BA_ "FrameTriggeringName" BO_ 1195 "frTrig_CAN_963412097_1195_963398767_963411732_963424759_FA_CAN";
BA_ "GenMsgCycleTime" BO_ 1195 1000;
BA_ "GenMsgSendType" BO_ 1195 0;
BA_ "GenMsgStartValue" BO_ 1195 "000000000000";
BA_ "PduName" BO_ 1195 "BundleSenderKombi";
BA_ "FrameTriggeringName" BO_ 812 "frTrig_CAN_963411988_812_963389073_963411732_963424759_FA_CAN";
BA_ "GenMsgDelayTime" BO_ 812 200;
BA_ "GenMsgSendType" BO_ 812 1;
BA_ "GenMsgStartValue" BO_ 812 "0000000000000000";
BA_ "PduName" BO_ 812 "CALC_DT_NAVI";
BA_ "FrameTriggeringName" BO_ 1184 "frTrig_CAN_963411878_1184_963403392_963411732_963424759_FA_CAN";
BA_ "GenMsgDelayTime" BO_ 1184 50;
BA_ "GenMsgSendType" BO_ 1184 1;
BA_ "GenMsgStartValue" BO_ 1184 "0000000000000000";
BA_ "PduName" BO_ 1184 "CAS_ST_1";
BA_ "FrameTriggeringName" BO_ 1186 "frTrig_CAN_963412014_1186_963405836_963411732_963424759_FA_CAN";
BA_ "GenMsgDelayTime" BO_ 1186 50;
BA_ "GenMsgSendType" BO_ 1186 1;
BA_ "GenMsgStartValue" BO_ 1186 "0000000000000000";
BA_ "PduName" BO_ 1186 "CAS_ST_2";
BA_ "FrameTriggeringName" BO_ 110 "frTrig_CAN_963411820_110_963400657_963411732_963424759_FA_CAN";
BA_ "GenMsgCycleTime" BO_ 110 1000;
BA_ "GenMsgSendType" BO_ 110 0;
BA_ "GenMsgStartValue" BO_ 110 "0000000000000000";
BA_ "PduName" BO_ 110 "CCLK_COU_SYNCN_CAN";
BA_ "FrameTriggeringName" BO_ 111 "frTrig_CAN_963412091_111_963402592_963411732_963424759_FA_CAN";
BA_ "GenMsgCycleTime" BO_ 111 1000;
BA_ "GenMsgDelayTime" BO_ 111 200;
BA_ "GenMsgSendType" BO_ 111 4;
BA_ "GenMsgStartValue" BO_ 111 "0000000000000000";
BA_ "PduName" BO_ 111 "CCLK_COU_SYNCN_FLLUP";
BA_ "FrameTriggeringName" BO_ 2161115410 "frTrig_CAN_963411840_13631762_963396492_963411732_963424759_FA_CAN";
BA_ "GenMsgDelayTime" BO_ 2161115410 50;
BA_ "GenMsgSendType" BO_ 2161115410 1;
BA_ "GenMsgStartValue" BO_ 2161115410 "0000000000000000";
BA_ "PduName" BO_ 2161115410 "CEMErrorEvent_DA12h";
BA_ "FrameTriggeringName" BO_ 2161115667 "frTrig_CAN_963411841_13632019_963403222_963411732_963424759_FA_CAN";
BA_ "GenMsgDelayTime" BO_ 2161115667 50;
BA_ "GenMsgSendType" BO_ 2161115667 1;
BA_ "GenMsgStartValue" BO_ 2161115667 "0000000000000000";
BA_ "PduName" BO_ 2161115667 "CEMErrorEvent_DA13h";
BA_ "FrameTriggeringName" BO_ 2161116184 "frTrig_CAN_963411842_13632536_963396497_963411732_963424759_FA_CAN";
BA_ "GenMsgDelayTime" BO_ 2161116184 50;
BA_ "GenMsgSendType" BO_ 2161116184 1;
BA_ "GenMsgStartValue" BO_ 2161116184 "0000000000000000";
BA_ "PduName" BO_ 2161116184 "CEMErrorEvent_DA18h";
BA_ "FrameTriggeringName" BO_ 2161116445 "frTrig_CAN_963411832_13632797_963398894_963411732_963424759_FA_CAN";
BA_ "GenMsgDelayTime" BO_ 2161116445 50;
BA_ "GenMsgSendType" BO_ 2161116445 1;
BA_ "GenMsgStartValue" BO_ 2161116445 "0000000000000000";
BA_ "PduName" BO_ 2161116445 "CEMErrorEvent_DA1Dh";
BA_ "FrameTriggeringName" BO_ 2161117269 "frTrig_CAN_963411833_13633621_963396487_963411732_963424759_FA_CAN";
BA_ "GenMsgDelayTime" BO_ 2161117269 50;
BA_ "GenMsgSendType" BO_ 2161117269 1;
BA_ "GenMsgStartValue" BO_ 2161117269 "0000000000000000";
BA_ "PduName" BO_ 2161117269 "CEMErrorEvent_DA55h";
BA_ "FrameTriggeringName" BO_ 1001 "frTrig_CAN_963412077_1001_963400754_963411732_963424759_FA_CAN";
BA_ "GenMsgCycleTime" BO_ 1001 200;
BA_ "GenMsgDelayTime" BO_ 1001 40;
BA_ "GenMsgSendType" BO_ 1001 4;
BA_ "GenMsgStartValue" BO_ 1001 "0000000000000000";
BA_ "PduName" BO_ 1001 "CHGNG_ST";
BA_ "FrameTriggeringName" BO_ 762 "frTrig_CAN_963411915_762_963403062_963411732_963424759_FA_CAN";
BA_ "GenMsgCycleTime" BO_ 762 1000;
BA_ "GenMsgDelayTime" BO_ 762 100;
BA_ "GenMsgSendType" BO_ 762 4;
BA_ "GenMsgStartValue" BO_ 762 "0000000000000000";
BA_ "PduName" BO_ 762 "CHGNG_ST_2";
BA_ "FrameTriggeringName" BO_ 971 "frTrig_CAN_963411860_971_963400850_963411732_963424759_FA_CAN";
BA_ "GenMsgCycleTime" BO_ 971 5000;
BA_ "GenMsgSendType" BO_ 971 0;
BA_ "GenMsgStartValue" BO_ 971 "00000000";
BA_ "PduName" BO_ 971 "CHNO_COV_V";
BA_ "FrameTriggeringName" BO_ 876 "frTrig_CAN_963411941_876_963400614_963411732_963424759_FA_CAN";
BA_ "GenMsgCycleTime" BO_ 876 100;
BA_ "GenMsgSendType" BO_ 876 0;
BA_ "GenMsgStartValue" BO_ 876 "000080";
BA_ "PduName" BO_ 876 "CODO_LIM_V";
BA_ "FrameTriggeringName" BO_ 851 "frTrig_CAN_963411803_851_963391231_963411732_963424759_FA_CAN";
BA_ "GenMsgCycleTime" BO_ 851 10000;
BA_ "GenMsgDelayTime" BO_ 851 100;
BA_ "GenMsgSendType" BO_ 851 4;
BA_ "GenMsgStartValue" BO_ 851 "0000";
BA_ "PduName" BO_ 851 "CODO_LOKG";
BA_ "FrameTriggeringName" BO_ 1071 "frTrig_CAN_963411785_1071_963391755_963411732_963424759_FA_CAN";
BA_ "GenMsgDelayTime" BO_ 1071 200;
BA_ "GenMsgSendType" BO_ 1071 1;
BA_ "GenMsgStartValue" BO_ 1071 "0000000000000000";
BA_ "PduName" BO_ 1071 "CONFIG_MDRV_2";
BA_ "FrameTriggeringName" BO_ 775 "frTrig_CAN_963412167_775_963389588_963411732_963424759_FA_CAN";
BA_ "GenMsgCycleTime" BO_ 775 2000;
BA_ "GenMsgDelayTime" BO_ 775 100;
BA_ "GenMsgSendType" BO_ 775 4;
BA_ "GenMsgStartValue" BO_ 775 "00000000";
BA_ "PduName" BO_ 775 "CON_LVCH";
BA_ "FrameTriggeringName" BO_ 60 "frTrig_CAN_963411975_60_963393657_963411732_963424759_FA_CAN";
BA_ "GenMsgCycleTime" BO_ 60 100;
BA_ "GenMsgDelayTime" BO_ 60 20;
BA_ "GenMsgSendType" BO_ 60 4;
BA_ "GenMsgStartValue" BO_ 60 "0000000000000080";
BA_ "PduName" BO_ 60 "CON_VEH";
BA_ "FrameTriggeringName" BO_ 818 "frTrig_CAN_963412144_818_963405652_963411732_963424759_FA_CAN";
BA_ "GenMsgSendType" BO_ 818 1;
BA_ "GenMsgStartValue" BO_ 818 "00000000000000";
BA_ "PduName" BO_ 818 "COSP_INFO_DT";
BA_ "FrameTriggeringName" BO_ 908 "frTrig_CAN_963411919_908_963396521_963411732_963424759_FA_CAN";
BA_ "GenMsgCycleTime" BO_ 908 1000;
BA_ "GenMsgDelayTime" BO_ 908 200;
BA_ "GenMsgSendType" BO_ 908 4;
BA_ "GenMsgStartValue" BO_ 908 "0000";
BA_ "PduName" BO_ 908 "CTR_ACCM";
BA_ "FrameTriggeringName" BO_ 871 "frTrig_CAN_963412146_871_963394213_963411732_963424759_FA_CAN";
BA_ "GenMsgCycleTime" BO_ 871 15000;
BA_ "GenMsgDelayTime" BO_ 871 200;
BA_ "GenMsgSendType" BO_ 871 4;
BA_ "GenMsgStartValue" BO_ 871 "11000000d10100";
BA_ "PduName" BO_ 871 "CTR_ANZEIGE_BOS";
BA_ "FrameTriggeringName" BO_ 700 "frTrig_CAN_963411903_700_963403242_963411732_963424759_FA_CAN";
BA_ "GenMsgDelayTime" BO_ 700 100;
BA_ "GenMsgSendType" BO_ 700 1;
BA_ "GenMsgStartValue" BO_ 700 "0000";
BA_ "PduName" BO_ 700 "CTR_CHGINTF_CSM";
BA_ "FrameTriggeringName" BO_ 524 "frTrig_CAN_963411987_524_963391615_963411732_963424759_FA_CAN";
BA_ "GenMsgDelayTime" BO_ 524 50;
BA_ "GenMsgSendType" BO_ 524 1;
BA_ "GenMsgStartValue" BO_ 524 "0000000000000000";
BA_ "PduName" BO_ 524 "CTR_CONN_IDT_CHGNG";
BA_ "FrameTriggeringName" BO_ 978 "frTrig_CAN_963412078_978_963396559_963411732_963424759_FA_CAN";
BA_ "GenMsgCycleTime" BO_ 978 1000;
BA_ "GenMsgDelayTime" BO_ 978 50;
BA_ "GenMsgSendType" BO_ 978 4;
BA_ "GenMsgStartValue" BO_ 978 "0000";
BA_ "PduName" BO_ 978 "CTR_DIAG_OBD_ENGMG";
BA_ "FrameTriggeringName" BO_ 222 "frTrig_CAN_963411869_222_963394182_963411732_963424759_FA_CAN";
BA_ "GenMsgCycleTime" BO_ 222 100;
BA_ "GenMsgDelayTime" BO_ 222 10;
BA_ "GenMsgSendType" BO_ 222 4;
BA_ "GenMsgStartValue" BO_ 222 "0000000000000000";
BA_ "PduName" BO_ 222 "CTR_DISP_M_SYS";
BA_ "FrameTriggeringName" BO_ 853 "frTrig_CAN_963412101_853_963391800_963411732_963424759_FA_CAN";
BA_ "GenMsgDelayTime" BO_ 853 300;
BA_ "GenMsgSendType" BO_ 853 1;
BA_ "GenMsgStartValue" BO_ 853 "0000";
BA_ "PduName" BO_ 853 "CTR_DRVBH_2";
BA_ "FrameTriggeringName" BO_ 202 "frTrig_CAN_963411744_202_963402572_963411732_963424759_FA_CAN";
BA_ "GenMsgCycleTime" BO_ 202 80;
BA_ "GenMsgDelayTime" BO_ 202 40;
BA_ "GenMsgSendType" BO_ 202 4;
BA_ "GenMsgStartValue" BO_ 202 "0000000000000080";
BA_ "PduName" BO_ 202 "CTR_FN_IDC";
BA_ "FrameTriggeringName" BO_ 556 "frTrig_CAN_963412093_556_963405848_963411732_963424759_FA_CAN";
BA_ "GenMsgCycleTime" BO_ 556 34;
BA_ "GenMsgDelayTime" BO_ 556 10;
BA_ "GenMsgSendType" BO_ 556 4;
BA_ "GenMsgStartValue" BO_ 556 "f4f4440000000000";
BA_ "PduName" BO_ 556 "CTR_GZA";
BA_ "FrameTriggeringName" BO_ 548 "frTrig_CAN_963411863_548_963389438_963411732_963424759_FA_CAN";
BA_ "GenMsgCycleTime" BO_ 548 5000;
BA_ "GenMsgDelayTime" BO_ 548 50;
BA_ "GenMsgSendType" BO_ 548 4;
BA_ "GenMsgStartValue" BO_ 548 "0000000000000000";
BA_ "PduName" BO_ 548 "CTR_IDLIS";
BA_ "FrameTriggeringName" BO_ 574 "frTrig_CAN_963412156_574_963394356_963411732_963424759_FA_CAN";
BA_ "GenMsgDelayTime" BO_ 574 50;
BA_ "GenMsgSendType" BO_ 574 1;
BA_ "GenMsgStartValue" BO_ 574 "0000000000000000";
BA_ "PduName" BO_ 574 "CTR_IDT_CHGNG_CA";
BA_ "FrameTriggeringName" BO_ 747 "frTrig_CAN_963411993_747_963393549_963411732_963424759_FA_CAN";
BA_ "GenMsgCycleTime" BO_ 747 50;
BA_ "GenMsgDelayTime" BO_ 747 10;
BA_ "GenMsgSendType" BO_ 747 4;
BA_ "GenMsgStartValue" BO_ 747 "0000000000000080";
BA_ "PduName" BO_ 747 "CTR_LP_EX";
BA_ "FrameTriggeringName" BO_ 484 "frTrig_CAN_963411776_484_963391208_963411732_963424759_FA_CAN";
BA_ "GenMsgCycleTime" BO_ 484 50;
BA_ "GenMsgDelayTime" BO_ 484 10;
BA_ "GenMsgSendType" BO_ 484 4;
BA_ "GenMsgStartValue" BO_ 484 "0000000000000000";
BA_ "PduName" BO_ 484 "CTR_LP_EX_2";
BA_ "FrameTriggeringName" BO_ 773 "frTrig_CAN_963412154_773_963403435_963411732_963424759_FA_CAN";
BA_ "GenMsgDelayTime" BO_ 773 100;
BA_ "GenMsgSendType" BO_ 773 1;
BA_ "GenMsgStartValue" BO_ 773 "00000000";
BA_ "PduName" BO_ 773 "CTR_LVCH";
BA_ "FrameTriggeringName" BO_ 658 "frTrig_CAN_963411896_658_963403400_963411732_963424759_FA_CAN";
BA_ "GenMsgCycleTime" BO_ 658 4000;
BA_ "GenMsgDelayTime" BO_ 658 50;
BA_ "GenMsgSendType" BO_ 658 4;
BA_ "GenMsgStartValue" BO_ 658 "0000000000";
BA_ "PduName" BO_ 658 "CTR_MAB_ASST";
BA_ "FrameTriggeringName" BO_ 899 "frTrig_CAN_963412088_899_963401099_963411732_963424759_FA_CAN";
BA_ "GenMsgDelayTime" BO_ 899 200;
BA_ "GenMsgSendType" BO_ 899 1;
BA_ "GenMsgStartValue" BO_ 899 "0000000000000000";
BA_ "PduName" BO_ 899 "CTR_MSYS";
BA_ "FrameTriggeringName" BO_ 640 "frTrig_CAN_963411973_640_963393529_963411732_963424759_FA_CAN";
BA_ "GenMsgCycleTime" BO_ 640 500;
BA_ "GenMsgDelayTime" BO_ 640 50;
BA_ "GenMsgSendType" BO_ 640 4;
BA_ "GenMsgStartValue" BO_ 640 "0000";
BA_ "PduName" BO_ 640 "CTR_SFYC_1";
BA_ "FrameTriggeringName" BO_ 223 "frTrig_CAN_963411789_223_963389425_963411732_963424759_FA_CAN";
BA_ "GenMsgDelayTime" BO_ 223 10;
BA_ "GenMsgSendType" BO_ 223 1;
BA_ "GenMsgStartValue" BO_ 223 "0000";
BA_ "PduName" BO_ 223 "CTR_SHLI";
BA_ "FrameTriggeringName" BO_ 901 "frTrig_CAN_963411952_901_963389279_963411732_963424759_FA_CAN";
BA_ "GenMsgCycleTime" BO_ 901 1000;
BA_ "GenMsgDelayTime" BO_ 901 160;
BA_ "GenMsgSendType" BO_ 901 4;
BA_ "GenMsgStartValue" BO_ 901 "0000001e0000001e";
BA_ "PduName" BO_ 901 "CTR_SU_DRS";

BA_ "CompuMethodName" SG_ 409 CRC_ACLNX_COG "CRC8";
BA_ "ISignalName" SG_ 409 CRC_ACLNX_COG "CRC_ACLNX_COG";
BA_ "LongName" SG_ 409 CRC_ACLNX_COG "CRC_Längsbeschleunigung_Schwerpunkt";
BA_ "SysSignalName" SG_ 409 CRC_ACLNX_COG "CRC_ACLNX_COG";
BA_ "CompuMethodName" SG_ 409 ALIV_ACLNX_COG "Aliv_4";
BA_ "ISignalName" SG_ 409 ALIV_ACLNX_COG "ALIV_ACLNX_COG";
BA_ "LongName" SG_ 409 ALIV_ACLNX_COG "Alive_Längsbeschleunigung_Schwerpunkt";
BA_ "SysSignalName" SG_ 409 ALIV_ACLNX_COG "ALIV_ACLNX_COG";
BA_ "ISignalName" SG_ 409 ACLNX_MASSCNTR_dummy_12_15 "ACLNX_MASSCNTR_dummy_12_15";
BA_ "LongName" SG_ 409 ACLNX_MASSCNTR_dummy_12_15 "ACLNX_MASSCNTR_dummy_12_15";
BA_ "SysSignalName" SG_ 409 ACLNX_MASSCNTR_dummy_12_15 "ACLNX_MASSCNTR_dummy_12_15";
BA_ "CompuMethodName" SG_ 409 ACLNX_COG "ACLNX_COG";
BA_ "GenSigStartValue" SG_ 409 ACLNX_COG -65;
BA_ "ISignalName" SG_ 409 ACLNX_COG "ACLNX_COG";
BA_ "LongName" SG_ 409 ACLNX_COG "Längsbeschleunigung_Schwerpunkt";
BA_ "SysSignalName" SG_ 409 ACLNX_COG "ACLNX_COG";
BA_ "CompuMethodName" SG_ 409 ACLNX_COG_ERR_AMP "ACLNX_COG_ERR_AMP";
BA_ "ISignalName" SG_ 409 ACLNX_COG_ERR_AMP "ACLNX_COG_ERR_AMP";
BA_ "LongName" SG_ 409 ACLNX_COG_ERR_AMP "Längsbeschleunigung_Schwerpunkt_Fehler_Amplitude";
BA_ "SysSignalName" SG_ 409 ACLNX_COG_ERR_AMP "ACLNX_COG_ERR_AMP";
BA_ "CompuMethodName" SG_ 409 QU_ACLNX_COG "QU_ACLNX_Schwerpunkt2";
BA_ "ISignalName" SG_ 409 QU_ACLNX_COG "QU_ACLNX_COG";
BA_ "LongName" SG_ 409 QU_ACLNX_COG "Qualifier_Längsbeschleunigung_Schwerpunkt";
BA_ "SysSignalName" SG_ 409 QU_ACLNX_COG "QU_ACLNX_COG";
BA_ "CompuMethodName" SG_ 410 CRC_ACLNY_COG "CRC8";
BA_ "ISignalName" SG_ 410 CRC_ACLNY_COG "CRC_ACLNY_COG";
BA_ "LongName" SG_ 410 CRC_ACLNY_COG "CRC_Querbeschleunigung_Schwerpunkt";
BA_ "SysSignalName" SG_ 410 CRC_ACLNY_COG "CRC_ACLNY_COG";
BA_ "CompuMethodName" SG_ 410 ALIV_ACLNY_COG "Aliv_4";
BA_ "ISignalName" SG_ 410 ALIV_ACLNY_COG "ALIV_ACLNY_COG";
BA_ "LongName" SG_ 410 ALIV_ACLNY_COG "Alive_Querbeschleunigung_Schwerpunkt";
BA_ "SysSignalName" SG_ 410 ALIV_ACLNY_COG "ALIV_ACLNY_COG";
BA_ "ISignalName" SG_ 410 ACLNY_MASSCNTR_dummy_12_15 "ACLNY_MASSCNTR_dummy_12_15";
BA_ "LongName" SG_ 410 ACLNY_MASSCNTR_dummy_12_15 "ACLNY_MASSCNTR_dummy_12_15";
BA_ "SysSignalName" SG_ 410 ACLNY_MASSCNTR_dummy_12_15 "ACLNY_MASSCNTR_dummy_12_15";
BA_ "CompuMethodName" SG_ 410 ACLNY_COG "ACLNY_COG";
BA_ "GenSigStartValue" SG_ 410 ACLNY_COG -65;
BA_ "ISignalName" SG_ 410 ACLNY_COG "ACLNY_COG";
BA_ "LongName" SG_ 410 ACLNY_COG "Querbeschleunigung_Schwerpunkt";
BA_ "SysSignalName" SG_ 410 ACLNY_COG "ACLNY_COG";
BA_ "CompuMethodName" SG_ 410 ACLNY_COG_ERR_AMP "ACLNY_COG_ERR_AMP";
BA_ "ISignalName" SG_ 410 ACLNY_COG_ERR_AMP "ACLNY_COG_ERR_AMP";
BA_ "LongName" SG_ 410 ACLNY_COG_ERR_AMP "Querbeschleunigung_Schwerpunkt_Fehler_Amplitude";
BA_ "SysSignalName" SG_ 410 ACLNY_COG_ERR_AMP "ACLNY_COG_ERR_AMP";
BA_ "CompuMethodName" SG_ 410 QU_ACLNY_COG "QU_ACLNY_COG";
BA_ "ISignalName" SG_ 410 QU_ACLNY_COG "QU_ACLNY_COG";
BA_ "LongName" SG_ 410 QU_ACLNY_COG "Qualifier_Querbeschleunigung_Schwerpunkt";
BA_ "SysSignalName" SG_ 410 QU_ACLNY_COG "QU_ACLNY_COG";
BA_ "CompuMethodName" SG_ 517 RQ_ACOU_KI "RQ_ACOU_KI";
BA_ "ISignalName" SG_ 517 RQ_ACOU_KI "RQ_ACOU_KI";
BA_ "LongName" SG_ 517 RQ_ACOU_KI "Anforderung_Akustik_Kombi";
BA_ "SysSignalName" SG_ 517 RQ_ACOU_KI "RQ_ACOU_KI";
BA_ "CompuMethodName" SG_ 999 CTR_ACTVN_CARS "CTR_ACTVN_CARS";
BA_ "ISignalName" SG_ 999 CTR_ACTVN_CARS "CTR_ACTVN_CARS";
BA_ "LongName" SG_ 999 CTR_ACTVN_CARS "Steuerung_Aktivierung_CarSharing";
BA_ "SysSignalName" SG_ 999 CTR_ACTVN_CARS "CTR_ACTVN_CARS";
BA_ "CompuMethodName" SG_ 999 CTR_FBD_CARS "CTR_FBD_CARS";
BA_ "ISignalName" SG_ 999 CTR_FBD_CARS "CTR_FBD_CARS";
BA_ "LongName" SG_ 999 CTR_FBD_CARS "Steuerung_Funkempfänger_CarSharing";
BA_ "SysSignalName" SG_ 999 CTR_FBD_CARS "CTR_FBD_CARS";
BA_ "CompuMethodName" SG_ 999 CTR_PRSL_PROFIL_CARS "CTR_PRSL_PROFIL_CARS";
BA_ "ISignalName" SG_ 999 CTR_PRSL_PROFIL_CARS "CTR_PRSL_PROFIL_CARS";
BA_ "LongName" SG_ 999 CTR_PRSL_PROFIL_CARS "Steuerung_Personalisierung_Profil_CarSharing";
BA_ "SysSignalName" SG_ 999 CTR_PRSL_PROFIL_CARS "CTR_PRSL_PROFIL_CARS";
BA_ "CompuMethodName" SG_ 192 ALIV_COU_ZGM "ENUM_4_noIniVal_noDflVal_15_noQuant_noOffs_plainNumber_noRng_3";
BA_ "ISignalName" SG_ 192 ALIV_COU_ZGM "ALIV_COU_ZGM";
BA_ "LongName" SG_ 192 ALIV_COU_ZGM "Alive_Zähler_ZGM";
BA_ "SysSignalName" SG_ 192 ALIV_COU_ZGM "ALIV_COU_ZGM";
BA_ "CompuMethodName" SG_ 192 INFO_BUS_ZGM "INFO_BUS_ZGM";
BA_ "ISignalName" SG_ 192 INFO_BUS_ZGM "INFO_BUS_ZGM";
BA_ "LongName" SG_ 192 INFO_BUS_ZGM "Information_Bus_ZGM";
BA_ "SysSignalName" SG_ 192 INFO_BUS_ZGM "INFO_BUS_ZGM";
BA_ "CompuMethodName" SG_ 217 CRC_ANG_ACPD "CRC8";
BA_ "ISignalName" SG_ 217 CRC_ANG_ACPD "CRC_ANG_ACPD";
BA_ "LongName" SG_ 217 CRC_ANG_ACPD "CRC_Winkel_Fahrpedal";
BA_ "SysSignalName" SG_ 217 CRC_ANG_ACPD "CRC_ANG_ACPD";
BA_ "CompuMethodName" SG_ 217 ALIV_ANG_ACPD "Aliv_4";
BA_ "ISignalName" SG_ 217 ALIV_ANG_ACPD "ALIV_ANG_ACPD";
BA_ "LongName" SG_ 217 ALIV_ANG_ACPD "Alive_Winkel_Fahrpedal";
BA_ "SysSignalName" SG_ 217 ALIV_ANG_ACPD "ALIV_ANG_ACPD";
BA_ "CompuMethodName" SG_ 217 ST_ECU_ANG_ACPD "ST_ECU";
BA_ "ISignalName" SG_ 217 ST_ECU_ANG_ACPD "ST_ECU_ANG_ACPD";
BA_ "LongName" SG_ 217 ST_ECU_ANG_ACPD "Status_STG_Winkel_Fahrpedal";
BA_ "SysSignalName" SG_ 217 ST_ECU_ANG_ACPD "ST_ECU_ANG_ACPD";
BA_ "CompuMethodName" SG_ 217 AVL_ANG_ACPD "ANG_ACPD_EXT";
BA_ "ISignalName" SG_ 217 AVL_ANG_ACPD "AVL_ANG_ACPD";
BA_ "LongName" SG_ 217 AVL_ANG_ACPD "actual-value_angle_accelerator-pedal";
BA_ "SysSignalName" SG_ 217 AVL_ANG_ACPD "AVL_ANG_ACPD";
BA_ "CompuMethodName" SG_ 217 QU_AVL_ANG_ACPD "QU_AVL_ANG_ACPD";
BA_ "ISignalName" SG_ 217 QU_AVL_ANG_ACPD "QU_AVL_ANG_ACPD";
BA_ "LongName" SG_ 217 QU_AVL_ANG_ACPD "Qualifier_Ist_Winkel_Fahrpedal";
BA_ "SysSignalName" SG_ 217 QU_AVL_ANG_ACPD "QU_AVL_ANG_ACPD";
BA_ "CompuMethodName" SG_ 217 AVL_ANG_ACPD_VIRT "ANG_ACPD_EXT";
BA_ "ISignalName" SG_ 217 AVL_ANG_ACPD_VIRT "AVL_ANG_ACPD_VIRT";
BA_ "LongName" SG_ 217 AVL_ANG_ACPD_VIRT "Ist_Winkel_Fahrpedal_Virtuell";
BA_ "SysSignalName" SG_ 217 AVL_ANG_ACPD_VIRT "AVL_ANG_ACPD_VIRT";
BA_ "CompuMethodName" SG_ 217 GRAD_AVL_ANG_ACPD "GRAD_AVL_ANG_ACPD";
BA_ "GenSigStartValue" SG_ 217 GRAD_AVL_ANG_ACPD 2047;
BA_ "ISignalName" SG_ 217 GRAD_AVL_ANG_ACPD "GRAD_AVL_ANG_ACPD";
BA_ "LongName" SG_ 217 GRAD_AVL_ANG_ACPD "Gradient_Ist_Winkel_Fahrpedal";
BA_ "SysSignalName" SG_ 217 GRAD_AVL_ANG_ACPD "GRAD_AVL_ANG_ACPD";
BA_ "CompuMethodName" SG_ 217 ST_INTF_DRASY "ST_INTF_DRASY";
BA_ "ISignalName" SG_ 217 ST_INTF_DRASY "ST_INTF_DRASY";
BA_ "LongName" SG_ 217 ST_INTF_DRASY "Status_Schnittstelle_Fahrerassistenzsystem";
BA_ "SysSignalName" SG_ 217 ST_INTF_DRASY "ST_INTF_DRASY";
BA_ "CompuMethodName" SG_ 217 ECO_ANG_ACPD "ECO_ANG_ACPD";
BA_ "ISignalName" SG_ 217 ECO_ANG_ACPD "ECO_ANG_ACPD";
BA_ "LongName" SG_ 217 ECO_ANG_ACPD "ECO_angle_accelerator-pedal";
BA_ "SysSignalName" SG_ 217 ECO_ANG_ACPD "ECO_ANG_ACPD";
BA_ "ISignalName" SG_ 217 ANG_ACPD_dummy_62_63 "ANG_ACPD_dummy_62_63";
BA_ "LongName" SG_ 217 ANG_ACPD_dummy_62_63 "ANG_ACPD_dummy_62_63";
BA_ "SysSignalName" SG_ 217 ANG_ACPD_dummy_62_63 "ANG_ACPD_dummy_62_63";
BA_ "CompuMethodName" SG_ 870 DISP_TEMP_EX "DISP_TEMP_EX";
BA_ "GenSigStartValue" SG_ 870 DISP_TEMP_EX 80;
BA_ "ISignalName" SG_ 870 DISP_TEMP_EX "DISP_TEMP_EX";
BA_ "LongName" SG_ 870 DISP_TEMP_EX "Anzeige_Temperatur_Außen";
BA_ "SysSignalName" SG_ 870 DISP_TEMP_EX "DISP_TEMP_EX";
BA_ "CompuMethodName" SG_ 870 DISP_RNG "DISP_RNG";
BA_ "ISignalName" SG_ 870 DISP_RNG "DISP_RNG";
BA_ "LongName" SG_ 870 DISP_RNG "Anzeige_Reichweite";
BA_ "SysSignalName" SG_ 870 DISP_RNG "DISP_RNG";
BA_ "CompuMethodName" SG_ 870 ST_UN_TEMP_KI "ST_UN_TEMP_KI";
BA_ "ISignalName" SG_ 870 ST_UN_TEMP_KI "ST_UN_TEMP_KI";
BA_ "LongName" SG_ 870 ST_UN_TEMP_KI "status_unit-of-measurement_temperature_instrument-pack";
BA_ "SysSignalName" SG_ 870 ST_UN_TEMP_KI "ST_UN_TEMP_KI";
BA_ "CompuMethodName" SG_ 870 DISP_RNG_ECO "DISP_RNG_ECO";
BA_ "ISignalName" SG_ 870 DISP_RNG_ECO "DISP_RNG_ECO";
BA_ "LongName" SG_ 870 DISP_RNG_ECO "Anzeige_Reichweite_ECO";
BA_ "SysSignalName" SG_ 870 DISP_RNG_ECO "DISP_RNG_ECO";
BA_ "CompuMethodName" SG_ 870 DISP_RNG_ECO_WON "DISP_RNG_ECO_WON";
BA_ "ISignalName" SG_ 870 DISP_RNG_ECO_WON "DISP_RNG_ECO_WON";
BA_ "LongName" SG_ 870 DISP_RNG_ECO_WON "Anzeige_Reichweite_ECO_Gewonnen";
BA_ "SysSignalName" SG_ 870 DISP_RNG_ECO_WON "DISP_RNG_ECO_WON";
BA_ "CompuMethodName" SG_ 854 DISP_RNG_MAX "DISP_RNG_MAX";
BA_ "ISignalName" SG_ 854 DISP_RNG_MAX "DISP_RNG_MAX";
BA_ "LongName" SG_ 854 DISP_RNG_MAX "Anzeige_Reichweite_Maximal";
BA_ "SysSignalName" SG_ 854 DISP_RNG_MAX "DISP_RNG_MAX";
BA_ "CompuMethodName" SG_ 854 DISP_RNG_EVEH "RNG_DISP";
BA_ "ISignalName" SG_ 854 DISP_RNG_EVEH "DISP_RNG_EVEH";
BA_ "LongName" SG_ 854 DISP_RNG_EVEH "Anzeige_Reichweite_Elektrisches-Fahrzeug";
BA_ "SysSignalName" SG_ 854 DISP_RNG_EVEH "DISP_RNG_EVEH";
BA_ "CompuMethodName" SG_ 854 COSP_AVR_EVEH_BC_1 "COSP_AVR_EVEH_BC";
BA_ "ISignalName" SG_ 854 COSP_AVR_EVEH_BC_1 "COSP_AVR_EVEH_BC_1";
BA_ "LongName" SG_ 854 COSP_AVR_EVEH_BC_1 "Verbrauch_Durchschnitt_Elektrisches-Fahrzeug_BC_1";
BA_ "SysSignalName" SG_ 854 COSP_AVR_EVEH_BC_1 "COSP_AVR_EVEH_BC_1";
BA_ "CompuMethodName" SG_ 854 COSP_AVR_EVEH_BC_2 "COSP_AVR_EVEH_BC";
BA_ "ISignalName" SG_ 854 COSP_AVR_EVEH_BC_2 "COSP_AVR_EVEH_BC_2";
BA_ "LongName" SG_ 854 COSP_AVR_EVEH_BC_2 "Verbrauch_Durchschnitt_Elektrisches-Fahrzeug_BC_2";
BA_ "SysSignalName" SG_ 854 COSP_AVR_EVEH_BC_2 "COSP_AVR_EVEH_BC_2";
BA_ "CompuMethodName" SG_ 854 UN_COSP_EVEH_BC "UN_COSP_EVEH_BC";
BA_ "ISignalName" SG_ 854 UN_COSP_EVEH_BC "UN_COSP_EVEH_BC";
BA_ "LongName" SG_ 854 UN_COSP_EVEH_BC "Einheit_Verbrauch_Elektrisches-Fahrzeug_BC";
BA_ "SysSignalName" SG_ 854 UN_COSP_EVEH_BC "UN_COSP_EVEH_BC";
BA_ "CompuMethodName" SG_ 239 CRC_AVL_BRTORQ_SUM "CRC8";
BA_ "ISignalName" SG_ 239 CRC_AVL_BRTORQ_SUM "CRC_AVL_BRTORQ_SUM";
BA_ "LongName" SG_ 239 CRC_AVL_BRTORQ_SUM "CRC_Ist_Bremsmoment_Summe";
BA_ "SysSignalName" SG_ 239 CRC_AVL_BRTORQ_SUM "CRC_AVL_BRTORQ_SUM";
BA_ "CompuMethodName" SG_ 239 ALIV_AVL_BRTORQ_SUM "Aliv_4";
BA_ "ISignalName" SG_ 239 ALIV_AVL_BRTORQ_SUM "ALIV_AVL_BRTORQ_SUM";
BA_ "LongName" SG_ 239 ALIV_AVL_BRTORQ_SUM "Alive_Ist_Bremsmoment_Summe";
BA_ "SysSignalName" SG_ 239 ALIV_AVL_BRTORQ_SUM "ALIV_AVL_BRTORQ_SUM";
BA_ "ISignalName" SG_ 239 AVL_BRTORQ_SUM_dummy_12_15 "AVL_BRTORQ_SUM_dummy_12_15";
BA_ "LongName" SG_ 239 AVL_BRTORQ_SUM_dummy_12_15 "AVL_BRTORQ_SUM_dummy_12_15";
BA_ "SysSignalName" SG_ 239 AVL_BRTORQ_SUM_dummy_12_15 "AVL_BRTORQ_SUM_dummy_12_15";
BA_ "CompuMethodName" SG_ 239 AVL_BRTORQ_SUM "WMOM_BRK";
BA_ "GenSigStartValue" SG_ 239 AVL_BRTORQ_SUM -32000;
BA_ "ISignalName" SG_ 239 AVL_BRTORQ_SUM "AVL_BRTORQ_SUM";
BA_ "LongName" SG_ 239 AVL_BRTORQ_SUM "Ist_Bremsmoment_Summe";
BA_ "SysSignalName" SG_ 239 AVL_BRTORQ_SUM "AVL_BRTORQ_SUM";
BA_ "CompuMethodName" SG_ 239 QU_AVL_BRTORQ_SUM "QU_AVL_BRTORQ_SUM";
BA_ "ISignalName" SG_ 239 QU_AVL_BRTORQ_SUM "QU_AVL_BRTORQ_SUM";
BA_ "LongName" SG_ 239 QU_AVL_BRTORQ_SUM "Qualifier_Ist_Bremsmoment_Summe";
BA_ "SysSignalName" SG_ 239 QU_AVL_BRTORQ_SUM "QU_AVL_BRTORQ_SUM";
BA_ "CompuMethodName" SG_ 239 QU_AVL_BRTORQ_SUM_DVCH "QU_AVL_BRTORQ_SUM_DVCH";
BA_ "ISignalName" SG_ 239 QU_AVL_BRTORQ_SUM_DVCH "QU_AVL_BRTORQ_SUM_DVCH";
BA_ "LongName" SG_ 239 QU_AVL_BRTORQ_SUM_DVCH "Qualifier_Ist_Bremsmoment_Summe_Fahrerwunsch";
BA_ "SysSignalName" SG_ 239 QU_AVL_BRTORQ_SUM_DVCH "QU_AVL_BRTORQ_SUM_DVCH";
BA_ "CompuMethodName" SG_ 239 AVL_BRTORQ_SUM_DVCH "WMOM_BRK";
BA_ "GenSigStartValue" SG_ 239 AVL_BRTORQ_SUM_DVCH -32000;
BA_ "ISignalName" SG_ 239 AVL_BRTORQ_SUM_DVCH "AVL_BRTORQ_SUM_DVCH";
BA_ "LongName" SG_ 239 AVL_BRTORQ_SUM_DVCH "Ist_Bremsmoment_Summe_Fahrerwunsch";
BA_ "SysSignalName" SG_ 239 AVL_BRTORQ_SUM_DVCH "AVL_BRTORQ_SUM_DVCH";
BA_ "CompuMethodName" SG_ 239 AVL_BRTORQ_SUM_DVCH_RAW "AVL_BRTORQ_SUM_DVCH_RAW";
BA_ "GenSigStartValue" SG_ 239 AVL_BRTORQ_SUM_DVCH_RAW -252;
BA_ "ISignalName" SG_ 239 AVL_BRTORQ_SUM_DVCH_RAW "AVL_BRTORQ_SUM_DVCH_RAW";
BA_ "LongName" SG_ 239 AVL_BRTORQ_SUM_DVCH_RAW "Ist_Bremsmoment_Summe_Fahrerwunsch_Roh";
BA_ "SysSignalName" SG_ 239 AVL_BRTORQ_SUM_DVCH_RAW "AVL_BRTORQ_SUM_DVCH_RAW";
BA_ "CompuMethodName" SG_ 264 AVL_OPMO_CHGE "AVL_OPMO_CHGE";
BA_ "ISignalName" SG_ 264 AVL_OPMO_CHGE "AVL_OPMO_CHGE";
BA_ "LongName" SG_ 264 AVL_OPMO_CHGE "Ist_Betriebsart_Ladeelektronik";
BA_ "SysSignalName" SG_ 264 AVL_OPMO_CHGE "AVL_OPMO_CHGE";
BA_ "CompuMethodName" SG_ 596 AVL_RPM_WHL_RLH "AVL_RPM_WHL";
BA_ "GenSigStartValue" SG_ 596 AVL_RPM_WHL_RLH -400;
BA_ "ISignalName" SG_ 596 AVL_RPM_WHL_RLH "AVL_RPM_WHL_RLH";
BA_ "LongName" SG_ 596 AVL_RPM_WHL_RLH "Ist_Drehzahl_Rad_HL";
BA_ "SysSignalName" SG_ 596 AVL_RPM_WHL_RLH "AVL_RPM_WHL_RLH";
BA_ "CompuMethodName" SG_ 596 AVL_RPM_WHL_RRH "AVL_RPM_WHL";
BA_ "GenSigStartValue" SG_ 596 AVL_RPM_WHL_RRH -400;
BA_ "ISignalName" SG_ 596 AVL_RPM_WHL_RRH "AVL_RPM_WHL_RRH";
BA_ "LongName" SG_ 596 AVL_RPM_WHL_RRH "Ist_Drehzahl_Rad_HR";
BA_ "SysSignalName" SG_ 596 AVL_RPM_WHL_RRH "AVL_RPM_WHL_RRH";
BA_ "CompuMethodName" SG_ 596 AVL_RPM_WHL_FLH "AVL_RPM_WHL";
BA_ "GenSigStartValue" SG_ 596 AVL_RPM_WHL_FLH -400;
BA_ "ISignalName" SG_ 596 AVL_RPM_WHL_FLH "AVL_RPM_WHL_FLH";
BA_ "LongName" SG_ 596 AVL_RPM_WHL_FLH "Ist_Drehzahl_Rad_VL";
BA_ "SysSignalName" SG_ 596 AVL_RPM_WHL_FLH "AVL_RPM_WHL_FLH";
BA_ "CompuMethodName" SG_ 596 AVL_RPM_WHL_FRH "AVL_RPM_WHL";
BA_ "GenSigStartValue" SG_ 596 AVL_RPM_WHL_FRH -400;
BA_ "ISignalName" SG_ 596 AVL_RPM_WHL_FRH "AVL_RPM_WHL_FRH";
BA_ "LongName" SG_ 596 AVL_RPM_WHL_FRH "Ist_Drehzahl_Rad_VR";
BA_ "SysSignalName" SG_ 596 AVL_RPM_WHL_FRH "AVL_RPM_WHL_FRH";
BA_ "CompuMethodName" SG_ 131 AVL_RPM_WHL_RLH "AVL_RPM_WHL";
BA_ "GenSigStartValue" SG_ 131 AVL_RPM_WHL_RLH -400;
BA_ "ISignalName" SG_ 131 AVL_RPM_WHL_RLH "AVL_RPM_WHL_RLH";
BA_ "LongName" SG_ 131 AVL_RPM_WHL_RLH "Ist_Drehzahl_Rad_HL";
BA_ "SysSignalName" SG_ 131 AVL_RPM_WHL_RLH "AVL_RPM_WHL_RLH";
BA_ "CompuMethodName" SG_ 131 AVL_RPM_WHL_RRH "AVL_RPM_WHL";
BA_ "GenSigStartValue" SG_ 131 AVL_RPM_WHL_RRH -400;
BA_ "ISignalName" SG_ 131 AVL_RPM_WHL_RRH "AVL_RPM_WHL_RRH";
BA_ "LongName" SG_ 131 AVL_RPM_WHL_RRH "Ist_Drehzahl_Rad_HR";
BA_ "SysSignalName" SG_ 131 AVL_RPM_WHL_RRH "AVL_RPM_WHL_RRH";
BA_ "CompuMethodName" SG_ 131 AVL_RPM_WHL_FLH "AVL_RPM_WHL";
BA_ "GenSigStartValue" SG_ 131 AVL_RPM_WHL_FLH -400;
BA_ "ISignalName" SG_ 131 AVL_RPM_WHL_FLH "AVL_RPM_WHL_FLH";
BA_ "LongName" SG_ 131 AVL_RPM_WHL_FLH "Ist_Drehzahl_Rad_VL";
BA_ "SysSignalName" SG_ 131 AVL_RPM_WHL_FLH "AVL_RPM_WHL_FLH";
BA_ "CompuMethodName" SG_ 131 AVL_RPM_WHL_FRH "AVL_RPM_WHL";
BA_ "GenSigStartValue" SG_ 131 AVL_RPM_WHL_FRH -400;
BA_ "ISignalName" SG_ 131 AVL_RPM_WHL_FRH "AVL_RPM_WHL_FRH";
BA_ "LongName" SG_ 131 AVL_RPM_WHL_FRH "Ist_Drehzahl_Rad_VR";
BA_ "SysSignalName" SG_ 131 AVL_RPM_WHL_FRH "AVL_RPM_WHL_FRH";
BA_ "CompuMethodName" SG_ 769 CTR_HOFF_RCOG_VEHGD "CTR_HOFF_RCOG";
BA_ "ISignalName" SG_ 769 CTR_HOFF_RCOG_VEHGD "CTR_HOFF_RCOG_VEHGD";
BA_ "LongName" SG_ 769 CTR_HOFF_RCOG_VEHGD "Steuerung_Hands-Off_Erkennung_Fahrzeugführung";
BA_ "SysSignalName" SG_ 769 CTR_HOFF_RCOG_VEHGD "CTR_HOFF_RCOG_VEHGD";
BA_ "CompuMethodName" SG_ 769 AVL_STEA_DV "STEA_Fahrer";
BA_ "GenSigStartValue" SG_ 769 AVL_STEA_DV -1440;
BA_ "ISignalName" SG_ 769 AVL_STEA_DV "AVL_STEA_DV";
BA_ "LongName" SG_ 769 AVL_STEA_DV "Ist_Lenkwinkel_Fahrer";
BA_ "SysSignalName" SG_ 769 AVL_STEA_DV "AVL_STEA_DV";
BA_ "CompuMethodName" SG_ 769 QU_AVL_STEA_DV "QU_AVL_STEA_DV_1";
BA_ "ISignalName" SG_ 769 QU_AVL_STEA_DV "QU_AVL_STEA_DV";
BA_ "LongName" SG_ 769 QU_AVL_STEA_DV "Qualifier_Ist_Lenkwinkel_Fahrer";
BA_ "SysSignalName" SG_ 769 QU_AVL_STEA_DV "QU_AVL_STEA_DV";
BA_ "CompuMethodName" SG_ 714 TEMP_EX "UI_8_noIniVal_noDflVal_255_0_50s_MI_40_noEnc_hasRng";
BA_ "GenSigStartValue" SG_ 714 TEMP_EX 80;
BA_ "ISignalName" SG_ 714 TEMP_EX "TEMP_EX";
BA_ "LongName" SG_ 714 TEMP_EX "temperature_exterior";
BA_ "SysSignalName" SG_ 714 TEMP_EX "TEMP_EX";
BA_ "CompuMethodName" SG_ 714 TEMP_EX_UNFILT "TEMP_EX_UNFILT";
BA_ "GenSigStartValue" SG_ 714 TEMP_EX_UNFILT 80;
BA_ "ISignalName" SG_ 714 TEMP_EX_UNFILT "TEMP_EX_UNFILT";
BA_ "LongName" SG_ 714 TEMP_EX_UNFILT "Temperatur_Außen_Ungefiltert";
BA_ "SysSignalName" SG_ 714 TEMP_EX_UNFILT "TEMP_EX_UNFILT";
BA_ "CompuMethodName" SG_ 763 RQ_MOD_DXP "RQ_MOD_DXP";
BA_ "ISignalName" SG_ 763 RQ_MOD_DXP "RQ_MOD_DXP";
BA_ "LongName" SG_ 763 RQ_MOD_DXP "Anforderung_Modus_Fahrerlebnis";
BA_ "SysSignalName" SG_ 763 RQ_MOD_DXP "RQ_MOD_DXP";
BA_ "CompuMethodName" SG_ 763 SU_ILK_MOD_DXP "SU_ILK_MOD_DXP";
BA_ "ISignalName" SG_ 763 SU_ILK_MOD_DXP "SU_ILK_MOD_DXP";
BA_ "LongName" SG_ 763 SU_ILK_MOD_DXP "Konfiguration_Sperre_Modus_Fahrerlebnis";
BA_ "SysSignalName" SG_ 763 SU_ILK_MOD_DXP "SU_ILK_MOD_DXP";
BA_ "CompuMethodName" SG_ 763 ST_AVAI_EWLD_DXP "ST_AVAI_DXP";
BA_ "ISignalName" SG_ 763 ST_AVAI_EWLD_DXP "ST_AVAI_EWLD_DXP";
BA_ "LongName" SG_ 763 ST_AVAI_EWLD_DXP "Status_Verfügbarkeit_Electric-Welt_Fahrerlebnis";
BA_ "SysSignalName" SG_ 763 ST_AVAI_EWLD_DXP "ST_AVAI_EWLD_DXP";
BA_ "CompuMethodName" SG_ 763 ST_AVAI_BTCTR_DXP "ST_AVAI_DXP";
BA_ "ISignalName" SG_ 763 ST_AVAI_BTCTR_DXP "ST_AVAI_BTCTR_DXP";
BA_ "LongName" SG_ 763 ST_AVAI_BTCTR_DXP "Status_Verfügbarkeit_BatteryControl_Fahrerlebnis";
BA_ "SysSignalName" SG_ 763 ST_AVAI_BTCTR_DXP "ST_AVAI_BTCTR_DXP";
BA_ "CompuMethodName" SG_ 763 ST_AVAI_OWLD_DXP "ST_AVAI_DXP";
BA_ "ISignalName" SG_ 763 ST_AVAI_OWLD_DXP "ST_AVAI_OWLD_DXP";
BA_ "LongName" SG_ 763 ST_AVAI_OWLD_DXP "Status_Verfügbarkeit_Andere-Welt_Fahrerlebnis";
BA_ "SysSignalName" SG_ 763 ST_AVAI_OWLD_DXP "ST_AVAI_OWLD_DXP";
BA_ "CompuMethodName" SG_ 470 OP_PUBU_TEL_STW "OP_PUBU_TEL_STW";
BA_ "ISignalName" SG_ 470 OP_PUBU_TEL_STW "OP_PUBU_TEL_STW";
BA_ "LongName" SG_ 470 OP_PUBU_TEL_STW "Bedienung_Taster_Telefon_Lenkrad";
BA_ "SysSignalName" SG_ 470 OP_PUBU_TEL_STW "OP_PUBU_TEL_STW";
BA_ "CompuMethodName" SG_ 470 OP_PUBU_AUD_AVOL_STW "AUD_AVOL";
BA_ "ISignalName" SG_ 470 OP_PUBU_AUD_AVOL_STW "OP_PUBU_AUD_AVOL_STW";
BA_ "LongName" SG_ 470 OP_PUBU_AUD_AVOL_STW "Bedienung_Taster_Audio_Lautstärke_Lenkrad";
BA_ "SysSignalName" SG_ 470 OP_PUBU_AUD_AVOL_STW "OP_PUBU_AUD_AVOL_STW";
BA_ "CompuMethodName" SG_ 470 OP_PUBU_SKP_STW "OP_PUBU_SKP_STW";
BA_ "ISignalName" SG_ 470 OP_PUBU_SKP_STW "OP_PUBU_SKP_STW";
BA_ "LongName" SG_ 470 OP_PUBU_SKP_STW "Bedienung_Taster_Skip_Lenkrad";
BA_ "SysSignalName" SG_ 470 OP_PUBU_SKP_STW "OP_PUBU_SKP_STW";
BA_ "CompuMethodName" SG_ 470 OP_PUBU_PTT_STW "OP_PUBU_PTT_STW";
BA_ "ISignalName" SG_ 470 OP_PUBU_PTT_STW "OP_PUBU_PTT_STW";
BA_ "LongName" SG_ 470 OP_PUBU_PTT_STW "Bedienung_Taster_PTT_Lenkrad";
BA_ "SysSignalName" SG_ 470 OP_PUBU_PTT_STW "OP_PUBU_PTT_STW";
BA_ "CompuMethodName" SG_ 470 OP_PUBU_HORN "OP_PUBU_HORN";
BA_ "ISignalName" SG_ 470 OP_PUBU_HORN "OP_PUBU_HORN";
BA_ "LongName" SG_ 470 OP_PUBU_HORN "Bedienung_Taster_Horn";
BA_ "SysSignalName" SG_ 470 OP_PUBU_HORN "OP_PUBU_HORN";
BA_ "CompuMethodName" SG_ 470 OP_PUBU_SPFN "PUBU_SPFN";
BA_ "ISignalName" SG_ 470 OP_PUBU_SPFN "OP_PUBU_SPFN";
BA_ "LongName" SG_ 470 OP_PUBU_SPFN "Bedienung_Taster_Sonderfunktion";
BA_ "SysSignalName" SG_ 470 OP_PUBU_SPFN "OP_PUBU_SPFN";
BA_ "CompuMethodName" SG_ 470 OP_PUBU_SPFN_2 "PUBU_SPFN_2";
BA_ "ISignalName" SG_ 470 OP_PUBU_SPFN_2 "OP_PUBU_SPFN_2";
BA_ "LongName" SG_ 470 OP_PUBU_SPFN_2 "Bedienung_Taster_Sonderfunktion_2";
BA_ "SysSignalName" SG_ 470 OP_PUBU_SPFN_2 "OP_PUBU_SPFN_2";
BA_ "CompuMethodName" SG_ 696 OP_LIM "OP_LIM";
BA_ "ISignalName" SG_ 696 OP_LIM "OP_LIM";
BA_ "LongName" SG_ 696 OP_LIM "Bedienung_Begrenzung";
BA_ "SysSignalName" SG_ 696 OP_LIM "OP_LIM";
BA_ "CompuMethodName" SG_ 696 OP_LIM_SPEC "OP_LIM_SPEC";
BA_ "ISignalName" SG_ 696 OP_LIM_SPEC "OP_LIM_SPEC";
BA_ "LongName" SG_ 696 OP_LIM_SPEC "Bedienung_Begrenzung_Vorgabe";
BA_ "SysSignalName" SG_ 696 OP_LIM_SPEC "OP_LIM_SPEC";
BA_ "CompuMethodName" SG_ 696 OP_BC_1 "OP_BC_1";
BA_ "ISignalName" SG_ 696 OP_BC_1 "OP_BC_1";
BA_ "LongName" SG_ 696 OP_BC_1 "Bedienung_BC_1";
BA_ "SysSignalName" SG_ 696 OP_BC_1 "OP_BC_1";
BA_ "CompuMethodName" SG_ 696 OP_BC_2 "OP_BC_2";
BA_ "ISignalName" SG_ 696 OP_BC_2 "OP_BC_2";
BA_ "LongName" SG_ 696 OP_BC_2 "Bedienung_BC_2";
BA_ "SysSignalName" SG_ 696 OP_BC_2 "OP_BC_2";
BA_ "CompuMethodName" SG_ 494 OP_COLS "OP_COLS";
BA_ "ISignalName" SG_ 494 OP_COLS "OP_COLS";
BA_ "LongName" SG_ 494 OP_COLS "Bedienung_Lenkstocktaster";
BA_ "SysSignalName" SG_ 494 OP_COLS "OP_COLS";
BA_ "CompuMethodName" SG_ 494 ST_PUBU_MAB_ASST "OP_PUBU";
BA_ "ISignalName" SG_ 494 ST_PUBU_MAB_ASST "ST_PUBU_MAB_ASST";
BA_ "LongName" SG_ 494 ST_PUBU_MAB_ASST "Status_Taster_Fernlicht_Assistent";
BA_ "SysSignalName" SG_ 494 ST_PUBU_MAB_ASST "ST_PUBU_MAB_ASST";
BA_ "CompuMethodName" SG_ 540 OP_IM_NIVI "IM_NIVI";
BA_ "ISignalName" SG_ 540 OP_IM_NIVI "OP_IM_NIVI";
BA_ "LongName" SG_ 540 OP_IM_NIVI "Bedienung_Bild_Night-Vision";
BA_ "SysSignalName" SG_ 540 OP_IM_NIVI "OP_IM_NIVI";
BA_ "CompuMethodName" SG_ 540 OP_DISP_MNT_NIVI "ENUM_2_noIniVal_noDflVal_3_noQuant_noOffs_typeBitField_noRng_3";
BA_ "ISignalName" SG_ 540 OP_DISP_MNT_NIVI "OP_DISP_MNT_NIVI";
BA_ "LongName" SG_ 540 OP_DISP_MNT_NIVI "Bedienung_Anzeige_Monitor_Night-Vision";
BA_ "SysSignalName" SG_ 540 OP_DISP_MNT_NIVI "OP_DISP_MNT_NIVI";
BA_ "CompuMethodName" SG_ 540 OP_CONTR_NIVI "UI_8_noIniVal_noDflVal_255_1_0_typeDomain_hasRng";
BA_ "ISignalName" SG_ 540 OP_CONTR_NIVI "OP_CONTR_NIVI";
BA_ "LongName" SG_ 540 OP_CONTR_NIVI "Bedienung_Kontrast_Night-Vision";
BA_ "SysSignalName" SG_ 540 OP_CONTR_NIVI "OP_CONTR_NIVI";
BA_ "CompuMethodName" SG_ 540 OP_BRIG_OFFS_NIVI "BRIG_OFFS_NIVI";
BA_ "ISignalName" SG_ 540 OP_BRIG_OFFS_NIVI "OP_BRIG_OFFS_NIVI";
BA_ "LongName" SG_ 540 OP_BRIG_OFFS_NIVI "Bedienung_Helligkeit_Offset_Night-Vision";
BA_ "SysSignalName" SG_ 540 OP_BRIG_OFFS_NIVI "OP_BRIG_OFFS_NIVI";
BA_ "CompuMethodName" SG_ 540 OP_OBJ_DETE_NIVI "OBJ_DETE_NIVI";
BA_ "ISignalName" SG_ 540 OP_OBJ_DETE_NIVI "OP_OBJ_DETE_NIVI";
BA_ "LongName" SG_ 540 OP_OBJ_DETE_NIVI "operation_object_detection_night-vision";
BA_ "SysSignalName" SG_ 540 OP_OBJ_DETE_NIVI "OP_OBJ_DETE_NIVI";
BA_ "CompuMethodName" SG_ 552 ID_SPFN "ID_SPFN";
BA_ "ISignalName" SG_ 552 ID_SPFN "ID_SPFN";
BA_ "LongName" SG_ 552 ID_SPFN "ID_Sonderfunktion";
BA_ "SysSignalName" SG_ 552 ID_SPFN "ID_SPFN";
BA_ "CompuMethodName" SG_ 926 OP_HR "OP_HR";
BA_ "ISignalName" SG_ 926 OP_HR "OP_HR";
BA_ "LongName" SG_ 926 OP_HR "Bedienung_Stunde";
BA_ "SysSignalName" SG_ 926 OP_HR "OP_HR";
BA_ "CompuMethodName" SG_ 926 OP_MN "OP_MN";
BA_ "ISignalName" SG_ 926 OP_MN "OP_MN";
BA_ "LongName" SG_ 926 OP_MN "Bedienung_Minute";
BA_ "SysSignalName" SG_ 926 OP_MN "OP_MN";
BA_ "CompuMethodName" SG_ 926 OP_SEC "OP_SEC";
BA_ "ISignalName" SG_ 926 OP_SEC "OP_SEC";
BA_ "LongName" SG_ 926 OP_SEC "Bedienung_Sekunde";
BA_ "SysSignalName" SG_ 926 OP_SEC "OP_SEC";
BA_ "CompuMethodName" SG_ 926 OP_DATE_DAY "OP_DATE_DAY";
BA_ "ISignalName" SG_ 926 OP_DATE_DAY "OP_DATE_DAY";
BA_ "LongName" SG_ 926 OP_DATE_DAY "Bedienung_Datum_Tag";
BA_ "SysSignalName" SG_ 926 OP_DATE_DAY "OP_DATE_DAY";
BA_ "CompuMethodName" SG_ 926 OP_DATE_MON "OP_DATE_MON";
BA_ "ISignalName" SG_ 926 OP_DATE_MON "OP_DATE_MON";
BA_ "LongName" SG_ 926 OP_DATE_MON "Bedienung_Datum_Monat";
BA_ "SysSignalName" SG_ 926 OP_DATE_MON "OP_DATE_MON";
BA_ "CompuMethodName" SG_ 926 OP_DATE_YR "OP_DATE_YR";
BA_ "ISignalName" SG_ 926 OP_DATE_YR "OP_DATE_YR";
BA_ "LongName" SG_ 926 OP_DATE_YR "Bedienung_Datum_Jahr";
BA_ "SysSignalName" SG_ 926 OP_DATE_YR "OP_DATE_YR";
BA_ "CompuMethodName" SG_ 926 OP_DISP_CTI_DATE "OP_DISP_CTI_DATE";
BA_ "ISignalName" SG_ 926 OP_DISP_CTI_DATE "OP_DISP_CTI_DATE";
BA_ "LongName" SG_ 926 OP_DISP_CTI_DATE "Bedienung_Anzeige_Uhrzeit_Datum";
BA_ "SysSignalName" SG_ 926 OP_DISP_CTI_DATE "OP_DISP_CTI_DATE";
BA_ "CompuMethodName" SG_ 678 OP_WISW "OP_WISW";
BA_ "ISignalName" SG_ 678 OP_WISW "OP_WISW";
BA_ "LongName" SG_ 678 OP_WISW "Bedienung_Wischertaster";
BA_ "SysSignalName" SG_ 678 OP_WISW "OP_WISW";
BA_ "CompuMethodName" SG_ 678 OP_WIPO "OP_WIPO";
BA_ "ISignalName" SG_ 678 OP_WIPO "OP_WIPO";
BA_ "LongName" SG_ 678 OP_WIPO "Bedienung_Wischerpotentiometer";
BA_ "SysSignalName" SG_ 678 OP_WIPO "OP_WIPO";
BA_ "CompuMethodName" SG_ 678 ALIV_WISW "ALIV_COU_4";
BA_ "ISignalName" SG_ 678 ALIV_WISW "ALIV_WISW";
BA_ "LongName" SG_ 678 ALIV_WISW "alive_wiper-switch";
BA_ "SysSignalName" SG_ 678 ALIV_WISW "ALIV_WISW";
BA_ "CompuMethodName" SG_ 502 CCLK_IDC "CCLK_IDC";
BA_ "ISignalName" SG_ 502 CCLK_IDC "CCLK_IDC";
BA_ "LongName" SG_ 502 CCLK_IDC "Takt_Blinken";
BA_ "SysSignalName" SG_ 502 CCLK_IDC "CCLK_IDC";
BA_ "CompuMethodName" SG_ 502 ST_IDC "ST_IDC";
BA_ "ISignalName" SG_ 502 ST_IDC "ST_IDC";
BA_ "LongName" SG_ 502 ST_IDC "Status_Blinken";
BA_ "SysSignalName" SG_ 502 ST_IDC "ST_IDC";
BA_ "CompuMethodName" SG_ 502 ST_IDC_STOP "ST_IDC_STOP";
BA_ "ISignalName" SG_ 502 ST_IDC_STOP "ST_IDC_STOP";
BA_ "LongName" SG_ 502 ST_IDC_STOP "Status_Blinken_Stop";
BA_ "SysSignalName" SG_ 502 ST_IDC_STOP "ST_IDC_STOP";
BA_ "CompuMethodName" SG_ 502 ST_IDC_KI "ST_IDC_KI";
BA_ "ISignalName" SG_ 502 ST_IDC_KI "ST_IDC_KI";
BA_ "LongName" SG_ 502 ST_IDC_KI "Status_Blinken_Kombi";
BA_ "SysSignalName" SG_ 502 ST_IDC_KI "ST_IDC_KI";
BA_ "CompuMethodName" SG_ 502 ST_IDC_TYP "ST_IDC_TYP";
BA_ "ISignalName" SG_ 502 ST_IDC_TYP "ST_IDC_TYP";
BA_ "LongName" SG_ 502 ST_IDC_TYP "Status_Blinken_Typ";
BA_ "SysSignalName" SG_ 502 ST_IDC_TYP "ST_IDC_TYP";
BA_ "CompuMethodName" SG_ 641 MEAQ_U_14V "MEAQ_U_14V";
BA_ "ISignalName" SG_ 641 MEAQ_U_14V "MEAQ_U_14V";
BA_ "LongName" SG_ 641 MEAQ_U_14V "Messgröße_Spannung_14V";
BA_ "SysSignalName" SG_ 641 MEAQ_U_14V "MEAQ_U_14V";
BA_ "CompuMethodName" SG_ 677 VL_BRIG_ENVI "VL_BRIG_ENVI";
BA_ "ISignalName" SG_ 677 VL_BRIG_ENVI "VL_BRIG_ENVI";
BA_ "LongName" SG_ 677 VL_BRIG_ENVI "Wert_Helligkeit_Umgebung";
BA_ "SysSignalName" SG_ 677 VL_BRIG_ENVI "VL_BRIG_ENVI";
BA_ "CompuMethodName" SG_ 677 VL_BRIG_PFIE "VL_BRIG_PFIE";
BA_ "ISignalName" SG_ 677 VL_BRIG_PFIE "VL_BRIG_PFIE";
BA_ "LongName" SG_ 677 VL_BRIG_PFIE "Wert_Helligkeit_Vorfeld";
BA_ "SysSignalName" SG_ 677 VL_BRIG_PFIE "VL_BRIG_PFIE";
BA_ "CompuMethodName" SG_ 946 BS_SU_KI_BC "BS_SU_KI_BC";
BA_ "ISignalName" SG_ 946 BS_SU_KI_BC "BS_SU_KI_BC";
BA_ "LongName" SG_ 946 BS_SU_KI_BC "Basis_Konfiguration_Kombi_BC";
BA_ "SysSignalName" SG_ 946 BS_SU_KI_BC "BS_SU_KI_BC";
BA_ "CompuMethodName" SG_ 946 BS_SU_KI_CONT "BS_SU_KI_CONT";
BA_ "ISignalName" SG_ 946 BS_SU_KI_CONT "BS_SU_KI_CONT";
BA_ "LongName" SG_ 946 BS_SU_KI_CONT "base_setup_instrument-pack_content";
BA_ "SysSignalName" SG_ 946 BS_SU_KI_CONT "BS_SU_KI_CONT";
BA_ "CompuMethodName" SG_ 946 BS_SU_PRESL_KI "BS_SU_PRESL_KI";
BA_ "ISignalName" SG_ 946 BS_SU_PRESL_KI "BS_SU_PRESL_KI";
BA_ "LongName" SG_ 946 BS_SU_PRESL_KI "Basis_Konfiguration_Vorwahl_Kombi";
BA_ "SysSignalName" SG_ 946 BS_SU_PRESL_KI "BS_SU_PRESL_KI";
BA_ "CompuMethodName" SG_ 1012 BS_SU_KI_CONT_2 "BS_SU_KI_CONT_2";
BA_ "ISignalName" SG_ 1012 BS_SU_KI_CONT_2 "BS_SU_KI_CONT_2";
BA_ "LongName" SG_ 1012 BS_SU_KI_CONT_2 "Basis_Konfiguration_Kombi_Inhalt_2";
BA_ "SysSignalName" SG_ 1012 BS_SU_KI_CONT_2 "BS_SU_KI_CONT_2";
BA_ "CompuMethodName" SG_ 1012 BS_SU_PRESL_KI_2 "BS_SU_PRESL_KI_2";
BA_ "ISignalName" SG_ 1012 BS_SU_PRESL_KI_2 "BS_SU_PRESL_KI_2";
BA_ "LongName" SG_ 1012 BS_SU_PRESL_KI_2 "Basis_Konfiguration_Vorwahl_Kombi_2";
BA_ "SysSignalName" SG_ 1012 BS_SU_PRESL_KI_2 "BS_SU_PRESL_KI_2";
BA_ "CompuMethodName" SG_ 1012 DISP_SU_LNK_HU "DISP_SU_LNK_HU";
BA_ "ISignalName" SG_ 1012 DISP_SU_LNK_HU "DISP_SU_LNK_HU";
BA_ "LongName" SG_ 1012 DISP_SU_LNK_HU "Anzeige_Konfiguration_Verknuepfung_Head-Unit";
BA_ "SysSignalName" SG_ 1012 DISP_SU_LNK_HU "DISP_SU_LNK_HU";
BA_ "CompuMethodName" SG_ 1012 BS_SU_NAVI_DISP_TYP "BS_SU_NAVI_DISP_TYP";
BA_ "ISignalName" SG_ 1012 BS_SU_NAVI_DISP_TYP "BS_SU_NAVI_DISP_TYP";
BA_ "LongName" SG_ 1012 BS_SU_NAVI_DISP_TYP "Basis_Konfiguration_Navigation_Anzeige_Typ";
BA_ "SysSignalName" SG_ 1012 BS_SU_NAVI_DISP_TYP "BS_SU_NAVI_DISP_TYP";
BA_ "CompuMethodName" SG_ 1012 BS_SU_ENTAI_ECU_DISP "BS_SU_ENTAI_ECU_DISP";
BA_ "ISignalName" SG_ 1012 BS_SU_ENTAI_ECU_DISP "BS_SU_ENTAI_ECU_DISP";
BA_ "LongName" SG_ 1012 BS_SU_ENTAI_ECU_DISP "Basis_Konfiguration_Entertainment_STG_Anzeige";
BA_ "SysSignalName" SG_ 1012 BS_SU_ENTAI_ECU_DISP "BS_SU_ENTAI_ECU_DISP";
BA_ "CompuMethodName" SG_ 1012 BaseSetupDZMorPowermeterDisplay "BaseSetupDZMorPowermeterDisplay";
BA_ "ISignalName" SG_ 1012 BaseSetupDZMorPowermeterDisplay "BaseSetupDZMorPowermeterDisplay";
BA_ "LongName" SG_ 1012 BaseSetupDZMorPowermeterDisplay "BaseSetupDZMorPowermeterDisplay";
BA_ "SysSignalName" SG_ 1012 BaseSetupDZMorPowermeterDisplay "BaseSetupDZMorPowermeterDisplay";
BA_ "CompuMethodName" SG_ 1195 CurrentConsumptionCombustion "CurrentConsumption";
BA_ "ISignalName" SG_ 1195 CurrentConsumptionCombustion "CurrentConsumptionCombustion";
BA_ "LongName" SG_ 1195 CurrentConsumptionCombustion "CurrentConsumptionCombustion";
BA_ "SysSignalName" SG_ 1195 CurrentConsumptionCombustion "CurrentConsumptionCombustion";
BA_ "CompuMethodName" SG_ 1195 CurrentConsumptionElectric "CurrentConsumption";
BA_ "ISignalName" SG_ 1195 CurrentConsumptionElectric "CurrentConsumptionElectric";
BA_ "LongName" SG_ 1195 CurrentConsumptionElectric "CurrentConsumptionElectric";
BA_ "SysSignalName" SG_ 1195 CurrentConsumptionElectric "CurrentConsumptionElectric";
BA_ "CompuMethodName" SG_ 1195 UnitCurrentConsumptionCombustion "UnitCurrentConsumptionCombustion";
BA_ "ISignalName" SG_ 1195 UnitCurrentConsumptionCombustion "UnitCurrentConsumptionCombustion";
BA_ "LongName" SG_ 1195 UnitCurrentConsumptionCombustion "UnitCurrentConsumptionCombustion";
BA_ "SysSignalName" SG_ 1195 UnitCurrentConsumptionCombustion "UnitCurrentConsumptionCombustion";
BA_ "CompuMethodName" SG_ 1195 UnitCurrentConsumptionElectric "UnitCurrentConsumptionElectric";
BA_ "ISignalName" SG_ 1195 UnitCurrentConsumptionElectric "UnitCurrentConsumptionElectric";
BA_ "LongName" SG_ 1195 UnitCurrentConsumptionElectric "UnitCurrentConsumptionElectric";
BA_ "SysSignalName" SG_ 1195 UnitCurrentConsumptionElectric "UnitCurrentConsumptionElectric";
BA_ "CompuMethodName" SG_ 812 ST_DIST_DSTN_NAVI "ST_DIST_DSTN_NAVI";
BA_ "ISignalName" SG_ 812 ST_DIST_DSTN_NAVI "ST_DIST_DSTN_NAVI";
BA_ "LongName" SG_ 812 ST_DIST_DSTN_NAVI "Status_Distanz_Ziel_Navigation";
BA_ "SysSignalName" SG_ 812 ST_DIST_DSTN_NAVI "ST_DIST_DSTN_NAVI";
BA_ "CompuMethodName" SG_ 812 ST_DIST_DSTN_NAVI_UN "ST_DIST_DSTN_NAVI_UN";
BA_ "ISignalName" SG_ 812 ST_DIST_DSTN_NAVI_UN "ST_DIST_DSTN_NAVI_UN";
BA_ "LongName" SG_ 812 ST_DIST_DSTN_NAVI_UN "Status_Distanz_Ziel_Navigation_Einheit";
BA_ "SysSignalName" SG_ 812 ST_DIST_DSTN_NAVI_UN "ST_DIST_DSTN_NAVI_UN";
BA_ "CompuMethodName" SG_ 812 ST_ARRI_T_HR "ST_ARRI_T_HR";
BA_ "ISignalName" SG_ 812 ST_ARRI_T_HR "ST_ARRI_T_HR";
BA_ "LongName" SG_ 812 ST_ARRI_T_HR "Status_Ankunft_Zeit_Stunde";
BA_ "SysSignalName" SG_ 812 ST_ARRI_T_HR "ST_ARRI_T_HR";
BA_ "CompuMethodName" SG_ 812 ST_ARRI_T_MN "ST_ARRI_T_MN";
BA_ "ISignalName" SG_ 812 ST_ARRI_T_MN "ST_ARRI_T_MN";
BA_ "LongName" SG_ 812 ST_ARRI_T_MN "Status_Ankunft_Zeit_Minute";
BA_ "SysSignalName" SG_ 812 ST_ARRI_T_MN "ST_ARRI_T_MN";
BA_ "CompuMethodName" SG_ 812 ST_T_AM_PM "ST_T_AM_PM";
BA_ "ISignalName" SG_ 812 ST_T_AM_PM "ST_T_AM_PM";
BA_ "LongName" SG_ 812 ST_T_AM_PM "Status_Zeit_AM_PM";
BA_ "SysSignalName" SG_ 812 ST_T_AM_PM "ST_T_AM_PM";
BA_ "CompuMethodName" SG_ 812 ST_DAY_FLAG "ST_DAY_FLAG";
BA_ "ISignalName" SG_ 812 ST_DAY_FLAG "ST_DAY_FLAG";
BA_ "LongName" SG_ 812 ST_DAY_FLAG "Status_Tag_Flag";
BA_ "SysSignalName" SG_ 812 ST_DAY_FLAG "ST_DAY_FLAG";
BA_ "CompuMethodName" SG_ 1184 DT_APPL_CAS_ST_1 "DT_APPL_CAS";
BA_ "ISignalName" SG_ 1184 DT_APPL_CAS_ST_1 "DT_APPL_CAS_ST_1";
BA_ "LongName" SG_ 1184 DT_APPL_CAS_ST_1 "Daten_Applikation_CAS_Status_1";
BA_ "SysSignalName" SG_ 1184 DT_APPL_CAS_ST_1 "DT_APPL_CAS_ST_1";
BA_ "CompuMethodName" SG_ 1186 DT_APPL_CAS_ST_2 "DT_APPL_CAS";
BA_ "ISignalName" SG_ 1186 DT_APPL_CAS_ST_2 "DT_APPL_CAS_ST_2";
BA_ "LongName" SG_ 1186 DT_APPL_CAS_ST_2 "Daten_Applikation_CAS_Status_2";
BA_ "SysSignalName" SG_ 1186 DT_APPL_CAS_ST_2 "DT_APPL_CAS_ST_2";
BA_ "CompuMethodName" SG_ 110 CCLK_COU_SYNCN_CAN_TYP "CCLK_COU_SYNCN_CAN_TYP";
BA_ "ISignalName" SG_ 110 CCLK_COU_SYNCN_CAN_TYP "CCLK_COU_SYNCN_CAN_TYP";
BA_ "LongName" SG_ 110 CCLK_COU_SYNCN_CAN_TYP "Takt_Zähler_Synchronisation_CAN_Typ";
BA_ "SysSignalName" SG_ 110 CCLK_COU_SYNCN_CAN_TYP "CCLK_COU_SYNCN_CAN_TYP";
BA_ "CompuMethodName" SG_ 110 CCLK_COU_SYNCN_CAN_IDENT "CCLK_COU_SYNCN_IDENT";
BA_ "ISignalName" SG_ 110 CCLK_COU_SYNCN_CAN_IDENT "CCLK_COU_SYNCN_CAN_IDENT";
BA_ "LongName" SG_ 110 CCLK_COU_SYNCN_CAN_IDENT "Takt_Zähler_Synchronisation_CAN_Identifikation";
BA_ "SysSignalName" SG_ 110 CCLK_COU_SYNCN_CAN_IDENT "CCLK_COU_SYNCN_CAN_IDENT";
BA_ "CompuMethodName" SG_ 110 CCLK_COU_SYNCN_CAN_SEC "COU_SYNC_SEC_32_BIT";
BA_ "ISignalName" SG_ 110 CCLK_COU_SYNCN_CAN_SEC "CCLK_COU_SYNCN_CAN_SEC";
BA_ "LongName" SG_ 110 CCLK_COU_SYNCN_CAN_SEC "Takt_Zähler_Synchronisation_CAN_Sekunde";
BA_ "SysSignalName" SG_ 110 CCLK_COU_SYNCN_CAN_SEC "CCLK_COU_SYNCN_CAN_SEC";
BA_ "CompuMethodName" SG_ 111 CCLK_COU_SYNCN_TYP "CCLK_COU_SYNCN_TYP_FLLUP";
BA_ "ISignalName" SG_ 111 CCLK_COU_SYNCN_TYP "CCLK_COU_SYNCN_TYP";
BA_ "LongName" SG_ 111 CCLK_COU_SYNCN_TYP "Takt_Zähler_Synchronisation_Typ";
BA_ "SysSignalName" SG_ 111 CCLK_COU_SYNCN_TYP "CCLK_COU_SYNCN_TYP";
BA_ "CompuMethodName" SG_ 111 CCLK_COU_SYNCN_IDENT "CCLK_COU_SYNCN_IDENT";
BA_ "ISignalName" SG_ 111 CCLK_COU_SYNCN_IDENT "CCLK_COU_SYNCN_IDENT";
BA_ "LongName" SG_ 111 CCLK_COU_SYNCN_IDENT "Takt_Zähler_Synchronisation_Identifikation";
BA_ "SysSignalName" SG_ 111 CCLK_COU_SYNCN_IDENT "CCLK_COU_SYNCN_IDENT";
BA_ "CompuMethodName" SG_ 111 CCLK_COU_SYNCN_VL "CCLK_COU_SYNCN_VL";
BA_ "ISignalName" SG_ 111 CCLK_COU_SYNCN_VL "CCLK_COU_SYNCN_VL";
BA_ "LongName" SG_ 111 CCLK_COU_SYNCN_VL "Takt_Zähler_Synchronisation_Wert";
BA_ "SysSignalName" SG_ 111 CCLK_COU_SYNCN_VL "CCLK_COU_SYNCN_VL";
BA_ "CompuMethodName" SG_ 111 CCLK_COU_SYNCN_OVFL "CCLK_COU_SYNCN_OVFL";
BA_ "ISignalName" SG_ 111 CCLK_COU_SYNCN_OVFL "CCLK_COU_SYNCN_OVFL";
BA_ "LongName" SG_ 111 CCLK_COU_SYNCN_OVFL "Takt_Zähler_Synchronisation_Überlauf";
BA_ "SysSignalName" SG_ 111 CCLK_COU_SYNCN_OVFL "CCLK_COU_SYNCN_OVFL";
BA_ "CompuMethodName" SG_ 2161115410 CEMErrorEventDTC_DA12h "CEMErrorEventDTC";
BA_ "ISignalName" SG_ 2161115410 CEMErrorEventDTC_DA12h "CEMErrorEventDTC_DA12h";
BA_ "LongName" SG_ 2161115410 CEMErrorEventDTC_DA12h "CEMErrorEventDTC_DA12h";
BA_ "SysSignalName" SG_ 2161115410 CEMErrorEventDTC_DA12h "CEMErrorEventDTC_DA12h";
BA_ "CompuMethodName" SG_ 2161115410 CEMErrorEventTimeStampSec_DA12h "CEMErrorEventTimeStampSec";
BA_ "ISignalName" SG_ 2161115410 CEMErrorEventTimeStampSec_DA12h "CEMErrorEventTimeStampSec_DA12h";
BA_ "LongName" SG_ 2161115410 CEMErrorEventTimeStampSec_DA12h "CEMErrorEventTimeStampSec_DA12h";
BA_ "SysSignalName" SG_ 2161115410 CEMErrorEventTimeStampSec_DA12h "CEMErrorEventTimeStampSec_DA12h";
BA_ "CompuMethodName" SG_ 2161115410 CEMErrorEventTimeStampMSec_DA12h "CEMErrorEventTimeStampMSec";
BA_ "ISignalName" SG_ 2161115410 CEMErrorEventTimeStampMSec_DA12h "CEMErrorEventTimeStampMSec_DA12h";
BA_ "LongName" SG_ 2161115410 CEMErrorEventTimeStampMSec_DA12h "CEMErrorEventTimeStampMSec_DA12h";
BA_ "SysSignalName" SG_ 2161115410 CEMErrorEventTimeStampMSec_DA12h "CEMErrorEventTimeStampMSec_DA12h";
BA_ "CompuMethodName" SG_ 2161115410 CEMErrorEventSyncMethod_DA12h "CEMErrorEventSyncMethod";
BA_ "ISignalName" SG_ 2161115410 CEMErrorEventSyncMethod_DA12h "CEMErrorEventSyncMethod_DA12h";
BA_ "LongName" SG_ 2161115410 CEMErrorEventSyncMethod_DA12h "CEMErrorEventSyncMethod_DA12h";
BA_ "SysSignalName" SG_ 2161115410 CEMErrorEventSyncMethod_DA12h "CEMErrorEventSyncMethod_DA12h";
BA_ "CompuMethodName" SG_ 2161115410 CEMErrorEventECUAddress_DA12h "CEMErrorEventECUAddress";
BA_ "ISignalName" SG_ 2161115410 CEMErrorEventECUAddress_DA12h "CEMErrorEventECUAddress_DA12h";
BA_ "LongName" SG_ 2161115410 CEMErrorEventECUAddress_DA12h "CEMErrorEventECUAddress_DA12h";
BA_ "SysSignalName" SG_ 2161115410 CEMErrorEventECUAddress_DA12h "CEMErrorEventECUAddress_DA12h";
BA_ "CompuMethodName" SG_ 2161115667 CEMErrorEventDTC_DA13h "CEMErrorEventDTC";
BA_ "ISignalName" SG_ 2161115667 CEMErrorEventDTC_DA13h "CEMErrorEventDTC_DA13h";
BA_ "LongName" SG_ 2161115667 CEMErrorEventDTC_DA13h "CEMErrorEventDTC_DA13h";
BA_ "SysSignalName" SG_ 2161115667 CEMErrorEventDTC_DA13h "CEMErrorEventDTC_DA13h";
BA_ "CompuMethodName" SG_ 2161115667 CEMErrorEventTimeStampSec_DA13h "CEMErrorEventTimeStampSec";
BA_ "ISignalName" SG_ 2161115667 CEMErrorEventTimeStampSec_DA13h "CEMErrorEventTimeStampSec_DA13h";
BA_ "LongName" SG_ 2161115667 CEMErrorEventTimeStampSec_DA13h "CEMErrorEventTimeStampSec_DA13h";
BA_ "SysSignalName" SG_ 2161115667 CEMErrorEventTimeStampSec_DA13h "CEMErrorEventTimeStampSec_DA13h";
BA_ "CompuMethodName" SG_ 2161115667 CEMErrorEventTimeStampMSec_DA13h "CEMErrorEventTimeStampMSec";
BA_ "ISignalName" SG_ 2161115667 CEMErrorEventTimeStampMSec_DA13h "CEMErrorEventTimeStampMSec_DA13h";
BA_ "LongName" SG_ 2161115667 CEMErrorEventTimeStampMSec_DA13h "CEMErrorEventTimeStampMSec_DA13h";
BA_ "SysSignalName" SG_ 2161115667 CEMErrorEventTimeStampMSec_DA13h "CEMErrorEventTimeStampMSec_DA13h";
BA_ "CompuMethodName" SG_ 2161115667 CEMErrorEventSyncMethod_DA13h "CEMErrorEventSyncMethod";
BA_ "ISignalName" SG_ 2161115667 CEMErrorEventSyncMethod_DA13h "CEMErrorEventSyncMethod_DA13h";
BA_ "LongName" SG_ 2161115667 CEMErrorEventSyncMethod_DA13h "CEMErrorEventSyncMethod_DA13h";
BA_ "SysSignalName" SG_ 2161115667 CEMErrorEventSyncMethod_DA13h "CEMErrorEventSyncMethod_DA13h";
BA_ "CompuMethodName" SG_ 2161115667 CEMErrorEventECUAddress_DA13h "CEMErrorEventECUAddress";
BA_ "ISignalName" SG_ 2161115667 CEMErrorEventECUAddress_DA13h "CEMErrorEventECUAddress_DA13h";
BA_ "LongName" SG_ 2161115667 CEMErrorEventECUAddress_DA13h "CEMErrorEventECUAddress_DA13h";
BA_ "SysSignalName" SG_ 2161115667 CEMErrorEventECUAddress_DA13h "CEMErrorEventECUAddress_DA13h";
BA_ "CompuMethodName" SG_ 2161116184 CEMErrorEventDTC_DA18h "CEMErrorEventDTC";
BA_ "ISignalName" SG_ 2161116184 CEMErrorEventDTC_DA18h "CEMErrorEventDTC_DA18h";
BA_ "LongName" SG_ 2161116184 CEMErrorEventDTC_DA18h "CEMErrorEventDTC_DA18h";
BA_ "SysSignalName" SG_ 2161116184 CEMErrorEventDTC_DA18h "CEMErrorEventDTC_DA18h";
BA_ "CompuMethodName" SG_ 2161116184 CEMErrorEventTimeStampSec_DA18h "CEMErrorEventTimeStampSec";
BA_ "ISignalName" SG_ 2161116184 CEMErrorEventTimeStampSec_DA18h "CEMErrorEventTimeStampSec_DA18h";
BA_ "LongName" SG_ 2161116184 CEMErrorEventTimeStampSec_DA18h "CEMErrorEventTimeStampSec_DA18h";
BA_ "SysSignalName" SG_ 2161116184 CEMErrorEventTimeStampSec_DA18h "CEMErrorEventTimeStampSec_DA18h";
BA_ "CompuMethodName" SG_ 2161116184 CEMErrorEventTimeStampMSec_DA18h "CEMErrorEventTimeStampMSec";
BA_ "ISignalName" SG_ 2161116184 CEMErrorEventTimeStampMSec_DA18h "CEMErrorEventTimeStampMSec_DA18h";
BA_ "LongName" SG_ 2161116184 CEMErrorEventTimeStampMSec_DA18h "CEMErrorEventTimeStampMSec_DA18h";
BA_ "SysSignalName" SG_ 2161116184 CEMErrorEventTimeStampMSec_DA18h "CEMErrorEventTimeStampMSec_DA18h";
BA_ "CompuMethodName" SG_ 2161116184 CEMErrorEventSyncMethod_DA18h "CEMErrorEventSyncMethod";
BA_ "ISignalName" SG_ 2161116184 CEMErrorEventSyncMethod_DA18h "CEMErrorEventSyncMethod_DA18h";
BA_ "LongName" SG_ 2161116184 CEMErrorEventSyncMethod_DA18h "CEMErrorEventSyncMethod_DA18h";
BA_ "SysSignalName" SG_ 2161116184 CEMErrorEventSyncMethod_DA18h "CEMErrorEventSyncMethod_DA18h";
BA_ "CompuMethodName" SG_ 2161116184 CEMErrorEventECUAddress_DA18h "CEMErrorEventECUAddress";
BA_ "ISignalName" SG_ 2161116184 CEMErrorEventECUAddress_DA18h "CEMErrorEventECUAddress_DA18h";
BA_ "LongName" SG_ 2161116184 CEMErrorEventECUAddress_DA18h "CEMErrorEventECUAddress_DA18h";
BA_ "SysSignalName" SG_ 2161116184 CEMErrorEventECUAddress_DA18h "CEMErrorEventECUAddress_DA18h";
BA_ "CompuMethodName" SG_ 2161116445 CEMErrorEventDTC_DA1Dh "CEMErrorEventDTC";
BA_ "ISignalName" SG_ 2161116445 CEMErrorEventDTC_DA1Dh "CEMErrorEventDTC_DA1Dh";
BA_ "LongName" SG_ 2161116445 CEMErrorEventDTC_DA1Dh "CEMErrorEventDTC_DA1Dh";
BA_ "SysSignalName" SG_ 2161116445 CEMErrorEventDTC_DA1Dh "CEMErrorEventDTC_DA1Dh";
BA_ "CompuMethodName" SG_ 2161116445 CEMErrorEventTimeStampSec_DA1Dh "CEMErrorEventTimeStampSec";
BA_ "ISignalName" SG_ 2161116445 CEMErrorEventTimeStampSec_DA1Dh "CEMErrorEventTimeStampSec_DA1Dh";
BA_ "LongName" SG_ 2161116445 CEMErrorEventTimeStampSec_DA1Dh "CEMErrorEventTimeStampSec_DA1Dh";
BA_ "SysSignalName" SG_ 2161116445 CEMErrorEventTimeStampSec_DA1Dh "CEMErrorEventTimeStampSec_DA1Dh";
BA_ "CompuMethodName" SG_ 2161116445 CEMErrorEventTimeStampMSec_DA1Dh "CEMErrorEventTimeStampMSec";
BA_ "ISignalName" SG_ 2161116445 CEMErrorEventTimeStampMSec_DA1Dh "CEMErrorEventTimeStampMSec_DA1Dh";
BA_ "LongName" SG_ 2161116445 CEMErrorEventTimeStampMSec_DA1Dh "CEMErrorEventTimeStampMSec_DA1Dh";
BA_ "SysSignalName" SG_ 2161116445 CEMErrorEventTimeStampMSec_DA1Dh "CEMErrorEventTimeStampMSec_DA1Dh";
BA_ "CompuMethodName" SG_ 2161116445 CEMErrorEventSyncMethod_DA1Dh "CEMErrorEventSyncMethod";
BA_ "ISignalName" SG_ 2161116445 CEMErrorEventSyncMethod_DA1Dh "CEMErrorEventSyncMethod_DA1Dh";
BA_ "LongName" SG_ 2161116445 CEMErrorEventSyncMethod_DA1Dh "CEMErrorEventSyncMethod_DA1Dh";
BA_ "SysSignalName" SG_ 2161116445 CEMErrorEventSyncMethod_DA1Dh "CEMErrorEventSyncMethod_DA1Dh";
BA_ "CompuMethodName" SG_ 2161116445 CEMErrorEventECUAddress_DA1Dh "CEMErrorEventECUAddress";
BA_ "ISignalName" SG_ 2161116445 CEMErrorEventECUAddress_DA1Dh "CEMErrorEventECUAddress_DA1Dh";
BA_ "LongName" SG_ 2161116445 CEMErrorEventECUAddress_DA1Dh "CEMErrorEventECUAddress_DA1Dh";
BA_ "SysSignalName" SG_ 2161116445 CEMErrorEventECUAddress_DA1Dh "CEMErrorEventECUAddress_DA1Dh";
BA_ "CompuMethodName" SG_ 2161117269 CEMErrorEventDTC_DA55h "CEMErrorEventDTC";
BA_ "ISignalName" SG_ 2161117269 CEMErrorEventDTC_DA55h "CEMErrorEventDTC_DA55h";
BA_ "LongName" SG_ 2161117269 CEMErrorEventDTC_DA55h "CEMErrorEventDTC_DA55h";
BA_ "SysSignalName" SG_ 2161117269 CEMErrorEventDTC_DA55h "CEMErrorEventDTC_DA55h";
BA_ "CompuMethodName" SG_ 2161117269 CEMErrorEventTimeStampSec_DA55h "CEMErrorEventTimeStampSec";
BA_ "ISignalName" SG_ 2161117269 CEMErrorEventTimeStampSec_DA55h "CEMErrorEventTimeStampSec_DA55h";
BA_ "LongName" SG_ 2161117269 CEMErrorEventTimeStampSec_DA55h "CEMErrorEventTimeStampSec_DA55h";
BA_ "SysSignalName" SG_ 2161117269 CEMErrorEventTimeStampSec_DA55h "CEMErrorEventTimeStampSec_DA55h";
BA_ "CompuMethodName" SG_ 2161117269 CEMErrorEventTimeStampMSec_DA55h "CEMErrorEventTimeStampMSec";
BA_ "ISignalName" SG_ 2161117269 CEMErrorEventTimeStampMSec_DA55h "CEMErrorEventTimeStampMSec_DA55h";
BA_ "LongName" SG_ 2161117269 CEMErrorEventTimeStampMSec_DA55h "CEMErrorEventTimeStampMSec_DA55h";
BA_ "SysSignalName" SG_ 2161117269 CEMErrorEventTimeStampMSec_DA55h "CEMErrorEventTimeStampMSec_DA55h";
BA_ "CompuMethodName" SG_ 2161117269 CEMErrorEventSyncMethod_DA55h "CEMErrorEventSyncMethod";
BA_ "ISignalName" SG_ 2161117269 CEMErrorEventSyncMethod_DA55h "CEMErrorEventSyncMethod_DA55h";
BA_ "LongName" SG_ 2161117269 CEMErrorEventSyncMethod_DA55h "CEMErrorEventSyncMethod_DA55h";
BA_ "SysSignalName" SG_ 2161117269 CEMErrorEventSyncMethod_DA55h "CEMErrorEventSyncMethod_DA55h";
BA_ "CompuMethodName" SG_ 2161117269 CEMErrorEventECUAddress_DA55h "CEMErrorEventECUAddress";
BA_ "ISignalName" SG_ 2161117269 CEMErrorEventECUAddress_DA55h "CEMErrorEventECUAddress_DA55h";
BA_ "LongName" SG_ 2161117269 CEMErrorEventECUAddress_DA55h "CEMErrorEventECUAddress_DA55h";
BA_ "SysSignalName" SG_ 2161117269 CEMErrorEventECUAddress_DA55h "CEMErrorEventECUAddress_DA55h";
BA_ "CompuMethodName" SG_ 1001 WISH_UTS_ENC "WISH_UTS_ENC";
BA_ "ISignalName" SG_ 1001 WISH_UTS_ENC "WISH_UTS_ENC";
BA_ "LongName" SG_ 1001 WISH_UTS_ENC "Wunsch_Nutzung_Energieinhalt";
BA_ "SysSignalName" SG_ 1001 WISH_UTS_ENC "WISH_UTS_ENC";
BA_ "CompuMethodName" SG_ 1001 RQ_CHGRDI "RQ_CHGRDI";
BA_ "ISignalName" SG_ 1001 RQ_CHGRDI "RQ_CHGRDI";
BA_ "LongName" SG_ 1001 RQ_CHGRDI "Anforderung_Ladebereitschaft";
BA_ "SysSignalName" SG_ 1001 RQ_CHGRDI "RQ_CHGRDI";
BA_ "CompuMethodName" SG_ 1001 ST_CHGNG "ST_CHGNG_eDME";
BA_ "ISignalName" SG_ 1001 ST_CHGNG "ST_CHGNG";
BA_ "LongName" SG_ 1001 ST_CHGNG "Status_Laden";
BA_ "SysSignalName" SG_ 1001 ST_CHGNG "ST_CHGNG";
BA_ "CompuMethodName" SG_ 1001 ST_CHGRDI "ST_CHGRDI";
BA_ "ISignalName" SG_ 1001 ST_CHGRDI "ST_CHGRDI";
BA_ "LongName" SG_ 1001 ST_CHGRDI "Status_Ladebereitschaft";
BA_ "SysSignalName" SG_ 1001 ST_CHGRDI "ST_CHGRDI";
BA_ "CompuMethodName" SG_ 1001 FRC_PWR_CHGNG "FRC_PWR_CHGNG";
BA_ "ISignalName" SG_ 1001 FRC_PWR_CHGNG "FRC_PWR_CHGNG";
BA_ "LongName" SG_ 1001 FRC_PWR_CHGNG "Prognose_Leistung_Laden";
BA_ "SysSignalName" SG_ 1001 FRC_PWR_CHGNG "FRC_PWR_CHGNG";
BA_ "CompuMethodName" SG_ 762 DISP_RSTI_EOCHG "DISP_RSTI_EOCHG";
BA_ "ISignalName" SG_ 762 DISP_RSTI_EOCHG "DISP_RSTI_EOCHG";
BA_ "LongName" SG_ 762 DISP_RSTI_EOCHG "Anzeige_Restzeit_Ladeende";
BA_ "SysSignalName" SG_ 762 DISP_RSTI_EOCHG "DISP_RSTI_EOCHG";
BA_ "CompuMethodName" SG_ 762 DISP_CHGNG_T_HR "DISP_CHGNG_T_HR";
BA_ "ISignalName" SG_ 762 DISP_CHGNG_T_HR "DISP_CHGNG_T_HR";
BA_ "LongName" SG_ 762 DISP_CHGNG_T_HR "Anzeige_Laden_Zeit_Stunde";
BA_ "SysSignalName" SG_ 762 DISP_CHGNG_T_HR "DISP_CHGNG_T_HR";
BA_ "CompuMethodName" SG_ 762 DISP_CHGNG_T_MN "DISP_CHGNG_T_MN";
BA_ "ISignalName" SG_ 762 DISP_CHGNG_T_MN "DISP_CHGNG_T_MN";
BA_ "LongName" SG_ 762 DISP_CHGNG_T_MN "Anzeige_Laden_Zeit_Minute";
BA_ "SysSignalName" SG_ 762 DISP_CHGNG_T_MN "DISP_CHGNG_T_MN";
BA_ "CompuMethodName" SG_ 762 CHGNG_STA_T_HR "CHGNG_STA_T_HR";
BA_ "ISignalName" SG_ 762 CHGNG_STA_T_HR "CHGNG_STA_T_HR";
BA_ "LongName" SG_ 762 CHGNG_STA_T_HR "Laden_Start_Zeit_Stunde";
BA_ "SysSignalName" SG_ 762 CHGNG_STA_T_HR "CHGNG_STA_T_HR";
BA_ "CompuMethodName" SG_ 762 CHGNG_STA_T_MN "CHGNG_STA_T_MN";
BA_ "ISignalName" SG_ 762 CHGNG_STA_T_MN "CHGNG_STA_T_MN";
BA_ "LongName" SG_ 762 CHGNG_STA_T_MN "Laden_Start_Zeit_Minute";
BA_ "SysSignalName" SG_ 762 CHGNG_STA_T_MN "CHGNG_STA_T_MN";
BA_ "CompuMethodName" SG_ 762 TAR_OPMO_DISP_CHGNG_MOD "TAR_OPRMOD_DISP_CHGNG_MOD";
BA_ "ISignalName" SG_ 762 TAR_OPMO_DISP_CHGNG_MOD "TAR_OPMO_DISP_CHGNG_MOD";
BA_ "LongName" SG_ 762 TAR_OPMO_DISP_CHGNG_MOD "Soll_Betriebsart_Anzeige_Laden_Modus";
BA_ "SysSignalName" SG_ 762 TAR_OPMO_DISP_CHGNG_MOD "TAR_OPMO_DISP_CHGNG_MOD";
BA_ "CompuMethodName" SG_ 971 CHNO_MILE_WHL "CHNO_MILE_WHL";
BA_ "ISignalName" SG_ 971 CHNO_MILE_WHL "CHNO_MILE_WHL";
BA_ "LongName" SG_ 971 CHNO_MILE_WHL "Kennzahl_Wegstrecke_Rad";
BA_ "SysSignalName" SG_ 971 CHNO_MILE_WHL "CHNO_MILE_WHL";
BA_ "CompuMethodName" SG_ 971 CHNO_V_VEH_COG "CHNO_V_VEH_COG";
BA_ "ISignalName" SG_ 971 CHNO_V_VEH_COG "CHNO_V_VEH_COG";
BA_ "LongName" SG_ 971 CHNO_V_VEH_COG "Kennzahl_Geschwindigkeit_Fahrzeug_Schwerpunkt";
BA_ "SysSignalName" SG_ 971 CHNO_V_VEH_COG "CHNO_V_VEH_COG";
BA_ "CompuMethodName" SG_ 876 CRC_CODO_LIM_V "CRC8";
BA_ "ISignalName" SG_ 876 CRC_CODO_LIM_V "CRC_CODO_LIM_V";
BA_ "LongName" SG_ 876 CRC_CODO_LIM_V "CRC_Coach-Tür_Begrenzung_Geschwindigkeit";
BA_ "SysSignalName" SG_ 876 CRC_CODO_LIM_V "CRC_CODO_LIM_V";
BA_ "CompuMethodName" SG_ 876 ALIV_CODO_LIM_V "Aliv_4";
BA_ "ISignalName" SG_ 876 ALIV_CODO_LIM_V "ALIV_CODO_LIM_V";
BA_ "LongName" SG_ 876 ALIV_CODO_LIM_V "Alive_Coach-Tür_Begrenzung_Geschwindigkeit";
BA_ "SysSignalName" SG_ 876 ALIV_CODO_LIM_V "ALIV_CODO_LIM_V";
BA_ "CompuMethodName" SG_ 876 ST_ECU_CODO_LIM_V "ST_ECU_CODO_LIM_V";
BA_ "ISignalName" SG_ 876 ST_ECU_CODO_LIM_V "ST_ECU_CODO_LIM_V";
BA_ "LongName" SG_ 876 ST_ECU_CODO_LIM_V "Status_STG_Coach-Tür_Begrenzung_Geschwindigkeit";
BA_ "SysSignalName" SG_ 876 ST_ECU_CODO_LIM_V "ST_ECU_CODO_LIM_V";
BA_ "CompuMethodName" SG_ 876 QU_CODO_LIM_V "QU_CODO_LIM_V";
BA_ "ISignalName" SG_ 876 QU_CODO_LIM_V "QU_CODO_LIM_V";
BA_ "LongName" SG_ 876 QU_CODO_LIM_V "Qualifier_Coach-Tür_Begrenzung_Geschwindigkeit";
BA_ "SysSignalName" SG_ 876 QU_CODO_LIM_V "QU_CODO_LIM_V";
BA_ "ISignalName" SG_ 876 CODO_LIM_V_dummy_20_23 "CODO_LIM_V_dummy_20_23";
BA_ "LongName" SG_ 876 CODO_LIM_V_dummy_20_23 "CODO_LIM_V_dummy_20_23";
BA_ "SysSignalName" SG_ 876 CODO_LIM_V_dummy_20_23 "CODO_LIM_V_dummy_20_23";
BA_ "CompuMethodName" SG_ 851 ST_CODO_LOKG_DR "ST_CODO_FSE";
BA_ "ISignalName" SG_ 851 ST_CODO_LOKG_DR "ST_CODO_LOKG_DR";
BA_ "LongName" SG_ 851 ST_CODO_LOKG_DR "Status_Coach-Tür_Verriegelung_FA";
BA_ "SysSignalName" SG_ 851 ST_CODO_LOKG_DR "ST_CODO_LOKG_DR";
BA_ "CompuMethodName" SG_ 851 ST_CODO_LOKG_PS "ST_CODO_FSE";
BA_ "ISignalName" SG_ 851 ST_CODO_LOKG_PS "ST_CODO_LOKG_PS";
BA_ "LongName" SG_ 851 ST_CODO_LOKG_PS "Status_Coach-Tür_Verriegelung_BF";
BA_ "SysSignalName" SG_ 851 ST_CODO_LOKG_PS "ST_CODO_LOKG_PS";
BA_ "CompuMethodName" SG_ 851 RQ_LOKG_CODO "RQ_LOKG_CODO";
BA_ "ISignalName" SG_ 851 RQ_LOKG_CODO "RQ_LOKG_CODO";
BA_ "LongName" SG_ 851 RQ_LOKG_CODO "Anforderung_Verriegelung_Coach-Tür";
BA_ "SysSignalName" SG_ 851 RQ_LOKG_CODO "RQ_LOKG_CODO";
BA_ "CompuMethodName" SG_ 851 ST_DSW_CODO_LOKG_DR "ST_DSW_CODO_FSE_DR";
BA_ "ISignalName" SG_ 851 ST_DSW_CODO_LOKG_DR "ST_DSW_CODO_LOKG_DR";
BA_ "LongName" SG_ 851 ST_DSW_CODO_LOKG_DR "Status_Türkontakt_Coach-Tür_Verriegelung_FA";
BA_ "SysSignalName" SG_ 851 ST_DSW_CODO_LOKG_DR "ST_DSW_CODO_LOKG_DR";
BA_ "CompuMethodName" SG_ 851 ST_DSW_CODO_LOKG_PS "ST_DSW_CODO_FSE_PS";
BA_ "ISignalName" SG_ 851 ST_DSW_CODO_LOKG_PS "ST_DSW_CODO_LOKG_PS";
BA_ "LongName" SG_ 851 ST_DSW_CODO_LOKG_PS "Status_Türkontakt_Coach-Tür_Verriegelung_BF";
BA_ "SysSignalName" SG_ 851 ST_DSW_CODO_LOKG_PS "ST_DSW_CODO_LOKG_PS";
BA_ "CompuMethodName" SG_ 1071 SU_MDRV_2_DSC "MDRV_2_DSC";
BA_ "ISignalName" SG_ 1071 SU_MDRV_2_DSC "SU_MDRV_2_DSC";
BA_ "LongName" SG_ 1071 SU_MDRV_2_DSC "Konfiguration_M-Drive_2_DSC";
BA_ "SysSignalName" SG_ 1071 SU_MDRV_2_DSC "SU_MDRV_2_DSC";
BA_ "CompuMethodName" SG_ 1071 SU_MDRV_2_IDX "MDRV_2_IDX";
BA_ "ISignalName" SG_ 1071 SU_MDRV_2_IDX "SU_MDRV_2_IDX";
BA_ "LongName" SG_ 1071 SU_MDRV_2_IDX "Konfiguration_M-Drive_2_Index";
BA_ "SysSignalName" SG_ 1071 SU_MDRV_2_IDX "SU_MDRV_2_IDX";
BA_ "CompuMethodName" SG_ 1071 SU_MDRV_2_STG_GRB "MDRV_STG_GRB";
BA_ "ISignalName" SG_ 1071 SU_MDRV_2_STG_GRB "SU_MDRV_2_STG_GRB";
BA_ "LongName" SG_ 1071 SU_MDRV_2_STG_GRB "Konfiguration_M-Drive_2_Stufe_Getriebe";
BA_ "SysSignalName" SG_ 1071 SU_MDRV_2_STG_GRB "SU_MDRV_2_STG_GRB";
BA_ "CompuMethodName" SG_ 1071 SU_MDRV_2_ENG "MDRV_2_ENG";
BA_ "ISignalName" SG_ 1071 SU_MDRV_2_ENG "SU_MDRV_2_ENG";
BA_ "LongName" SG_ 1071 SU_MDRV_2_ENG "Konfiguration_M-Drive_2_Motor";
BA_ "SysSignalName" SG_ 1071 SU_MDRV_2_ENG "SU_MDRV_2_ENG";
BA_ "CompuMethodName" SG_ 1071 SU_MDRV_2_EDC "MDRV_2_MOD";
BA_ "ISignalName" SG_ 1071 SU_MDRV_2_EDC "SU_MDRV_2_EDC";
BA_ "LongName" SG_ 1071 SU_MDRV_2_EDC "Konfiguration_M-Drive_2_Eletronische-Dämpfer-Steuerung";
BA_ "SysSignalName" SG_ 1071 SU_MDRV_2_EDC "SU_MDRV_2_EDC";
BA_ "CompuMethodName" SG_ 1071 SU_MDRV_2_EPAS "MDRV_2_MOD";
BA_ "ISignalName" SG_ 1071 SU_MDRV_2_EPAS "SU_MDRV_2_EPAS";
BA_ "LongName" SG_ 1071 SU_MDRV_2_EPAS "Konfiguration_M-Drive_2_Servotronic";
BA_ "SysSignalName" SG_ 1071 SU_MDRV_2_EPAS "SU_MDRV_2_EPAS";
BA_ "CompuMethodName" SG_ 1071 SU_MDRV_2_DISP_HUD "MDRV_2_DISP_HUD";
BA_ "ISignalName" SG_ 1071 SU_MDRV_2_DISP_HUD "SU_MDRV_2_DISP_HUD";
BA_ "LongName" SG_ 1071 SU_MDRV_2_DISP_HUD "Konfiguration_M-Drive_2_Anzeige_HUD";
BA_ "SysSignalName" SG_ 1071 SU_MDRV_2_DISP_HUD "SU_MDRV_2_DISP_HUD";
BA_ "CompuMethodName" SG_ 1071 SU_MDRV_2_DISP_SHLI "MDRV_DISP_SHLI";
BA_ "ISignalName" SG_ 1071 SU_MDRV_2_DISP_SHLI "SU_MDRV_2_DISP_SHLI";
BA_ "LongName" SG_ 1071 SU_MDRV_2_DISP_SHLI "Konfiguration_M-Drive_2_Anzeige_Shiftlights";
BA_ "SysSignalName" SG_ 1071 SU_MDRV_2_DISP_SHLI "SU_MDRV_2_DISP_SHLI";
BA_ "CompuMethodName" SG_ 1071 SU_MDRV_2_MOD_GRB "MDRV_MOD_GRB";
BA_ "ISignalName" SG_ 1071 SU_MDRV_2_MOD_GRB "SU_MDRV_2_MOD_GRB";
BA_ "LongName" SG_ 1071 SU_MDRV_2_MOD_GRB "Konfiguration_M-Drive_2_Modus_Getriebe";
BA_ "SysSignalName" SG_ 1071 SU_MDRV_2_MOD_GRB "SU_MDRV_2_MOD_GRB";
BA_ "CompuMethodName" SG_ 1071 SU_MDRV_2_SRST "SU_MDRV_SRST";
BA_ "ISignalName" SG_ 1071 SU_MDRV_2_SRST "SU_MDRV_2_SRST";
BA_ "LongName" SG_ 1071 SU_MDRV_2_SRST "Konfiguration_M-Drive_2_Setzen/Rücksetzen";
BA_ "SysSignalName" SG_ 1071 SU_MDRV_2_SRST "SU_MDRV_2_SRST";
BA_ "CompuMethodName" SG_ 1071 SU_MDRV_2_AW "AW_SU";
BA_ "ISignalName" SG_ 1071 SU_MDRV_2_AW "SU_MDRV_2_AW";
BA_ "LongName" SG_ 1071 SU_MDRV_2_AW "Konfiguration_M-Drive_2_Allrad";
BA_ "SysSignalName" SG_ 1071 SU_MDRV_2_AW "SU_MDRV_2_AW";
BA_ "CompuMethodName" SG_ 775 CON_LVCH "CON_LVCH";
BA_ "ISignalName" SG_ 775 CON_LVCH "CON_LVCH";
BA_ "LongName" SG_ 775 CON_LVCH "Condition_Level-Change";
BA_ "SysSignalName" SG_ 775 CON_LVCH "CON_LVCH";
BA_ "CompuMethodName" SG_ 775 REAS_PREV_LVCH "REAS_PREV_LVCH";
BA_ "ISignalName" SG_ 775 REAS_PREV_LVCH "REAS_PREV_LVCH";
BA_ "LongName" SG_ 775 REAS_PREV_LVCH "Grund_Verhinderung_Niveauwechsel";
BA_ "SysSignalName" SG_ 775 REAS_PREV_LVCH "REAS_PREV_LVCH";
BA_ "CompuMethodName" SG_ 60 CRC_CON_VEH "CRC8";
BA_ "ISignalName" SG_ 60 CRC_CON_VEH "CRC_CON_VEH";
BA_ "LongName" SG_ 60 CRC_CON_VEH "CRC_Zustand_Fahrzeug";
BA_ "SysSignalName" SG_ 60 CRC_CON_VEH "CRC_CON_VEH";
BA_ "CompuMethodName" SG_ 60 ALIV_CON_VEH "ALIV_4_BIT_Unsigned_Integer";
BA_ "ISignalName" SG_ 60 ALIV_CON_VEH "ALIV_CON_VEH";
BA_ "LongName" SG_ 60 ALIV_CON_VEH "Alive_Zustand_Fahrzeug";
BA_ "SysSignalName" SG_ 60 ALIV_CON_VEH "ALIV_CON_VEH";
BA_ "CompuMethodName" SG_ 60 CTR_BS_PRTNT "CTR_BS_PRTNT";
BA_ "ISignalName" SG_ 60 CTR_BS_PRTNT "CTR_BS_PRTNT";
BA_ "LongName" SG_ 60 CTR_BS_PRTNT "Steuerung_Basis_Teilnetze";
BA_ "SysSignalName" SG_ 60 CTR_BS_PRTNT "CTR_BS_PRTNT";
BA_ "CompuMethodName" SG_ 60 CTR_FKTN_PRTNT "Anforderung_Funktionale_Teilnetze";
BA_ "ISignalName" SG_ 60 CTR_FKTN_PRTNT "CTR_FKTN_PRTNT";
BA_ "LongName" SG_ 60 CTR_FKTN_PRTNT "Steuerung_Funktionale_Teilnetze";
BA_ "SysSignalName" SG_ 60 CTR_FKTN_PRTNT "CTR_FKTN_PRTNT";
BA_ "CompuMethodName" SG_ 60 ST_CON_VEH "ST_CON_VEH";
BA_ "ISignalName" SG_ 60 ST_CON_VEH "ST_CON_VEH";
BA_ "LongName" SG_ 60 ST_CON_VEH "Status_Zustand_Fahrzeug";
BA_ "SysSignalName" SG_ 60 ST_CON_VEH "ST_CON_VEH";
BA_ "CompuMethodName" SG_ 60 QU_ST_CON_VEH "QU_ST_CON_VEH";
BA_ "ISignalName" SG_ 60 QU_ST_CON_VEH "QU_ST_CON_VEH";
BA_ "LongName" SG_ 60 QU_ST_CON_VEH "Qualifier_Status_Zustand_Fahrzeug";
BA_ "SysSignalName" SG_ 60 QU_ST_CON_VEH "QU_ST_CON_VEH";
BA_ "ISignalName" SG_ 60 CON_VEH_dummy_56_63 "CON_VEH_dummy_56_63";
BA_ "LongName" SG_ 60 CON_VEH_dummy_56_63 "CON_VEH_dummy_56_63";
BA_ "SysSignalName" SG_ 60 CON_VEH_dummy_56_63 "CON_VEH_dummy_56_63";
BA_ "CompuMethodName" SG_ 908 RLS_ACCM "RLS_ACCM";
BA_ "ISignalName" SG_ 908 RLS_ACCM "RLS_ACCM";
BA_ "LongName" SG_ 908 RLS_ACCM "Freigabe_Klimakompressor";
BA_ "SysSignalName" SG_ 908 RLS_ACCM "RLS_ACCM";
BA_ "CompuMethodName" SG_ 908 RLS_PRECOND_PAIC "RLS_PRECOND_PAIC";
BA_ "ISignalName" SG_ 908 RLS_PRECOND_PAIC "RLS_PRECOND_PAIC";
BA_ "LongName" SG_ 908 RLS_PRECOND_PAIC "Freigabe_Vorkonditionierung_Standklima";
BA_ "SysSignalName" SG_ 908 RLS_PRECOND_PAIC "RLS_PRECOND_PAIC";
BA_ "CompuMethodName" SG_ 871 QUAN_SER_BOS_DISP "QUAN_SER_BOS_DISP";
BA_ "GenSigStartValue" SG_ 871 QUAN_SER_BOS_DISP 1;
BA_ "ISignalName" SG_ 871 QUAN_SER_BOS_DISP "QUAN_SER_BOS_DISP";
BA_ "LongName" SG_ 871 QUAN_SER_BOS_DISP "Anzahl_Service_BOS_Anzeige";
BA_ "SysSignalName" SG_ 871 QUAN_SER_BOS_DISP "QUAN_SER_BOS_DISP";
BA_ "CompuMethodName" SG_ 871 NO_SER_BOS_DISP "NO_SER_BOS_DISP";
BA_ "GenSigStartValue" SG_ 871 NO_SER_BOS_DISP 1;
BA_ "ISignalName" SG_ 871 NO_SER_BOS_DISP "NO_SER_BOS_DISP";
BA_ "LongName" SG_ 871 NO_SER_BOS_DISP "Nummer_Service_BOS_Anzeige";
BA_ "SysSignalName" SG_ 871 NO_SER_BOS_DISP "NO_SER_BOS_DISP";
BA_ "CompuMethodName" SG_ 871 ID_FN_BOS_DISP "ID_FN_BOS_DISP";
BA_ "ISignalName" SG_ 871 ID_FN_BOS_DISP "ID_FN_BOS_DISP";
BA_ "LongName" SG_ 871 ID_FN_BOS_DISP "ID_Funktion_BOS_Anzeige";
BA_ "SysSignalName" SG_ 871 ID_FN_BOS_DISP "ID_FN_BOS_DISP";
BA_ "CompuMethodName" SG_ 871 VL_GAP_BOS_DISP "VL_GAP_BOS_DISP";
BA_ "ISignalName" SG_ 871 VL_GAP_BOS_DISP "VL_GAP_BOS_DISP";
BA_ "LongName" SG_ 871 VL_GAP_BOS_DISP "Wert_Abstand_BOS_Anzeige";
BA_ "SysSignalName" SG_ 871 VL_GAP_BOS_DISP "VL_GAP_BOS_DISP";
BA_ "CompuMethodName" SG_ 871 YR_BOS_DISP "YR_BOS_DISP";
BA_ "GenSigStartValue" SG_ 871 YR_BOS_DISP 2001;
BA_ "ISignalName" SG_ 871 YR_BOS_DISP "YR_BOS_DISP";
BA_ "LongName" SG_ 871 YR_BOS_DISP "Jahr_BOS_Anzeige";
BA_ "SysSignalName" SG_ 871 YR_BOS_DISP "YR_BOS_DISP";
BA_ "CompuMethodName" SG_ 871 MON_BOS_DISP "MON_BOS_DISP";
BA_ "GenSigStartValue" SG_ 871 MON_BOS_DISP 1;
BA_ "ISignalName" SG_ 871 MON_BOS_DISP "MON_BOS_DISP";
BA_ "LongName" SG_ 871 MON_BOS_DISP "Monat_BOS_Anzeige";
BA_ "SysSignalName" SG_ 871 MON_BOS_DISP "MON_BOS_DISP";
BA_ "CompuMethodName" SG_ 871 UN_FACT_BOS_DISP "UN_FACT_BOS_DISP";
BA_ "ISignalName" SG_ 871 UN_FACT_BOS_DISP "UN_FACT_BOS_DISP";
BA_ "LongName" SG_ 871 UN_FACT_BOS_DISP "Einheit_Faktor_BOS_Anzeige";
BA_ "SysSignalName" SG_ 871 UN_FACT_BOS_DISP "UN_FACT_BOS_DISP";
BA_ "CompuMethodName" SG_ 871 CL_BOS_DISP "CL_BOS_DISP";
BA_ "ISignalName" SG_ 871 CL_BOS_DISP "CL_BOS_DISP";
BA_ "LongName" SG_ 871 CL_BOS_DISP "Farbe_BOS_Anzeige";
BA_ "SysSignalName" SG_ 871 CL_BOS_DISP "CL_BOS_DISP";
BA_ "CompuMethodName" SG_ 871 UN_WAY_BOS_DISP "UN_WAY_BOS_DISP";
BA_ "ISignalName" SG_ 871 UN_WAY_BOS_DISP "UN_WAY_BOS_DISP";
BA_ "LongName" SG_ 871 UN_WAY_BOS_DISP "Einheit_Weg_BOS_Anzeige";
BA_ "SysSignalName" SG_ 871 UN_WAY_BOS_DISP "UN_WAY_BOS_DISP";
BA_ "CompuMethodName" SG_ 700 CTR_CHGP_LOK_CSM "CTR_CHGP_LOK_CSM";
BA_ "ISignalName" SG_ 700 CTR_CHGP_LOK_CSM "CTR_CHGP_LOK_CSM";
BA_ "LongName" SG_ 700 CTR_CHGP_LOK_CSM "Steuerung_Ladestecker_Verriegeln_CSM";
BA_ "SysSignalName" SG_ 700 CTR_CHGP_LOK_CSM "CTR_CHGP_LOK_CSM";
BA_ "CompuMethodName" SG_ 524 CTR_SLCTN_RMV "Steurung_SLCTN_RMV";
BA_ "ISignalName" SG_ 524 CTR_SLCTN_RMV "CTR_SLCTN_RMV";
BA_ "LongName" SG_ 524 CTR_SLCTN_RMV "Steuerung_Auswahl_Entfernen";
BA_ "SysSignalName" SG_ 524 CTR_SLCTN_RMV "CTR_SLCTN_RMV";
BA_ "CompuMethodName" SG_ 978 RQ_ENGMG_RST_OBD_DIAG "RQ_RST_OBD_DIAG";
BA_ "ISignalName" SG_ 978 RQ_ENGMG_RST_OBD_DIAG "RQ_ENGMG_RST_OBD_DIAG";
BA_ "LongName" SG_ 978 RQ_ENGMG_RST_OBD_DIAG "Anforderung_Motorsteuerung_Reset_OBD_Diagnose";
BA_ "SysSignalName" SG_ 978 RQ_ENGMG_RST_OBD_DIAG "RQ_ENGMG_RST_OBD_DIAG";
BA_ "CompuMethodName" SG_ 222 ALIV_CTR_DISP_M_SYS "ALIV_4_BIT_Unsigned_Integer";
BA_ "ISignalName" SG_ 222 ALIV_CTR_DISP_M_SYS "ALIV_CTR_DISP_M_SYS";
BA_ "LongName" SG_ 222 ALIV_CTR_DISP_M_SYS "Alive_Steuerung_Anzeige_M_System";
BA_ "SysSignalName" SG_ 222 ALIV_CTR_DISP_M_SYS "ALIV_CTR_DISP_M_SYS";
BA_ "CompuMethodName" SG_ 222 CTR_DSC_PUP_INQY "CTR_DSC_PUP_INQY";
BA_ "ISignalName" SG_ 222 CTR_DSC_PUP_INQY "CTR_DSC_PUP_INQY";
BA_ "LongName" SG_ 222 CTR_DSC_PUP_INQY "Steuerung_DSC_Pop-up_Anfrage";
BA_ "SysSignalName" SG_ 222 CTR_DSC_PUP_INQY "CTR_DSC_PUP_INQY";
BA_ "CompuMethodName" SG_ 222 CTR_SYS_PUP_INQY "CTR_SYS_PUP_INQY";
BA_ "ISignalName" SG_ 222 CTR_SYS_PUP_INQY "CTR_SYS_PUP_INQY";
BA_ "LongName" SG_ 222 CTR_SYS_PUP_INQY "Steuerung_System_Pop-up_Anfrage";
BA_ "SysSignalName" SG_ 222 CTR_SYS_PUP_INQY "CTR_SYS_PUP_INQY";
BA_ "CompuMethodName" SG_ 222 CTR_DISP_MDRV_3 "CTR_DISP_MDRV_3";
BA_ "ISignalName" SG_ 222 CTR_DISP_MDRV_3 "CTR_DISP_MDRV_3";
BA_ "LongName" SG_ 222 CTR_DISP_MDRV_3 "control_display_M-Drive_3";
BA_ "SysSignalName" SG_ 222 CTR_DISP_MDRV_3 "CTR_DISP_MDRV_3";
BA_ "CompuMethodName" SG_ 222 CTR_DISP_EPAS_MOD "CTR_DISP_MOD";
BA_ "ISignalName" SG_ 222 CTR_DISP_EPAS_MOD "CTR_DISP_EPAS_MOD";
BA_ "LongName" SG_ 222 CTR_DISP_EPAS_MOD "Steuerung_Anzeige_Servotronic_Modus";
BA_ "SysSignalName" SG_ 222 CTR_DISP_EPAS_MOD "CTR_DISP_EPAS_MOD";
BA_ "CompuMethodName" SG_ 222 CTR_DISP_FN_9_MIKO "CTR_DISP_FN_9_MIKO";
BA_ "ISignalName" SG_ 222 CTR_DISP_FN_9_MIKO "CTR_DISP_FN_9_MIKO";
BA_ "LongName" SG_ 222 CTR_DISP_FN_9_MIKO "Steuerung_Anzeige_Funktion_9_MIKO";
BA_ "SysSignalName" SG_ 222 CTR_DISP_FN_9_MIKO "CTR_DISP_FN_9_MIKO";
BA_ "CompuMethodName" SG_ 222 CTR_DISP_EDC_MOD "CTR_DISP_MOD";
BA_ "ISignalName" SG_ 222 CTR_DISP_EDC_MOD "CTR_DISP_EDC_MOD";
BA_ "LongName" SG_ 222 CTR_DISP_EDC_MOD "Steuerung_Anzeige_Eletronische-Dämpfer-Steuerung_Modus";
BA_ "SysSignalName" SG_ 222 CTR_DISP_EDC_MOD "CTR_DISP_EDC_MOD";
BA_ "CompuMethodName" SG_ 222 CTR_DISP_ENG_MOD "CTR_DISP_MOD";
BA_ "ISignalName" SG_ 222 CTR_DISP_ENG_MOD "CTR_DISP_ENG_MOD";
BA_ "LongName" SG_ 222 CTR_DISP_ENG_MOD "Steuerung_Anzeige_Motor_Modus";
BA_ "SysSignalName" SG_ 222 CTR_DISP_ENG_MOD "CTR_DISP_ENG_MOD";
BA_ "CompuMethodName" SG_ 222 CTR_DISP_ASR_MOD "CTR_DISP_ASR_MOD";
BA_ "ISignalName" SG_ 222 CTR_DISP_ASR_MOD "CTR_DISP_ASR_MOD";
BA_ "LongName" SG_ 222 CTR_DISP_ASR_MOD "Steuerung_Anzeige_ASR_Modus";
BA_ "SysSignalName" SG_ 222 CTR_DISP_ASR_MOD "CTR_DISP_ASR_MOD";
BA_ "CompuMethodName" SG_ 222 RPM_TEMP_DOM_YE "RPM_TEMP_DOM";
BA_ "ISignalName" SG_ 222 RPM_TEMP_DOM_YE "RPM_TEMP_DOM_YE";
BA_ "LongName" SG_ 222 RPM_TEMP_DOM_YE "Drehzahl_Temperatur_Bereich_gelb";
BA_ "SysSignalName" SG_ 222 RPM_TEMP_DOM_YE "RPM_TEMP_DOM_YE";
BA_ "CompuMethodName" SG_ 222 RPM_TEMP_DOM_RE "RPM_TEMP_DOM";
BA_ "ISignalName" SG_ 222 RPM_TEMP_DOM_RE "RPM_TEMP_DOM_RE";
BA_ "LongName" SG_ 222 RPM_TEMP_DOM_RE "Drehzahl_Temperatur_Bereich_rot";
BA_ "SysSignalName" SG_ 222 RPM_TEMP_DOM_RE "RPM_TEMP_DOM_RE";
BA_ "CompuMethodName" SG_ 222 CTR_DISP_DRVGMOD "CTR_DISP_DRVGMOD";
BA_ "ISignalName" SG_ 222 CTR_DISP_DRVGMOD "CTR_DISP_DRVGMOD";
BA_ "LongName" SG_ 222 CTR_DISP_DRVGMOD "Steuerung_Anzeige_Fahrmodus";
BA_ "SysSignalName" SG_ 222 CTR_DISP_DRVGMOD "CTR_DISP_DRVGMOD";
BA_ "CompuMethodName" SG_ 222 CTR_DISP_LST_DRVGMOD "CTR_DISP_LST_DRVGMOD";
BA_ "ISignalName" SG_ 222 CTR_DISP_LST_DRVGMOD "CTR_DISP_LST_DRVGMOD";
BA_ "LongName" SG_ 222 CTR_DISP_LST_DRVGMOD "Steuerung_Anzeige_Liste_Fahrmodus";
BA_ "SysSignalName" SG_ 222 CTR_DISP_LST_DRVGMOD "CTR_DISP_LST_DRVGMOD";
BA_ "CompuMethodName" SG_ 222 CTR_DISP_PUP_KI_INQY "CTR_DISP_PUP_KI_INQY";
BA_ "ISignalName" SG_ 222 CTR_DISP_PUP_KI_INQY "CTR_DISP_PUP_KI_INQY";
BA_ "LongName" SG_ 222 CTR_DISP_PUP_KI_INQY "Steuerung_Anzeige_Pop-up_Kombi_Anfrage";
BA_ "SysSignalName" SG_ 222 CTR_DISP_PUP_KI_INQY "CTR_DISP_PUP_KI_INQY";
BA_ "CompuMethodName" SG_ 222 CTR_DISP_PUP_KI_INFO "CTR_DISP_PUP_KI_INFO";
BA_ "ISignalName" SG_ 222 CTR_DISP_PUP_KI_INFO "CTR_DISP_PUP_KI_INFO";
BA_ "LongName" SG_ 222 CTR_DISP_PUP_KI_INFO "Steuerung_Anzeige_Pop-up_Kombi_Information";
BA_ "SysSignalName" SG_ 222 CTR_DISP_PUP_KI_INFO "CTR_DISP_PUP_KI_INFO";
BA_ "CompuMethodName" SG_ 222 CTR_DISP_CID "CTR_DISP_CID";
BA_ "ISignalName" SG_ 222 CTR_DISP_CID "CTR_DISP_CID";
BA_ "LongName" SG_ 222 CTR_DISP_CID "Steuerung_Anzeige_CID";
BA_ "SysSignalName" SG_ 222 CTR_DISP_CID "CTR_DISP_CID";
BA_ "CompuMethodName" SG_ 853 CTR_DRVBH_2_DISP "CTR_DRVBH_2_DISP";
BA_ "ISignalName" SG_ 853 CTR_DRVBH_2_DISP "CTR_DRVBH_2_DISP";
BA_ "LongName" SG_ 853 CTR_DRVBH_2_DISP "Steuerung_Fahrstil_2_Anzeige";
BA_ "SysSignalName" SG_ 853 CTR_DRVBH_2_DISP "CTR_DRVBH_2_DISP";
BA_ "CompuMethodName" SG_ 202 CRC_CTR_FNS_IDC "CRC8";
BA_ "ISignalName" SG_ 202 CRC_CTR_FNS_IDC "CRC_CTR_FNS_IDC";
BA_ "LongName" SG_ 202 CRC_CTR_FNS_IDC "CRC_Steuerung_Funktionen_Blinken";
BA_ "SysSignalName" SG_ 202 CRC_CTR_FNS_IDC "CRC_CTR_FNS_IDC";
BA_ "CompuMethodName" SG_ 202 ALIV_CTR_FNS_IDC "ALIV_CTR_FNS_IDC";
BA_ "ISignalName" SG_ 202 ALIV_CTR_FNS_IDC "ALIV_CTR_FNS_IDC";
BA_ "LongName" SG_ 202 ALIV_CTR_FNS_IDC "Alive_Steuerung_Funktionen_Blinken";
BA_ "SysSignalName" SG_ 202 ALIV_CTR_FNS_IDC "ALIV_CTR_FNS_IDC";
BA_ "CompuMethodName" SG_ 202 CHL_CTR_FN_IDC "CHL_CTR_FN_IDC";
BA_ "ISignalName" SG_ 202 CHL_CTR_FN_IDC "CHL_CTR_FN_IDC";
BA_ "LongName" SG_ 202 CHL_CTR_FN_IDC "CHL_Steuerung_Funktion_Blinken";
BA_ "SysSignalName" SG_ 202 CHL_CTR_FN_IDC "CHL_CTR_FN_IDC";
BA_ "CompuMethodName" SG_ 202 CTR_FREQ_IDC "CTR_FREQ_IDC";
BA_ "ISignalName" SG_ 202 CTR_FREQ_IDC "CTR_FREQ_IDC";
BA_ "LongName" SG_ 202 CTR_FREQ_IDC "Steuerung_Frequenz_Blinken";
BA_ "SysSignalName" SG_ 202 CTR_FREQ_IDC "CTR_FREQ_IDC";
BA_ "CompuMethodName" SG_ 202 CTR_SYNC_IDC "CTR_SYNC_IDC";
BA_ "ISignalName" SG_ 202 CTR_SYNC_IDC "CTR_SYNC_IDC";
BA_ "LongName" SG_ 202 CTR_SYNC_IDC "Steuerung_Sync_Blinken";
BA_ "SysSignalName" SG_ 202 CTR_SYNC_IDC "CTR_SYNC_IDC";
BA_ "CompuMethodName" SG_ 202 CTR_IDC "CTR_IDC";
BA_ "ISignalName" SG_ 202 CTR_IDC "CTR_IDC";
BA_ "LongName" SG_ 202 CTR_IDC "Steuerung_Blinken";
BA_ "SysSignalName" SG_ 202 CTR_IDC "CTR_IDC";
BA_ "CompuMethodName" SG_ 202 CTR_DISP_IDC "CTR_IDC_DISP";
BA_ "ISignalName" SG_ 202 CTR_DISP_IDC "CTR_DISP_IDC";
BA_ "LongName" SG_ 202 CTR_DISP_IDC "Steuerung_Anzeige_Blinken";
BA_ "SysSignalName" SG_ 202 CTR_DISP_IDC "CTR_DISP_IDC";
BA_ "CompuMethodName" SG_ 202 ACV_FN_IDC "ACV_FN_IDC";
BA_ "ISignalName" SG_ 202 ACV_FN_IDC "ACV_FN_IDC";
BA_ "LongName" SG_ 202 ACV_FN_IDC "Aktiv_Funktion_Blinken";
BA_ "SysSignalName" SG_ 202 ACV_FN_IDC "ACV_FN_IDC";
BA_ "CompuMethodName" SG_ 202 OVLY_FN_IDC "OVLY_FN_IDC";
BA_ "ISignalName" SG_ 202 OVLY_FN_IDC "OVLY_FN_IDC";
BA_ "LongName" SG_ 202 OVLY_FN_IDC "Overlay_Funktion_Blinken";
BA_ "SysSignalName" SG_ 202 OVLY_FN_IDC "OVLY_FN_IDC";
BA_ "CompuMethodName" SG_ 202 CTR_T_MSECS_IDC "CTR_T_MSECS_IDC";
BA_ "ISignalName" SG_ 202 CTR_T_MSECS_IDC "CTR_T_MSECS_IDC";
BA_ "LongName" SG_ 202 CTR_T_MSECS_IDC "control_time_milliseconds_indicate-direction";
BA_ "SysSignalName" SG_ 202 CTR_T_MSECS_IDC "CTR_T_MSECS_IDC";
BA_ "CompuMethodName" SG_ 202 CTR_T_SECS_IDC "CTR_T_SECS_IDC";
BA_ "ISignalName" SG_ 202 CTR_T_SECS_IDC "CTR_T_SECS_IDC";
BA_ "LongName" SG_ 202 CTR_T_SECS_IDC "Steuerung_Zeit_Sekunden_Blinken";
BA_ "SysSignalName" SG_ 202 CTR_T_SECS_IDC "CTR_T_SECS_IDC";
BA_ "ISignalName" SG_ 202 CTR_FN_IDC_dummy_62_63 "CTR_FN_IDC_dummy_62_63";
BA_ "LongName" SG_ 202 CTR_FN_IDC_dummy_62_63 "CTR_FN_IDC_dummy_62_63";
BA_ "SysSignalName" SG_ 202 CTR_FN_IDC_dummy_62_63 "CTR_FN_IDC_dummy_62_63";
BA_ "CompuMethodName" SG_ 556 CTR_SPN_ANG_GZA_LH "CTR_SPN_ANG_GZA";
BA_ "GenSigStartValue" SG_ 556 CTR_SPN_ANG_GZA_LH -12;
BA_ "ISignalName" SG_ 556 CTR_SPN_ANG_GZA_LH "CTR_SPN_ANG_GZA_LH";
BA_ "LongName" SG_ 556 CTR_SPN_ANG_GZA_LH "Steuerung_Schwenk_Winkel_GZA_Links";
BA_ "SysSignalName" SG_ 556 CTR_SPN_ANG_GZA_LH "CTR_SPN_ANG_GZA_LH";
BA_ "CompuMethodName" SG_ 556 CTR_SPN_ANG_GZA_RH "CTR_SPN_ANG_GZA";
BA_ "GenSigStartValue" SG_ 556 CTR_SPN_ANG_GZA_RH -12;
BA_ "ISignalName" SG_ 556 CTR_SPN_ANG_GZA_RH "CTR_SPN_ANG_GZA_RH";
BA_ "LongName" SG_ 556 CTR_SPN_ANG_GZA_RH "Steuerung_Schwenk_Winkel_GZA_Rechts";
BA_ "SysSignalName" SG_ 556 CTR_SPN_ANG_GZA_RH "CTR_SPN_ANG_GZA_RH";
BA_ "CompuMethodName" SG_ 556 CTR_DIST_OBJ_GZA_LH "CTR_DIST_OBJ_GZA";
BA_ "GenSigStartValue" SG_ 556 CTR_DIST_OBJ_GZA_LH 20;
BA_ "ISignalName" SG_ 556 CTR_DIST_OBJ_GZA_LH "CTR_DIST_OBJ_GZA_LH";
BA_ "LongName" SG_ 556 CTR_DIST_OBJ_GZA_LH "Steuerung_Distanz_Objekt_GZA_Links";
BA_ "SysSignalName" SG_ 556 CTR_DIST_OBJ_GZA_LH "CTR_DIST_OBJ_GZA_LH";
BA_ "CompuMethodName" SG_ 556 CTR_DIST_OBJ_GZA_RH "CTR_DIST_OBJ_GZA";
BA_ "GenSigStartValue" SG_ 556 CTR_DIST_OBJ_GZA_RH 20;
BA_ "ISignalName" SG_ 556 CTR_DIST_OBJ_GZA_RH "CTR_DIST_OBJ_GZA_RH";
BA_ "LongName" SG_ 556 CTR_DIST_OBJ_GZA_RH "Steuerung_Distanz_Objekt_GZA_Rechts";
BA_ "SysSignalName" SG_ 556 CTR_DIST_OBJ_GZA_RH "CTR_DIST_OBJ_GZA_RH";
BA_ "CompuMethodName" SG_ 556 CTR_GZADL "CTR_GZADL";
BA_ "ISignalName" SG_ 556 CTR_GZADL "CTR_GZADL";
BA_ "LongName" SG_ 556 CTR_GZADL "Steuerung_GZA-Designleuchte";
BA_ "SysSignalName" SG_ 556 CTR_GZADL "CTR_GZADL";
BA_ "CompuMethodName" SG_ 556 CTR_MOD_GZA_LH "CTR_MOD_GZA";
BA_ "ISignalName" SG_ 556 CTR_MOD_GZA_LH "CTR_MOD_GZA_LH";
BA_ "LongName" SG_ 556 CTR_MOD_GZA_LH "Steuerung_Modus_GZA_Links";
BA_ "SysSignalName" SG_ 556 CTR_MOD_GZA_LH "CTR_MOD_GZA_LH";
BA_ "CompuMethodName" SG_ 556 CTR_MOD_GZA_RH "CTR_MOD_GZA";
BA_ "ISignalName" SG_ 556 CTR_MOD_GZA_RH "CTR_MOD_GZA_RH";
BA_ "LongName" SG_ 556 CTR_MOD_GZA_RH "Steuerung_Modus_GZA_Rechts";
BA_ "SysSignalName" SG_ 556 CTR_MOD_GZA_RH "CTR_MOD_GZA_RH";
BA_ "CompuMethodName" SG_ 548 CTR_IDLI_DIPB "CTR_IDLI_DIPB";
BA_ "ISignalName" SG_ 548 CTR_IDLI_DIPB "CTR_IDLI_DIPB";
BA_ "LongName" SG_ 548 CTR_IDLI_DIPB "Steuerung_Kontrolleuchte_Abblendlicht";
BA_ "SysSignalName" SG_ 548 CTR_IDLI_DIPB "CTR_IDLI_DIPB";
BA_ "CompuMethodName" SG_ 548 CTR_IDLI_MBHF "CTR_IDLI_MBHF";
BA_ "ISignalName" SG_ 548 CTR_IDLI_MBHF "CTR_IDLI_MBHF";
BA_ "LongName" SG_ 548 CTR_IDLI_MBHF "Steuerung_Kontrolleuchte_Fernlicht/Lichthupe";
BA_ "SysSignalName" SG_ 548 CTR_IDLI_MBHF "CTR_IDLI_MBHF";
BA_ "CompuMethodName" SG_ 548 CTR_IDLI_POLI "CTR_IDLI_POLI";
BA_ "ISignalName" SG_ 548 CTR_IDLI_POLI "CTR_IDLI_POLI";
BA_ "LongName" SG_ 548 CTR_IDLI_POLI "Steuerung_Kontrolleuchte_Standlicht";
BA_ "SysSignalName" SG_ 548 CTR_IDLI_POLI "CTR_IDLI_POLI";
BA_ "CompuMethodName" SG_ 548 CTR_IDLI_FFLI "CTR_IDLI_FFLI";
BA_ "ISignalName" SG_ 548 CTR_IDLI_FFLI "CTR_IDLI_FFLI";
BA_ "LongName" SG_ 548 CTR_IDLI_FFLI "Steuerung_Kontrolleuchte_Nebelscheinwerfer";
BA_ "SysSignalName" SG_ 548 CTR_IDLI_FFLI "CTR_IDLI_FFLI";
BA_ "CompuMethodName" SG_ 548 CTR_IDLI_RFLI "CTR_IDLI_RFLI";
BA_ "ISignalName" SG_ 548 CTR_IDLI_RFLI "CTR_IDLI_RFLI";
BA_ "LongName" SG_ 548 CTR_IDLI_RFLI "Steuerung_Kontrolleuchte_Nebelschlußleuchte";
BA_ "SysSignalName" SG_ 548 CTR_IDLI_RFLI "CTR_IDLI_RFLI";
BA_ "CompuMethodName" SG_ 574 CTR_SWO_IDT_CHGNG_CA "CTR_SWO_IDT_CHGNG_CA";
BA_ "ISignalName" SG_ 574 CTR_SWO_IDT_CHGNG_CA "CTR_SWO_IDT_CHGNG_CA";
BA_ "LongName" SG_ 574 CTR_SWO_IDT_CHGNG_CA "Steuerung_Abschaltung_Induktiv_Laden_Comfort-Access";
BA_ "SysSignalName" SG_ 574 CTR_SWO_IDT_CHGNG_CA "CTR_SWO_IDT_CHGNG_CA";
BA_ "CompuMethodName" SG_ 747 CRC_CTR_LP_EX "CRC8";
BA_ "ISignalName" SG_ 747 CRC_CTR_LP_EX "CRC_CTR_LP_EX";
BA_ "LongName" SG_ 747 CRC_CTR_LP_EX "CRC_Steuerung_Licht_Außen";
BA_ "SysSignalName" SG_ 747 CRC_CTR_LP_EX "CRC_CTR_LP_EX";
BA_ "CompuMethodName" SG_ 747 ALIV_CTR_LP_EX "Aliv_4";
BA_ "ISignalName" SG_ 747 ALIV_CTR_LP_EX "ALIV_CTR_LP_EX";
BA_ "LongName" SG_ 747 ALIV_CTR_LP_EX "Alive_Steuerung_Licht_Außen";
BA_ "SysSignalName" SG_ 747 ALIV_CTR_LP_EX "ALIV_CTR_LP_EX";
BA_ "CompuMethodName" SG_ 747 CTR_BRIGLEV_LP_EX "CTR_BRIGLEV_LP_EX";
BA_ "ISignalName" SG_ 747 CTR_BRIGLEV_LP_EX "CTR_BRIGLEV_LP_EX";
BA_ "LongName" SG_ 747 CTR_BRIGLEV_LP_EX "Steuerung_Helligkeitswert_Licht_Außen";
BA_ "SysSignalName" SG_ 747 CTR_BRIGLEV_LP_EX "CTR_BRIGLEV_LP_EX";
BA_ "CompuMethodName" SG_ 747 CTR_FN_WELL "CTR_FN_WELL";
BA_ "ISignalName" SG_ 747 CTR_FN_WELL "CTR_FN_WELL";
BA_ "LongName" SG_ 747 CTR_FN_WELL "Steuerung_Funktion_Begrüßungslicht";
BA_ "SysSignalName" SG_ 747 CTR_FN_WELL "CTR_FN_WELL";
BA_ "CompuMethodName" SG_ 747 CTR_FN_RFLP "CTR_FN_RFLP";
BA_ "ISignalName" SG_ 747 CTR_FN_RFLP "CTR_FN_RFLP";
BA_ "LongName" SG_ 747 CTR_FN_RFLP "Steuerung_Funktion_Nebelschlußlicht";
BA_ "SysSignalName" SG_ 747 CTR_FN_RFLP "CTR_FN_RFLP";
BA_ "CompuMethodName" SG_ 747 CTR_FN_POLI "CTR_FN_POLI";
BA_ "ISignalName" SG_ 747 CTR_FN_POLI "CTR_FN_POLI";
BA_ "LongName" SG_ 747 CTR_FN_POLI "Steuerung_Funktion_Standlicht";
BA_ "SysSignalName" SG_ 747 CTR_FN_POLI "CTR_FN_POLI";
BA_ "CompuMethodName" SG_ 747 CTR_FN_PLI "CTR_FN_PLI";
BA_ "ISignalName" SG_ 747 CTR_FN_PLI "CTR_FN_PLI";
BA_ "LongName" SG_ 747 CTR_FN_PLI "Steuerung_Funktion_Parklicht";
BA_ "SysSignalName" SG_ 747 CTR_FN_PLI "CTR_FN_PLI";
BA_ "CompuMethodName" SG_ 747 CTR_FN_RVLP "CTR_FN_RVLP";
BA_ "ISignalName" SG_ 747 CTR_FN_RVLP "CTR_FN_RVLP";
BA_ "LongName" SG_ 747 CTR_FN_RVLP "Steuerung_Funktion_Rückfahrlicht";
BA_ "SysSignalName" SG_ 747 CTR_FN_RVLP "CTR_FN_RVLP";
BA_ "CompuMethodName" SG_ 747 CTR_FN_BFD "CTR_FN_BFD";
BA_ "ISignalName" SG_ 747 CTR_FN_BFD "CTR_FN_BFD";
BA_ "LongName" SG_ 747 CTR_FN_BFD "Steuerung_Funktion_Brake-Force-Display";
BA_ "SysSignalName" SG_ 747 CTR_FN_BFD "CTR_FN_BFD";
BA_ "CompuMethodName" SG_ 747 CTR_FN_DRL "CTR_FN_DRL";
BA_ "ISignalName" SG_ 747 CTR_FN_DRL "CTR_FN_DRL";
BA_ "LongName" SG_ 747 CTR_FN_DRL "Steuerung_Funktion_Tagfahrlicht";
BA_ "SysSignalName" SG_ 747 CTR_FN_DRL "CTR_FN_DRL";
BA_ "CompuMethodName" SG_ 747 CTR_FN_BL "CTR_FN_BL";
BA_ "ISignalName" SG_ 747 CTR_FN_BL "CTR_FN_BL";
BA_ "LongName" SG_ 747 CTR_FN_BL "Steuerung_Funktion_Bremslicht";
BA_ "SysSignalName" SG_ 747 CTR_FN_BL "CTR_FN_BL";
BA_ "CompuMethodName" SG_ 747 CTR_FN_FMH "CTR_FN_FMH";
BA_ "ISignalName" SG_ 747 CTR_FN_FMH "CTR_FN_FMH";
BA_ "LongName" SG_ 747 CTR_FN_FMH "Steuerung_Funktion_Heimleuchten";
BA_ "SysSignalName" SG_ 747 CTR_FN_FMH "CTR_FN_FMH";
BA_ "CompuMethodName" SG_ 747 CTR_FN_REMLI "ST_FN_REMLI";
BA_ "ISignalName" SG_ 747 CTR_FN_REMLI "CTR_FN_REMLI";
BA_ "LongName" SG_ 747 CTR_FN_REMLI "Steuerung_Funktion_Remote-Light";
BA_ "SysSignalName" SG_ 747 CTR_FN_REMLI "CTR_FN_REMLI";
BA_ "CompuMethodName" SG_ 747 CTR_FN_GBL "CTR_FN_GBL";
BA_ "ISignalName" SG_ 747 CTR_FN_GBL "CTR_FN_GBL";
BA_ "LongName" SG_ 747 CTR_FN_GBL "Steuerung_Funktion_Verabschiedungslicht";
BA_ "SysSignalName" SG_ 747 CTR_FN_GBL "CTR_FN_GBL";
BA_ "ISignalName" SG_ 747 CTR_LP_EX_dummy_56_63 "CTR_LP_EX_dummy_56_63";
BA_ "LongName" SG_ 747 CTR_LP_EX_dummy_56_63 "CTR_LP_EX_dummy_56_63";
BA_ "SysSignalName" SG_ 747 CTR_LP_EX_dummy_56_63 "CTR_LP_EX_dummy_56_63";
BA_ "CompuMethodName" SG_ 484 CRC_CTR_LP_EX_2 "CRC8";
BA_ "ISignalName" SG_ 484 CRC_CTR_LP_EX_2 "CRC_CTR_LP_EX_2";
BA_ "LongName" SG_ 484 CRC_CTR_LP_EX_2 "CRC_control_lamp_exterior_2";
BA_ "SysSignalName" SG_ 484 CRC_CTR_LP_EX_2 "CRC_CTR_LP_EX_2";
BA_ "CompuMethodName" SG_ 484 ALIV_CTR_LP_EX_2 "Aliv_4";
BA_ "ISignalName" SG_ 484 ALIV_CTR_LP_EX_2 "ALIV_CTR_LP_EX_2";
BA_ "LongName" SG_ 484 ALIV_CTR_LP_EX_2 "Alive_Steuerung_Licht_Außen_2";
BA_ "SysSignalName" SG_ 484 ALIV_CTR_LP_EX_2 "ALIV_CTR_LP_EX_2";
BA_ "CompuMethodName" SG_ 484 ControlFunctionLaserLeftHand "ControlFunctionLaserLeftHand";
BA_ "ISignalName" SG_ 484 ControlFunctionLaserLeftHand "ControlFunctionLaserLeftHand";
BA_ "LongName" SG_ 484 ControlFunctionLaserLeftHand "ControlFunctionLaserLeftHand";
BA_ "SysSignalName" SG_ 484 ControlFunctionLaserLeftHand "ControlFunctionLaserLeftHand";
BA_ "CompuMethodName" SG_ 484 ControlFunctionLaserRightHand "ControlFunctionLaserRightHand";
BA_ "ISignalName" SG_ 484 ControlFunctionLaserRightHand "ControlFunctionLaserRightHand";
BA_ "LongName" SG_ 484 ControlFunctionLaserRightHand "ControlFunctionLaserRightHand";
BA_ "SysSignalName" SG_ 484 ControlFunctionLaserRightHand "ControlFunctionLaserRightHand";
BA_ "CompuMethodName" SG_ 484 CTR_FN_DIPB_LH "CTR_FN_DIPB_LH";
BA_ "ISignalName" SG_ 484 CTR_FN_DIPB_LH "CTR_FN_DIPB_LH";
BA_ "LongName" SG_ 484 CTR_FN_DIPB_LH "Steuerung_Funktion_Abblendlicht_Links";
BA_ "SysSignalName" SG_ 484 CTR_FN_DIPB_LH "CTR_FN_DIPB_LH";
BA_ "CompuMethodName" SG_ 484 CTR_LDSTR_LOWB_LH "CTR_LDSTR_LOWB";
BA_ "ISignalName" SG_ 484 CTR_LDSTR_LOWB_LH "CTR_LDSTR_LOWB_LH";
BA_ "LongName" SG_ 484 CTR_LDSTR_LOWB_LH "Steuerung_Lichtverteilung_Fahrlicht_Links";
BA_ "SysSignalName" SG_ 484 CTR_LDSTR_LOWB_LH "CTR_LDSTR_LOWB_LH";
BA_ "CompuMethodName" SG_ 484 CTR_FN_DIPB_RH "CTR_FN_DIPB_RH";
BA_ "ISignalName" SG_ 484 CTR_FN_DIPB_RH "CTR_FN_DIPB_RH";
BA_ "LongName" SG_ 484 CTR_FN_DIPB_RH "Steuerung_Funktion_Abblendlicht_Rechts";
BA_ "SysSignalName" SG_ 484 CTR_FN_DIPB_RH "CTR_FN_DIPB_RH";
BA_ "CompuMethodName" SG_ 484 CTR_LDSTR_LOWB_RH "CTR_LDSTR_LOWB";
BA_ "ISignalName" SG_ 484 CTR_LDSTR_LOWB_RH "CTR_LDSTR_LOWB_RH";
BA_ "LongName" SG_ 484 CTR_LDSTR_LOWB_RH "Steuerung_Lichtverteilung_Fahrlicht_Rechts";
BA_ "SysSignalName" SG_ 484 CTR_LDSTR_LOWB_RH "CTR_LDSTR_LOWB_RH";
BA_ "CompuMethodName" SG_ 484 CTR_FN_CORNL_LH "CTR_FN_CORNL_LH";
BA_ "ISignalName" SG_ 484 CTR_FN_CORNL_LH "CTR_FN_CORNL_LH";
BA_ "LongName" SG_ 484 CTR_FN_CORNL_LH "Steuerung_Funktion_Abbiegelicht_Links";
BA_ "SysSignalName" SG_ 484 CTR_FN_CORNL_LH "CTR_FN_CORNL_LH";
BA_ "CompuMethodName" SG_ 484 CTR_FN_CORNL_RH "CTR_FN_CORNL_RH";
BA_ "ISignalName" SG_ 484 CTR_FN_CORNL_RH "CTR_FN_CORNL_RH";
BA_ "LongName" SG_ 484 CTR_FN_CORNL_RH "Steuerung_Funktion_Abbiegelicht_Rechts";
BA_ "SysSignalName" SG_ 484 CTR_FN_CORNL_RH "CTR_FN_CORNL_RH";
BA_ "CompuMethodName" SG_ 484 CTR_PHA_FN_SPFLS "CTR_PHA_FN_SPFLS";
BA_ "ISignalName" SG_ 484 CTR_PHA_FN_SPFLS "CTR_PHA_FN_SPFLS";
BA_ "LongName" SG_ 484 CTR_PHA_FN_SPFLS "Steuerung_Phase_Funktion_Sonderblinken";
BA_ "SysSignalName" SG_ 484 CTR_PHA_FN_SPFLS "CTR_PHA_FN_SPFLS";
BA_ "CompuMethodName" SG_ 484 CTR_MOD_FN_SPFLS "MOD_FN_SPFLS";
BA_ "ISignalName" SG_ 484 CTR_MOD_FN_SPFLS "CTR_MOD_FN_SPFLS";
BA_ "LongName" SG_ 484 CTR_MOD_FN_SPFLS "Steuerung_Modus_Funktion_Sonderblinken";
BA_ "SysSignalName" SG_ 484 CTR_MOD_FN_SPFLS "CTR_MOD_FN_SPFLS";
BA_ "CompuMethodName" SG_ 484 CTR_FN_MAB "CTR_FN_MAB";
BA_ "ISignalName" SG_ 484 CTR_FN_MAB "CTR_FN_MAB";
BA_ "LongName" SG_ 484 CTR_FN_MAB "Steuerung_Funktion_Fernlicht";
BA_ "SysSignalName" SG_ 484 CTR_FN_MAB "CTR_FN_MAB";
BA_ "CompuMethodName" SG_ 484 CTR_FN_OVT "CTR_FN_OVT";
BA_ "ISignalName" SG_ 484 CTR_FN_OVT "CTR_FN_OVT";
BA_ "LongName" SG_ 484 CTR_FN_OVT "Steuerung_Funktion_OVT";
BA_ "SysSignalName" SG_ 484 CTR_FN_OVT "CTR_FN_OVT";
BA_ "CompuMethodName" SG_ 484 CTR_FN_FFLI "CTR_FN_FFLI";
BA_ "ISignalName" SG_ 484 CTR_FN_FFLI "CTR_FN_FFLI";
BA_ "LongName" SG_ 484 CTR_FN_FFLI "Steuerung_Funktion_Nebelscheinwerfer";
BA_ "SysSignalName" SG_ 484 CTR_FN_FFLI "CTR_FN_FFLI";
BA_ "CompuMethodName" SG_ 484 CTR_FN_ML "CTR_FN_ML";
BA_ "ISignalName" SG_ 484 CTR_FN_ML "CTR_FN_ML";
BA_ "LongName" SG_ 484 CTR_FN_ML "Steuerung_Funktion_Rangierlicht";
BA_ "SysSignalName" SG_ 484 CTR_FN_ML "CTR_FN_ML";
BA_ "CompuMethodName" SG_ 773 TAR_LEV_LVCH "TAR_LEV_LVCH";
BA_ "ISignalName" SG_ 773 TAR_LEV_LVCH "TAR_LEV_LVCH";
BA_ "LongName" SG_ 773 TAR_LEV_LVCH "Target_Level_Level-Change";
BA_ "SysSignalName" SG_ 773 TAR_LEV_LVCH "TAR_LEV_LVCH";
BA_ "CompuMethodName" SG_ 658 CTR_MAB "CTR_MAB";
BA_ "ISignalName" SG_ 658 CTR_MAB "CTR_MAB";
BA_ "LongName" SG_ 658 CTR_MAB "Steuerung_Fernlicht";
BA_ "SysSignalName" SG_ 658 CTR_MAB "CTR_MAB";
BA_ "CompuMethodName" SG_ 658 VLDY_OBJ_DT "VLDY_OBJ_DT";
BA_ "ISignalName" SG_ 658 VLDY_OBJ_DT "VLDY_OBJ_DT";
BA_ "LongName" SG_ 658 VLDY_OBJ_DT "Gültigkeit_Objekt_Daten";
BA_ "SysSignalName" SG_ 658 VLDY_OBJ_DT "VLDY_OBJ_DT";
BA_ "CompuMethodName" SG_ 658 QUAN_DOM_NGL "QUAN_DOM_NGL";
BA_ "ISignalName" SG_ 658 QUAN_DOM_NGL "QUAN_DOM_NGL";
BA_ "LongName" SG_ 658 QUAN_DOM_NGL "Anzahl_Bereich_Blendfrei";
BA_ "SysSignalName" SG_ 658 QUAN_DOM_NGL "QUAN_DOM_NGL";
BA_ "CompuMethodName" SG_ 658 REAS_SWO_MAB "REAS_SWO_MAB";
BA_ "ISignalName" SG_ 658 REAS_SWO_MAB "REAS_SWO_MAB";
BA_ "LongName" SG_ 658 REAS_SWO_MAB "Grund_Abschaltung_Fernlicht";
BA_ "SysSignalName" SG_ 658 REAS_SWO_MAB "REAS_SWO_MAB";
BA_ "CompuMethodName" SG_ 658 REAS_SWO_MAB_2 "REAS_SWO_MAB_2";
BA_ "ISignalName" SG_ 658 REAS_SWO_MAB_2 "REAS_SWO_MAB_2";
BA_ "LongName" SG_ 658 REAS_SWO_MAB_2 "Grund_Abschaltung_Fernlicht_2";
BA_ "SysSignalName" SG_ 658 REAS_SWO_MAB_2 "REAS_SWO_MAB_2";
BA_ "CompuMethodName" SG_ 658 MAB_DIM_1 "MAB_DIM";
BA_ "ISignalName" SG_ 658 MAB_DIM_1 "MAB_DIM_1";
BA_ "LongName" SG_ 658 MAB_DIM_1 "Fernlicht_Dimmung_1";
BA_ "SysSignalName" SG_ 658 MAB_DIM_1 "MAB_DIM_1";
BA_ "CompuMethodName" SG_ 658 MAB_DIM_2 "MAB_DIM";
BA_ "ISignalName" SG_ 658 MAB_DIM_2 "MAB_DIM_2";
BA_ "LongName" SG_ 658 MAB_DIM_2 "Fernlicht_Dimmung_2";
BA_ "SysSignalName" SG_ 658 MAB_DIM_2 "MAB_DIM_2";
BA_ "CompuMethodName" SG_ 658 MAB_DIM_3 "MAB_DIM";
BA_ "ISignalName" SG_ 658 MAB_DIM_3 "MAB_DIM_3";
BA_ "LongName" SG_ 658 MAB_DIM_3 "Fernlicht_Dimmung_3";
BA_ "SysSignalName" SG_ 658 MAB_DIM_3 "MAB_DIM_3";
BA_ "CompuMethodName" SG_ 658 MAB_DIM_4 "MAB_DIM";
BA_ "ISignalName" SG_ 658 MAB_DIM_4 "MAB_DIM_4";
BA_ "LongName" SG_ 658 MAB_DIM_4 "Fernlicht_Dimmung_4";
BA_ "SysSignalName" SG_ 658 MAB_DIM_4 "MAB_DIM_4";
BA_ "CompuMethodName" SG_ 658 MAB_DIM_5 "MAB_DIM";
BA_ "ISignalName" SG_ 658 MAB_DIM_5 "MAB_DIM_5";
BA_ "LongName" SG_ 658 MAB_DIM_5 "Fernlicht_Dimmung_5";
BA_ "SysSignalName" SG_ 658 MAB_DIM_5 "MAB_DIM_5";
BA_ "CompuMethodName" SG_ 658 QU_FN_DIM "QU_FN_DIM";
BA_ "ISignalName" SG_ 658 QU_FN_DIM "QU_FN_DIM";
BA_ "LongName" SG_ 658 QU_FN_DIM "Qualifier_Funktion_Dimmung";
BA_ "SysSignalName" SG_ 658 QU_FN_DIM "QU_FN_DIM";
BA_ "CompuMethodName" SG_ 658 HighBeamAssistEnabled "HighBeamAssistEnabled";
BA_ "ISignalName" SG_ 658 HighBeamAssistEnabled "HighBeamAssistEnabled";
BA_ "LongName" SG_ 658 HighBeamAssistEnabled "HighBeamAssistEnabled";
BA_ "SysSignalName" SG_ 658 HighBeamAssistEnabled "HighBeamAssistEnabled";
BA_ "CompuMethodName" SG_ 899 CTR_AW_SU "CTR_AW_SU";
BA_ "ISignalName" SG_ 899 CTR_AW_SU "CTR_AW_SU";
BA_ "LongName" SG_ 899 CTR_AW_SU "Steuerung_Allrad_Konfiguration";
BA_ "SysSignalName" SG_ 899 CTR_AW_SU "CTR_AW_SU";
BA_ "CompuMethodName" SG_ 899 ControlMModeSetup "ControlMModeSetup";
BA_ "ISignalName" SG_ 899 ControlMModeSetup "ControlMModeSetup";
BA_ "LongName" SG_ 899 ControlMModeSetup "ControlMModeSetup";
BA_ "SysSignalName" SG_ 899 ControlMModeSetup "ControlMModeSetup";
BA_ "CompuMethodName" SG_ 899 CTR_EPS_SU "CTR_EPS_SU";
BA_ "ISignalName" SG_ 899 CTR_EPS_SU "CTR_EPS_SU";
BA_ "LongName" SG_ 899 CTR_EPS_SU "Steuerung_EPS_Konfiguration";
BA_ "SysSignalName" SG_ 899 CTR_EPS_SU "CTR_EPS_SU";
BA_ "CompuMethodName" SG_ 899 CTR_VDC_SU "CTR_VDC_SU";
BA_ "ISignalName" SG_ 899 CTR_VDC_SU "CTR_VDC_SU";
BA_ "LongName" SG_ 899 CTR_VDC_SU "Steuerung_VDC_Konfiguration";
BA_ "SysSignalName" SG_ 899 CTR_VDC_SU "CTR_VDC_SU";
BA_ "CompuMethodName" SG_ 899 CTR_ENG_SU "CTR_ENG_SU";
BA_ "ISignalName" SG_ 899 CTR_ENG_SU "CTR_ENG_SU";
BA_ "LongName" SG_ 899 CTR_ENG_SU "Steuerung_Motor_Konfiguration";
BA_ "SysSignalName" SG_ 899 CTR_ENG_SU "CTR_ENG_SU";
BA_ "CompuMethodName" SG_ 899 CTR_ASR_SU "CTR_ASR_SU";
BA_ "ISignalName" SG_ 899 CTR_ASR_SU "CTR_ASR_SU";
BA_ "LongName" SG_ 899 CTR_ASR_SU "control_ASR_setup";
BA_ "SysSignalName" SG_ 899 CTR_ASR_SU "CTR_ASR_SU";
BA_ "CompuMethodName" SG_ 899 CTR_DRVGMOD_INQY "CTR_DRVGMOD_INQY";
BA_ "ISignalName" SG_ 899 CTR_DRVGMOD_INQY "CTR_DRVGMOD_INQY";
BA_ "LongName" SG_ 899 CTR_DRVGMOD_INQY "Steuerung_Fahrmodus_Anfrage";
BA_ "SysSignalName" SG_ 899 CTR_DRVGMOD_INQY "CTR_DRVGMOD_INQY";
BA_ "CompuMethodName" SG_ 899 CTR_BRPD_SU "CTR_BRPD_SU";
BA_ "ISignalName" SG_ 899 CTR_BRPD_SU "CTR_BRPD_SU";
BA_ "LongName" SG_ 899 CTR_BRPD_SU "Steuerung_Bremspedal_Konfiguration";
BA_ "SysSignalName" SG_ 899 CTR_BRPD_SU "CTR_BRPD_SU";
BA_ "CompuMethodName" SG_ 899 ControlDriftSupportLevelSetup "StatusDriftLevel";
BA_ "ISignalName" SG_ 899 ControlDriftSupportLevelSetup "ControlDriftSupportLevelSetup";
BA_ "LongName" SG_ 899 ControlDriftSupportLevelSetup "ControlDriftSupportLevelSetup";
BA_ "SysSignalName" SG_ 899 ControlDriftSupportLevelSetup "ControlDriftSupportLevelSetup";
BA_ "CompuMethodName" SG_ 899 ControlDriftMControlPlusTraction "StatusTractionLevel";
BA_ "ISignalName" SG_ 899 ControlDriftMControlPlusTraction "ControlDriftMControlPlusTractionLevelSetup";
BA_ "LongName" SG_ 899 ControlDriftMControlPlusTraction "ControlDriftMControlPlusTractionLevelSetup";
BA_ "SysSignalName" SG_ 899 ControlDriftMControlPlusTraction "ControlDriftMControlPlusTractionLevelSetup";
BA_ "SystemSignalLongSymbol" SG_ 899 ControlDriftMControlPlusTraction "ControlDriftMControlPlusTractionLevelSetup";
BA_ "CompuMethodName" SG_ 899 ControlDriftMControlPlusBrakeBal "StatusBalanceLevel";
BA_ "ISignalName" SG_ 899 ControlDriftMControlPlusBrakeBal "ControlDriftMControlPlusBrakeBalanceLevelSetup";
BA_ "LongName" SG_ 899 ControlDriftMControlPlusBrakeBal "ControlDriftMControlPlusBrakeBalanceLevelSetup";
BA_ "SysSignalName" SG_ 899 ControlDriftMControlPlusBrakeBal "ControlDriftMControlPlusBrakeBalanceLevelSetup";
BA_ "SystemSignalLongSymbol" SG_ 899 ControlDriftMControlPlusBrakeBal "ControlDriftMControlPlusBrakeBalanceLevelSetup";
BA_ "CompuMethodName" SG_ 899 ControlDriftSetup "ControlDriftSetup";
BA_ "ISignalName" SG_ 899 ControlDriftSetup "ControlDriftSetup";
BA_ "LongName" SG_ 899 ControlDriftSetup "ControlDriftSetup";
BA_ "SysSignalName" SG_ 899 ControlDriftSetup "ControlDriftSetup";
BA_ "CompuMethodName" SG_ 899 ControlDriftReset "ControlDriftReset";
BA_ "ISignalName" SG_ 899 ControlDriftReset "ControlDriftReset";
BA_ "LongName" SG_ 899 ControlDriftReset "ControlDriftReset";
BA_ "SysSignalName" SG_ 899 ControlDriftReset "ControlDriftReset";
BA_ "CompuMethodName" SG_ 899 ControlDriftRecording "ControlDriftRecording";
BA_ "ISignalName" SG_ 899 ControlDriftRecording "ControlDriftRecording";
BA_ "LongName" SG_ 899 ControlDriftRecording "ControlDriftRecording";
BA_ "SysSignalName" SG_ 899 ControlDriftRecording "ControlDriftRecording";
BA_ "CompuMethodName" SG_ 640 RQ_BST_RPM_IDLG_SFYC "RQ_BST_RPM_IDLG_SFYC";
BA_ "ISignalName" SG_ 640 RQ_BST_RPM_IDLG_SFYC "RQ_BST_RPM_IDLG_SFYC";
BA_ "LongName" SG_ 640 RQ_BST_RPM_IDLG_SFYC "Anforderung_Erhöhung_Drehzahl_Leerlauf_Sicherheitsfahrzeug";
BA_ "SysSignalName" SG_ 640 RQ_BST_RPM_IDLG_SFYC "RQ_BST_RPM_IDLG_SFYC";
BA_ "CompuMethodName" SG_ 223 CTR_DISP_SHLI_SEG "CTR_MDRV_2_SHLI_SEG";
BA_ "ISignalName" SG_ 223 CTR_DISP_SHLI_SEG "CTR_DISP_SHLI_SEG";
BA_ "LongName" SG_ 223 CTR_DISP_SHLI_SEG "Steuerung_Anzeige_Shiftlights_Segment";
BA_ "SysSignalName" SG_ 223 CTR_DISP_SHLI_SEG "CTR_DISP_SHLI_SEG";
BA_ "CompuMethodName" SG_ 223 CTR_DISP_SHLI_FLS "CTR_MDRV_2_SHLI_FLS";
BA_ "ISignalName" SG_ 223 CTR_DISP_SHLI_FLS "CTR_DISP_SHLI_FLS";
BA_ "LongName" SG_ 223 CTR_DISP_SHLI_FLS "Steuerung_Anzeige_Shiftlights_blinkend";
BA_ "SysSignalName" SG_ 223 CTR_DISP_SHLI_FLS "CTR_DISP_SHLI_FLS";
BA_ "CompuMethodName" SG_ 901 OptionSpeedLimitChangeWarning "OptionSpeedLimitWarningSecondLevel";
BA_ "ISignalName" SG_ 901 OptionSpeedLimitChangeWarning "OptionSpeedLimitChangeWarning";
BA_ "LongName" SG_ 901 OptionSpeedLimitChangeWarning "OptionSpeedLimitChangeWarning";
BA_ "SysSignalName" SG_ 901 OptionSpeedLimitChangeWarning "OptionSpeedLimitChangeWarning";
BA_ "CompuMethodName" SG_ 901 OPTN_SLI_OFFS "OPTN_SLI_OFFS";
BA_ "GenSigStartValue" SG_ 901 OPTN_SLI_OFFS 30;
BA_ "ISignalName" SG_ 901 OPTN_SLI_OFFS "OPTN_SLI_OFFS";
BA_ "LongName" SG_ 901 OPTN_SLI_OFFS "Option_SLI_Offset";
BA_ "SysSignalName" SG_ 901 OPTN_SLI_OFFS "OPTN_SLI_OFFS";
BA_ "CompuMethodName" SG_ 901 OPTN_SLI_DISP "OPTN_SLI_DISP";
BA_ "ISignalName" SG_ 901 OPTN_SLI_DISP "OPTN_SLI_DISP";
BA_ "LongName" SG_ 901 OPTN_SLI_DISP "Option_SLI_Anzeige";
BA_ "SysSignalName" SG_ 901 OPTN_SLI_DISP "OPTN_SLI_DISP";
BA_ "CompuMethodName" SG_ 901 OPTN_SLI_WARN "OPTN_SLI_WARN";
BA_ "ISignalName" SG_ 901 OPTN_SLI_WARN "OPTN_SLI_WARN";
BA_ "LongName" SG_ 901 OPTN_SLI_WARN "Option_SLI_Warnung";
BA_ "SysSignalName" SG_ 901 OPTN_SLI_WARN "OPTN_SLI_WARN";
BA_ "CompuMethodName" SG_ 901 OPTN_SLI_STAG "OPTN_SLI_STAG";
BA_ "ISignalName" SG_ 901 OPTN_SLI_STAG "OPTN_SLI_STAG";
BA_ "LongName" SG_ 901 OPTN_SLI_STAG "Option_SLI_Inszenierung";
BA_ "SysSignalName" SG_ 901 OPTN_SLI_STAG "OPTN_SLI_STAG";
BA_ "CompuMethodName" SG_ 901 OPTN_OFFS_SLOW "OPTN_OFFS_SLOW";
BA_ "ISignalName" SG_ 901 OPTN_OFFS_SLOW "OPTN_OFFS_SLOW";
BA_ "LongName" SG_ 901 OPTN_OFFS_SLOW "Option_Offset_Langsam";
BA_ "SysSignalName" SG_ 901 OPTN_OFFS_SLOW "OPTN_OFFS_SLOW";
BA_ "CompuMethodName" SG_ 901 OPTN_SLI_OFFS_SLOW "OFFS_V_SLOW";
BA_ "GenSigStartValue" SG_ 901 OPTN_SLI_OFFS_SLOW 30;
BA_ "ISignalName" SG_ 901 OPTN_SLI_OFFS_SLOW "OPTN_SLI_OFFS_SLOW";
BA_ "LongName" SG_ 901 OPTN_SLI_OFFS_SLOW "Option_SLI_Offset_Langsam";
BA_ "SysSignalName" SG_ 901 OPTN_SLI_OFFS_SLOW "OPTN_SLI_OFFS_SLOW";
BA_ "CompuMethodName" SG_ 901 OptionSpeedLimitWarningSecondLev "OptionSpeedLimitWarningSecondLevel";
BA_ "ISignalName" SG_ 901 OptionSpeedLimitWarningSecondLev "OptionSpeedLimitWarningSecondLevel";
BA_ "LongName" SG_ 901 OptionSpeedLimitWarningSecondLev "OptionSpeedLimitWarningSecondLevel";
BA_ "SysSignalName" SG_ 901 OptionSpeedLimitWarningSecondLev "OptionSpeedLimitWarningSecondLevel";
BA_ "SystemSignalLongSymbol" SG_ 901 OptionSpeedLimitWarningSecondLev "OptionSpeedLimitWarningSecondLevel";

VAL_ 999 CTR_ACTVN_CARS 0 "CarSharing_Mode_nicht_gesetzt" 1 "CarSharing_Mode_gesetzt" 253 "SIGNALTAG_FCTIF_NOT_AVAILABLE" 254 "SIGNALTAG_FCT_ERROR" 255 "Sendefunktion nicht in Betrieb";
VAL_ 999 CTR_FBD_CARS 0 "Empfang_THS_aktivieren" 1 "Empfang_THS_deaktivieren" 253 "SIGNALTAG_FCTIF_NOT_AVAILABLE" 254 "SIGNALTAG_FCT_ERROR" 255 "Sendefunktion nicht in Betrieb";
VAL_ 999 CTR_PRSL_PROFIL_CARS 0 "Das Profil 1 (Flottenprofil) mit der Id 0 wird aktiviert." 1 "Das Profil 2 (Kundenprofil 1) mit der Id 1 wird aktiviert." 2 "Das Profil 3 (Kundenprofil 2) mit der Id 2 wird aktiviert." 253 "SIGNALTAG_FCTIF_NOT_AVAILABLE" 254 "SIGNALTAG_FCT_ERROR" 255 "Sendefunktion nicht in Betrieb";
VAL_ 192 ALIV_COU_ZGM 15 "Signal ungültig";
VAL_ 192 INFO_BUS_ZGM 0 "AE_CAN_FD_ab_SP2021" 1 "AP_CAN_FD_ab_SP2021" 2 "Body2_CAN_bis_SP2018" 3 "Body_CAN_ab_SP2021" 4 "FAS_CAN_bis_SP2018_oder_Body2_CAN_ab_SP2021" 5 "Body3_CAN_ab_SP2021" 7 "FAS_CAN_FD_ab_SP2021" 8 "AE_CAN_FD_bis_SP2018_oder_Infra_CAN_ab_SP2021" 9 "IuK_CAN_ab_SP2021" 10 "USS_CAN_FD_ab_SP2021" 32 "IuK_CAN_bis_SP2018" 64 "FA_CAN_bis_SP2018" 128 "Body_CAN_bis_SP2018" 255 "Sendefunktion nicht in Betrieb";
VAL_ 217 ST_ECU_ANG_ACPD 0 "Zustand Initialisierung" 1 "Zustand Normalbetrieb" 2 "Zustand Normalbetrieb/Überspannung sensiert" 3 "Zustand Normalbetrieb/Unterspannung sensiert" 4 "Zustand Diagnose" 5 "Zustand Diagnose/Überspannung sensiert" 6 "Zustand Diagnose/Unterspannung sensiert" 7 "Zustand Powerdown" 8 "Zustand PowerSave" 9 "Zustand Nicht verfügbar" 10 "Zustand Reset" 11 "Zustand Reserviert 11" 12 "Zustand Reserviert 12" 13 "Zustand Reserviert 13" 14 "Zustand Reserviert 14" 15 "Signal ungültig";
VAL_ 217 QU_AVL_ANG_ACPD 1 "Normalzustand" 2 "reserviert" 3 "reserviert" 4 "reserviert" 6 "Fehlerfall" 7 "reserviert" 8 "Initialisierung" 9 "reserviert" 10 "reserviert" 11 "reserviert" 12 "Signalwert nicht ermittelbar. Abgleichwert wird versandt." 14 "reserviert" 15 "Darf ausschließlich durch ein Gateway gesetzt werden";
VAL_ 217 ST_INTF_DRASY 0 "Keine Fahrpedal-(Fahrer-) anforderung, keine FAS-Anforderung" 1 "Fahrpedal-(Fahrer-) anforderung, keine FAS-Anforderung" 2 "Keine Fahrpedal-(Fahrer-) anforderung, FAS-Anforderung" 3 "Fahrpedal-(Fahrer-) anforderung größer FAS-Anforderung" 7 "Fahrpedal-(Fahrer-) anforderung kleiner FAS-Anforderung" 8 "Initialisierung" 15 "Signal ungültig";
VAL_ 217 ECO_ANG_ACPD 0 "Lastanforderung im effizienten Antriebsbereich" 1 "Lastanforderung außerhalb des effizienten Antriebsbereichs" 3 "Signal ungültig";
VAL_ 870 ST_UN_TEMP_KI 0 "°C" 1 "°F" 2 "Keine Angabe" 3 "Signal ungültig";
VAL_ 870 DISP_RNG_ECO 4093 "Es werden Striche angezeigt" 4094 "Keine Angabe" 4095 "Signal ungültig";
VAL_ 870 DISP_RNG_ECO_WON 4093 "Es werden Striche angezeigt" 4094 "Keine Angabe" 4095 "Signal ungültig";
VAL_ 854 DISP_RNG_MAX 4093 "Es werden Striche angezeigt" 4094 "keine Angabe" 4095 "Signal ungültig";
VAL_ 854 DISP_RNG_EVEH 4093 "Es werden Striche angezeigt" 4094 "keine Angabe" 4095 "Signal ungültig";
VAL_ 854 COSP_AVR_EVEH_BC_1 4093 "Es werden Striche angezeigt." 4094 "Keine Angabe" 4095 "Signal ungültig";
VAL_ 854 COSP_AVR_EVEH_BC_2 4093 "Es werden Striche angezeigt." 4094 "Keine Angabe" 4095 "Signal ungültig";
VAL_ 854 UN_COSP_EVEH_BC 1 "Verbrauch in kWh / 100km" 2 "Verbrauch in mi / kWh" 3 "Verbrauch in km / kWh" 4 "Verbrauch in Wh / km" 5 "Verbrauch in Wh / mi" 7 "Signal ungültig";
VAL_ 239 QU_AVL_BRTORQ_SUM 1 "Normalzustand, Bereitstellung unabhängig vom Reglerzustand" 2 "reserviert" 3 "reserviert" 4 "reserviert" 6 "Fehler, keine Signalberechnung möglich. Nutzsignal wird permanent mit der Ungültigkeitskennung befüllt." 7 "reserviert" 8 "Beim SG-Aufstart bis Istwert verfügbar (Vorbefüllung). Nutzsignal wird permanent mit der Ungültigkeitskennung befüllt." 9 "reserviert" 10 "reserviert" 11 "reserviert" 12 "reserviert" 14 "reserviert" 15 "Nutzung nur vom Gateway, nicht seitens Sender-SG";
VAL_ 239 QU_AVL_BRTORQ_SUM_DVCH 1 "reserviert" 2 "Normalzustand, Bereitstellung unabhängig von Reglerzustand" 3 "reserviert" 4 "nach Init während Verwendung z.B. Default-cp (qualitative Bewertung, keine quantitative)" 6 "Fehler, keine Signalberechnung möglich. Nutzsignal wird permanent mit der Ungültigkeitskennung befüllt." 7 "reserviert" 8 "Beim SG-Aufstart bis Istwert verfügbar (Vorbefüllung). Nutzsignal wird permanent mit der Ungültigkeitskennung befüllt." 9 "reserviert" 10 "reserviert" 11 "reserviert" 12 "z.B. aufgrund des Pumpentests ist eine Plausibilsierung des Nutzsignals nicht möglich. (Umrechnung des Vordrucks in Wert mit Defaultwert im Auftstartvorgang), maximal 3 Zyklen" 14 "reserviert" 15 "Nutzung nur vom Gateway, nicht seitens Sender-SG";
VAL_ 239 AVL_BRTORQ_SUM_DVCH_RAW 253 "SIGNALTAG_FCTIF_NOT_AVAILABLE" 254 "SIGNALTAG_FCT_ERROR" 255 "Sendefunktion nicht in Betrieb";
VAL_ 264 AVL_OPMO_CHGE 1 "Standby" 2 "DC-HV-Laden" 3 "Derating" 4 "Ladeunterbrechung" 5 "Error" 6 "Crash" 7 "Betriebsartwechsel" 8 "Ladeinitialisierung" 9 "Ladeinitialisierung abgeschlossen" 13 "SIGNALTAG_FCTIF_NOT_AVAILABLE" 14 "SIGNALTAG_FCT_ERROR" 15 "Sendefunktion nicht in Betrieb";
VAL_ 769 CTR_HOFF_RCOG_VEHGD 0 "Der Funktionsmaster fordert einen Zustandswechsel des HOD in den Sleepmode an. Mögliche Gründe Fehler oder Energiesparen" 1 "Der Funktionsmaster gibt HOD bekannt, dass der Sensorwert nicht benötigt wird." 2 "Der Funktionsmaster fordert einen Zustandswechsel des HOD in den Normalmode an." 3 "Der Wert ungültig wird nur vom Gateway gesetzt.";
VAL_ 763 RQ_MOD_DXP 0 "Keine_Anforderung_Fahrerlebnis_Modus" 1 "Anforderung_Modus_Sport_Welt" 2 "Anforderung_Modus_Hybrid_Welt" 3 "Anforderung_Modus_Electric_Welt" 4 "Anforderung_Modus_Adpative" 5 "Anforderung_Modus_BatteryControl" 61 "Hinweis: Reserviert für Funktionale Kennung Signal-Tags" 62 "Hinweis: Reserviert für Funktionale Kennung Signal-Tags" 63 "Sendefunktion nicht in Betrieb";
VAL_ 763 SU_ILK_MOD_DXP 0 "Modus_BatteryControl_nicht_verfuegbar" 1 "Modus_Sport_Welt_verfuegbar" 2 "Modus_Hybrid_Welt_verfuegbar" 4 "Modus_Electric_Welt_verfuegbar" 8 "Modus_Adaptive_verfuegbar" 16 "Modus_BatteryControl_verfuegbar" 253 "Hinweis: Reserviert für Funktionale Kennung Signal-Tags" 254 "Hinweis: Reserviert für Funktionale Kennung Signal-Tags" 255 "Sendefunktion nicht in Betrieb";
VAL_ 470 OP_PUBU_TEL_STW 0 "Keine Aktion" 1 "Taster TEL gedrückt" 2 "Reserviert" 3 "Signal ungültig";
VAL_ 470 OP_PUBU_AUD_AVOL_STW 0 "Keine Aktion / Keine Betätigung" 1 "Lautstärke leiser" 2 "Lautstärke lauter" 3 "Signal ungültig";
VAL_ 470 OP_PUBU_SKP_STW 0 "Keine_Aktion" 1 "Suchlauf_abwaerts_Menue_Skip_links" 2 "Suchlauf_aufwaerts_Menue_Skip_rechts" 3 "Fehler, auch wenn beide Tasten gedrückt sind";
VAL_ 470 OP_PUBU_PTT_STW 0 "Keine Aktion" 1 "PTT-Taster gedrückt" 2 "Ab SP2021 verfuegbar." 3 "Signal ungültig";
VAL_ 470 OP_PUBU_HORN 0 "Keine Aktion" 1 "HORN-Taster gedrückt" 3 "Signal ungültig";
VAL_ 470 OP_PUBU_SPFN 0 "Keine Aktion" 1 "Taster gedrückt" 3 "Signal ungültig";
VAL_ 470 OP_PUBU_SPFN_2 0 "Keine Aktion" 1 "Taster gedrückt" 3 "Signal ungültig";
VAL_ 696 OP_LIM 0 "Limit ausschalten" 1 "Limit einschalten" 2 "Keine Aktion" 3 "Signal ungültig";
VAL_ 696 OP_LIM_SPEC 4093 "Limit = Aktuelle Tachoanzeige" 4094 "Keine Änderung" 4095 "Signal ungültig";
VAL_ 494 ST_PUBU_MAB_ASST 0 "Keine Betätigung" 1 "Taster gedrückt" 3 "Signal ungültig";
VAL_ 540 OP_IM_NIVI 1 "Night-Vision-Bild AUS" 2 "Night-Vision-Bild EIN" 3 "Signal ungültig";
VAL_ 540 OP_DISP_MNT_NIVI 0 "Configuration with signals OP_OBJ_DETE_NIVI, OP_BRIG_OFFS_NIVI or OP_CONTR_NIVI" 1 "OP_IM_NIVI-Request from HU to NiVi" 2 "OP_IM_NIVI-Acknowledge from HU to NiVi" 3 "Signal ungültig";
VAL_ 540 OP_CONTR_NIVI 255 "Signal ungültig";
VAL_ 540 OP_OBJ_DETE_NIVI 0 "Objekterkennung nicht aktivierbar" 1 "Objekterkennung AUS" 2 "Objekterkennung EIN" 3 "Signal ungültig";
VAL_ 926 OP_HR 254 "Keine Änderung" 255 "Signal ungültig";
VAL_ 926 OP_MN 254 "Keine Änderung" 255 "Signal ungültig";
VAL_ 926 OP_SEC 254 "Keine Änderung" 255 "Signal ungültig";
VAL_ 926 OP_DATE_DAY 254 "Keine Änderung" 255 "Signal ungültig";
VAL_ 926 OP_DATE_MON 14 "Keine Änderung" 15 "Signal ungültig";
VAL_ 926 OP_DATE_YR 65534 "Keine Änderung" 65535 "Signal ungültig";
VAL_ 926 OP_DISP_CTI_DATE 0 "UTC-Zeit" 1 "Sommerzeit" 2 "Manuell gestellte Zeit" 15 "Signal ungültig";
VAL_ 678 OP_WISW 0 "Keine Aktion" 1 "Wird beim Aktivieren des Regensensors gesendet" 2 "Stufe 1" 3 "Stufe 2" 8 "Tippwischen" 16 "Frontwaschen" 64 "Heckwischen" 128 "Heckwaschen" 255 "Signal ungültig";
VAL_ 678 OP_WIPO 0 "Stufe 1" 1 "Stufe 2" 2 "Stufe 3" 4 "Stufe 4" 7 "Signal ungültig";
VAL_ 678 ALIV_WISW 15 "Signal ungültig";
VAL_ 502 CCLK_IDC 0 "beide Blinker AUS" 1 "Initialisierung auf Blinkperiodendauer von 640 ms (Richtungsblinken / Warnblinken)" 2 "Initialisierung auf halbe Blinkperiodendauer von 320 ms, trotz Sendezykluszeit von 640 ms (Richtungsblinken bei mindestens einer defekten Blinkleuchte)" 3 "Initialisierung auf Blinkperiodendauer von 840 ms (Reversierblinken bzw. Vorhalt eines Warnblinkens im Doppel-Blink-Impuls-Takt)" 15 "Signal ungültig";
VAL_ 502 ST_IDC 0 "Beide Blinker AUS" 1 "Blinker links EIN" 2 "Blinker rechts EIN" 3 "Beide Blinker EIN" 7 "Signal ungültig";
VAL_ 502 ST_IDC_STOP 0 "Zeitdifferenz zur letzten Botschaft nicht zum Synchronisieren verwenden sowie diese Botschaft nicht für folgende Zeitdifferenzmessung verwenden" 1 "Zeitdifferenz zwischen zwei Botschaften mit dieser Signalkodierung zur Synchronisierung verwenden" 2 "Neuen Blinktakt entsprechend Signal Takt_Blinken starten, kennzeichnet erste Flanke beim Einschalten einer Blinkfunktion oder beim Umschalten in der Low-Zeit (wird nicht versendet beim Umschalten in der High-Zeit unter Beibehaltung des bisherigen Taktes)" 3 "Signal ungültig";
VAL_ 502 ST_IDC_KI 0 "Blinkerkontroll-Lampen im Kombi signalisieren Blinkzyklus" 1 "verdecktes Blinken z. B. bei Taxialarm" 3 "Signal ungültig";
VAL_ 502 ST_IDC_TYP 0 "Init" 1 "Es ist kein Dauer-Richtungsblinken angefordert" 2 "Es ist Dauer-Richtungsblinken angefordert" 3 "Signal ungültig";
VAL_ 946 BS_SU_KI_BC 0 "Keine_Anzeige" 1 "Anzeige_Checkbox_Navigation_Ankunftszeit_und_Entfernung_zum_Ziel" 2 "Anzeige_Checkbox_Reichweite_Verbrenner" 4 "Anzeige_Checkbox_Gesamt_Reichweite" 8 "Vorhalt BEV" 16 "Anzeige_Checkbox_Reichweite_elektrisch_und_Reichweite_Verbrenner" 32 "Anzeige_Checkbox_Reichweitenpotential" 64 "Anzeige_Checkbox_Momentanverbrauch_Verbrenner_und_Durchschnittsverbrauch_Verbrenner" 128 "Anzeige_Checkbox_KVA_EVA_eDrive_abhaengig" 256 "Anzeige_Checkbox_Durchschnittsgeschwindigkeit_und_Durchschnittsverbrauch" 512 "Anzeige_Checkbox_Motortemperatur" 1024 "Anzeige_Checkbox_Efficient_Dynamics_Anzeige" 2048 "Anzeige M-GmbH M-Panel" 131072 "Anzeige_Checkbox_State_of_Charge_SOC" 1048576 "Anzeige_Checkbox_Kompass" 2097152 "Anzeige_Checkbox_eCounter_und_Durchschnittsverbrauch_Verbrenner" 4194304 "Anzeige_Checkbox_Lifetime_Durchschnitts_und_digitaler_Momentanverbrauch" 1073741824 "Keine_Aenderung" 4294967295 "Sendefunktion nicht in Betrieb";
VAL_ 946 BS_SU_KI_CONT 0 "Keine_Anzeige" 1 "Anzeige_Checkbox_Fahrmodusansicht" 2 "Anzeige_Checkbox_Navigation_Streckenuebersicht" 4 "Anzeige_Checkbox_Zusatzschild_Verkehrszeichenerkennung" 8 "Anzeige_Checkbox_Tachozeigerband_fuer_Tempolimit" 16 "Anzeige_Checkbox_Lupen_Effekt_Tacho" 32 "Anzeige_Checkbox_SPA" 64 "Popup" 128 "Vorhalt" 256 "Anzeige_Checkbox_Analoge_Uhr" 512 "Anzeige_Checkbox_Shiftlights" 1024 "Anzeige_Checkbox_Navigation" 2048 "Anzeige_Checkbox_Verkehrszeichenerkennung" 4096 "Anzeige_Checkbox_M_Drive_Inszenierung" 16384 "Helligkeitsoffset_keine_Aenderung" 65535 "Sendefunktion nicht in Betrieb";
VAL_ 946 BS_SU_PRESL_KI 0 "Kein_Radiobutton_darstellen" 1 "Diesen Radiobutton in Auswahlliste darstellen" 2 "Diesen Radiobutton in Auswahlliste darstellen" 4 "Diesen Radiobutton in Auswahlliste darstellen" 255 "Sendefunktion nicht in Betrieb";
VAL_ 1012 BS_SU_PRESL_KI_2 0 "Kein_Radiobutton_darstellen" 1 "Diesen Radiobutton in Auswahlliste darstellen" 2 "Diesen Radiobutton in Auswahlliste darstellen" 4 "Diesen Radiobutton in Auswahlliste darstellen" 8 "Diesen Radiobutton in Auswahlliste darstellen" 255 "Sendefunktion nicht in Betrieb";
VAL_ 1012 DISP_SU_LNK_HU 0 "Keine_Anzeige" 1 "Anzeige_Link_Individual_konfigurieren" 2 "Anzeige_Link_Reitersystem" 4 "Anzeige_Link_Widget_Auswahl" 8 "Anzeige_Link_Benachrichtigungen" 16 "Anzeige_Link_Mpad_Auswahl" 255 "Sendefunktion nicht in Betrieb";
VAL_ 1012 BS_SU_NAVI_DISP_TYP 0 "Kein_Radiobutton_darstellen" 1 "Diesen Radiobutton in Auswahlliste darstellen" 2 "Diesen Radiobutton in Auswahlliste darstellen" 4 "Diesen Radiobutton in Auswahlliste darstellen" 15 "Sendefunktion nicht in Betrieb";
VAL_ 1012 BS_SU_ENTAI_ECU_DISP 0 "Kein_Radiobutton_darstellen" 1 "Diesen Radiobutton in Auswahlliste darstellen" 2 "Diesen Radiobutton in Auswahlliste darstellen" 15 "Sendefunktion nicht in Betrieb";
VAL_ 1012 BaseSetupDZMorPowermeterDisplay 0 "Kein_Radiobutton_darstellen" 1 "Diesen Radiobutton in Auswahlliste darstellen" 2 "Diesen Radiobutton in Auswahlliste darstellen" 15 "Sendefunktion nicht in Betrieb";
VAL_ 1195 CurrentConsumptionCombustion 65533 "SIGNALTAG_FCTIF_NOT_AVAILABLE" 65534 "SIGNALTAG_FCT_ERROR" 65535 "Sendefunktion nicht in Betrieb";
VAL_ 1195 CurrentConsumptionElectric 65533 "SIGNALTAG_FCTIF_NOT_AVAILABLE" 65534 "SIGNALTAG_FCT_ERROR" 65535 "Sendefunktion nicht in Betrieb";
VAL_ 1195 UnitCurrentConsumptionCombustion 0 "DEFAULT" 1 "CONSUMPTION_L_100KM" 2 "CONSUMPTION_MPG_UK" 3 "CONSUMPTION_MPG_US" 4 "CONSUMPTION_KM_L" 13 "SIGNALTAG_FCTIF_NOT_AVAILABLE" 14 "SIGNALTAG_FCT_ERROR" 15 "Sendefunktion nicht in Betrieb";
VAL_ 1195 UnitCurrentConsumptionElectric 0 "DEFAULT" 1 "CONSUMPTION_KWH_100KM" 2 "CONSUMPTION_MI_KWH" 3 "CONSUMPTION_KM_KWH" 4 "CONSUMPTION_WH_KM" 5 "CONSUMPTION_KWH_100MI" 6 "CONSUMPTION_KWH_100MI" 13 "SIGNALTAG_FCTIF_NOT_AVAILABLE" 14 "SIGNALTAG_FCT_ERROR" 15 "Sendefunktion nicht in Betrieb";
VAL_ 812 ST_DIST_DSTN_NAVI_UN 1 "Keine Änderung" 2 "Kilometer (Meter)" 3 "GB miles (yards)" 4 "US miles (feet)" 255 "Signal ungültig";
VAL_ 812 ST_ARRI_T_HR 255 "Signal ungültig";
VAL_ 812 ST_ARRI_T_MN 255 "Signal ungültig";
VAL_ 812 ST_T_AM_PM 0 "nicht verwendet" 1 "Am" 2 "Pm" 3 "Signal ungültig";
VAL_ 812 ST_DAY_FLAG 0 "nicht verwendet" 1 "Dauer ist 24h oder  länger" 2 "Dauer ist weniger 24h" 3 "Signal ungültig";
VAL_ 110 CCLK_COU_SYNCN_CAN_TYP 0 "CAN Synchronisations-Nachricht" 253 "SIGNALTAG_FCTIF_NOT_AVAILABLE" 254 "SIGNALTAG_FCT_ERROR" 255 "Sendefunktion nicht in Betrieb";
VAL_ 110 CCLK_COU_SYNCN_CAN_IDENT 65533 "SIGNALTAG_FCTIF_NOT_AVAILABLE" 65534 "SIGNALTAG_FCT_ERROR" 65535 "Sendefunktion nicht in Betrieb";
VAL_ 110 CCLK_COU_SYNCN_CAN_SEC 4294967293 "SIGNALTAG_FCTIF_NOT_AVAILABLE" 4294967294 "SIGNALTAG_FCT_ERROR" 4294967295 "Sendefunktion nicht in Betrieb";
VAL_ 111 CCLK_COU_SYNCN_TYP 8 "CAN Nachlauf Nachricht" 253 "SIGNALTAG_FCTIF_NOT_AVAILABLE" 254 "SIGNALTAG_FCT_ERROR" 255 "Sendefunktion nicht in Betrieb";
VAL_ 111 CCLK_COU_SYNCN_IDENT 65533 "SIGNALTAG_FCTIF_NOT_AVAILABLE" 65534 "SIGNALTAG_FCT_ERROR" 65535 "Sendefunktion nicht in Betrieb";
VAL_ 111 CCLK_COU_SYNCN_VL 4294967293 "SIGNALTAG_FCTIF_NOT_AVAILABLE" 4294967294 "SIGNALTAG_FCT_ERROR" 4294967295 "Sendefunktion nicht in Betrieb";
VAL_ 111 CCLK_COU_SYNCN_OVFL 0 "Kein Overflow" 1 "Overflow" 3 "Signal ungültig";
VAL_ 2161115410 CEMErrorEventDTC_DA12h 16777213 "SIGNALTAG_FCTIF_NOT_AVAILABLE" 16777214 "SIGNALTAG_FCT_ERROR" 16777215 "Sendefunktion nicht in Betrieb";
VAL_ 2161115410 CEMErrorEventTimeStampSec_DA12h 65533 "SIGNALTAG_FCTIF_NOT_AVAILABLE" 65534 "SIGNALTAG_FCT_ERROR" 65535 "Sendefunktion nicht in Betrieb";
VAL_ 2161115410 CEMErrorEventTimeStampMSec_DA12h 253 "SIGNALTAG_FCTIF_NOT_AVAILABLE" 254 "SIGNALTAG_FCT_ERROR" 255 "Sendefunktion nicht in Betrieb";
VAL_ 2161115410 CEMErrorEventSyncMethod_DA12h 253 "SIGNALTAG_FCTIF_NOT_AVAILABLE" 254 "SIGNALTAG_FCT_ERROR" 255 "Sendefunktion nicht in Betrieb";
VAL_ 2161115410 CEMErrorEventECUAddress_DA12h 253 "SIGNALTAG_FCTIF_NOT_AVAILABLE" 254 "SIGNALTAG_FCT_ERROR" 255 "Sendefunktion nicht in Betrieb";
VAL_ 2161115667 CEMErrorEventDTC_DA13h 16777213 "SIGNALTAG_FCTIF_NOT_AVAILABLE" 16777214 "SIGNALTAG_FCT_ERROR" 16777215 "Sendefunktion nicht in Betrieb";
VAL_ 2161115667 CEMErrorEventTimeStampSec_DA13h 65533 "SIGNALTAG_FCTIF_NOT_AVAILABLE" 65534 "SIGNALTAG_FCT_ERROR" 65535 "Sendefunktion nicht in Betrieb";
VAL_ 2161115667 CEMErrorEventTimeStampMSec_DA13h 253 "SIGNALTAG_FCTIF_NOT_AVAILABLE" 254 "SIGNALTAG_FCT_ERROR" 255 "Sendefunktion nicht in Betrieb";
VAL_ 2161115667 CEMErrorEventSyncMethod_DA13h 253 "SIGNALTAG_FCTIF_NOT_AVAILABLE" 254 "SIGNALTAG_FCT_ERROR" 255 "Sendefunktion nicht in Betrieb";
VAL_ 2161115667 CEMErrorEventECUAddress_DA13h 253 "SIGNALTAG_FCTIF_NOT_AVAILABLE" 254 "SIGNALTAG_FCT_ERROR" 255 "Sendefunktion nicht in Betrieb";
VAL_ 2161116184 CEMErrorEventDTC_DA18h 16777213 "SIGNALTAG_FCTIF_NOT_AVAILABLE" 16777214 "SIGNALTAG_FCT_ERROR" 16777215 "Sendefunktion nicht in Betrieb";
VAL_ 2161116184 CEMErrorEventTimeStampSec_DA18h 65533 "SIGNALTAG_FCTIF_NOT_AVAILABLE" 65534 "SIGNALTAG_FCT_ERROR" 65535 "Sendefunktion nicht in Betrieb";
VAL_ 2161116184 CEMErrorEventTimeStampMSec_DA18h 253 "SIGNALTAG_FCTIF_NOT_AVAILABLE" 254 "SIGNALTAG_FCT_ERROR" 255 "Sendefunktion nicht in Betrieb";
VAL_ 2161116184 CEMErrorEventSyncMethod_DA18h 253 "SIGNALTAG_FCTIF_NOT_AVAILABLE" 254 "SIGNALTAG_FCT_ERROR" 255 "Sendefunktion nicht in Betrieb";
VAL_ 2161116184 CEMErrorEventECUAddress_DA18h 253 "SIGNALTAG_FCTIF_NOT_AVAILABLE" 254 "SIGNALTAG_FCT_ERROR" 255 "Sendefunktion nicht in Betrieb";
VAL_ 2161116445 CEMErrorEventDTC_DA1Dh 16777213 "SIGNALTAG_FCTIF_NOT_AVAILABLE" 16777214 "SIGNALTAG_FCT_ERROR" 16777215 "Sendefunktion nicht in Betrieb";
VAL_ 2161116445 CEMErrorEventTimeStampSec_DA1Dh 65533 "SIGNALTAG_FCTIF_NOT_AVAILABLE" 65534 "SIGNALTAG_FCT_ERROR" 65535 "Sendefunktion nicht in Betrieb";
VAL_ 2161116445 CEMErrorEventTimeStampMSec_DA1Dh 253 "SIGNALTAG_FCTIF_NOT_AVAILABLE" 254 "SIGNALTAG_FCT_ERROR" 255 "Sendefunktion nicht in Betrieb";
VAL_ 2161116445 CEMErrorEventSyncMethod_DA1Dh 253 "SIGNALTAG_FCTIF_NOT_AVAILABLE" 254 "SIGNALTAG_FCT_ERROR" 255 "Sendefunktion nicht in Betrieb";
VAL_ 2161116445 CEMErrorEventECUAddress_DA1Dh 253 "SIGNALTAG_FCTIF_NOT_AVAILABLE" 254 "SIGNALTAG_FCT_ERROR" 255 "Sendefunktion nicht in Betrieb";
VAL_ 2161117269 CEMErrorEventDTC_DA55h 16777213 "SIGNALTAG_FCTIF_NOT_AVAILABLE" 16777214 "SIGNALTAG_FCT_ERROR" 16777215 "Sendefunktion nicht in Betrieb";
VAL_ 2161117269 CEMErrorEventTimeStampSec_DA55h 65533 "SIGNALTAG_FCTIF_NOT_AVAILABLE" 65534 "SIGNALTAG_FCT_ERROR" 65535 "Sendefunktion nicht in Betrieb";
VAL_ 2161117269 CEMErrorEventTimeStampMSec_DA55h 253 "SIGNALTAG_FCTIF_NOT_AVAILABLE" 254 "SIGNALTAG_FCT_ERROR" 255 "Sendefunktion nicht in Betrieb";
VAL_ 2161117269 CEMErrorEventSyncMethod_DA55h 253 "SIGNALTAG_FCTIF_NOT_AVAILABLE" 254 "SIGNALTAG_FCT_ERROR" 255 "Sendefunktion nicht in Betrieb";
VAL_ 2161117269 CEMErrorEventECUAddress_DA55h 253 "SIGNALTAG_FCTIF_NOT_AVAILABLE" 254 "SIGNALTAG_FCT_ERROR" 255 "Sendefunktion nicht in Betrieb";
VAL_ 1001 RQ_CHGRDI 0 "kein laden" 1 "Plug & Charge (default)" 2 "Laden mit Abfahrtszeit und Konditionierung";
VAL_ 1001 ST_CHGNG 0 "Kein Laden" 1 "Initialisierung" 2 "Laden aktiv" 3 "Ladepause" 4 "Laden beendet" 5 "Ladefehler" 15 "Signal ungültig";
VAL_ 1001 ST_CHGRDI 0 "Keine Ladebereitschaft" 1 "Ladebereitschaft" 3 "Signal ungültig";
VAL_ 762 DISP_RSTI_EOCHG 65533 "SIGNALTAG_FCTIF_NOT_AVAILABLE" 65534 "SIGNALTAG_FCT_ERROR" 65535 "Signal Tag - Signal ist unbefüllt";
VAL_ 762 DISP_CHGNG_T_HR 253 "SIGNALTAG_FCTIF_NOT_AVAILABLE" 254 "SIGNALTAG_FCT_ERROR" 255 "Sendefunktion nicht in Betrieb";
VAL_ 762 DISP_CHGNG_T_MN 253 "SIGNALTAG_FCTIF_NOT_AVAILABLE" 254 "SIGNALTAG_FCT_ERROR" 255 "Sendefunktion nicht in Betrieb";
VAL_ 762 CHGNG_STA_T_HR 253 "Hinweis: Reserviert für funktionale Kennung Signal-Tag" 254 "Hinweis: Reserviert für funktionale Kennung Signal-Tag" 255 "Sendefunktion nicht in Betrieb";
VAL_ 762 CHGNG_STA_T_MN 253 "Hinweis: Reserviert für funktionale Kennung Signal-Tag" 254 "Hinweis: Reserviert für funktionale Kennung Signal-Tag" 255 "Sendefunktion nicht in Betrieb";
VAL_ 762 TAR_OPMO_DISP_CHGNG_MOD 0 "Keine_Anzeige_von_Zeiten_bezueglich_Laden" 1 "AFZ_soll_angezeigt_werden_und_wird_erreicht" 2 "AFZ_soll_angezeigt_werden_und_wird_nicht_erreicht" 4 "AFZ_soll_nicht_angezeigt_werden" 8 "Ladedauer_soll_angezeigt_werden" 16 "Ladedauer_soll_nicht_angezeigt_werden" 253 "SIGNALTAG_FCTIF_NOT_AVAILABLE" 254 "SIGNALTAG_FCT_ERROR" 255 "Sendefunktion nicht in Betrieb";
VAL_ 876 ST_ECU_CODO_LIM_V 0 "Zustand_Initialisierung" 1 "Zustand_Normalbetrieb" 2 "Zustand_Normalbetrieb_Ueberspannung_sensiert" 3 "Zustand_Normalbetrieb_Unterspannung_sensiert" 4 "Zustand_Diagnose" 5 "Zustand_Diagnose_Ueberspannung_sensiert" 6 "Zustand_Diagnose_Unterspannung_sensiert" 7 "Zustand_Powerdown" 8 "Zustand_PowerSave" 9 "Zustand_Nicht_verfuegbar" 10 "Zustand_Reset" 13 "SIGNALTAG_FCTIF_NOT_AVAILABLE" 14 "SIGNALTAG_FCT_ERROR" 15 "Sendefunktion nicht in Betrieb";
VAL_ 876 QU_CODO_LIM_V 2 "Wenn Geschwindigkeitsbegrenzung vom CDM aktiviert ist." 7 "Geschwindigkeit größer als gültiger Bereich ( > 252 km/h [0xFCU9])." 8 "Zustand wird beim Aufstarten als Vorbefüllung geschickt." 14 "Wenn Geschwindigkeitsbegrenzung vom CDM nicht aktiviert ist." 15 "Zustand wird vom CDM gesetzt, wenn in der Software alle anderen Zustände als die im Signal definierten Zustände auftreten (zur Absicherung z.B. bei Bitkipper).";
VAL_ 851 ST_CODO_LOKG_DR 0 "Initialisierung" 3 "Sicherung Coach-Tür inaktiv" 6 "Sicherung Coach-Tür aktiv" 7 "Signal ungültig";
VAL_ 851 ST_CODO_LOKG_PS 0 "Initialisierung" 3 "Sicherung Coach-Tür inaktiv" 6 "Sicherung Coach-Tür aktiv" 7 "Signal ungültig";
VAL_ 851 RQ_LOKG_CODO 0 "Keine Anforderung" 1 "Anforderung" 2 "Signal unplausibel" 3 "Signal ungültig";
VAL_ 851 ST_DSW_CODO_LOKG_DR 0 "Türkontakt Coach-Tür Seite Fahrer geschlossen" 1 "Türkontakt Coach-Tür Seite Fahrer offen" 2 "Signal unplausibel" 3 "Signal ungültig";
VAL_ 851 ST_DSW_CODO_LOKG_PS 0 "Türkontakt Coach-Tür Seite Beifahrer geschlossen" 1 "Türkontakt Coach-Tür Seite Beifahrer offen" 2 "Signal unplausibel" 3 "Signal ungültig";
VAL_ 1071 SU_MDRV_2_DSC 0 "Keine Änderung" 1 "DSC AUS" 2 "DSC EIN" 3 "DSC MDM" 15 "Signal ungültig";
VAL_ 1071 SU_MDRV_2_IDX 0 "Konfiguration 1" 1 "Konfiguration 2" 3 "Keine_Konfiguration" 15 "Signal ungültig";
VAL_ 1071 SU_MDRV_2_STG_GRB 0 "Keine Änderung" 1 "Stufe 1" 2 "Stufe 2" 3 "Stufe 3" 4 "Stufe 4" 5 "Stufe 5" 6 "BN2000: NUR wenn DSC AUS" 15 "Signal ungültig";
VAL_ 1071 SU_MDRV_2_ENG 0 "Keine Änderung" 1 "Komfort" 2 "Sport" 3 "Sport Plus" 15 "Signal ungültig";
VAL_ 1071 SU_MDRV_2_EDC 0 "keine Änderung" 1 "Komfort" 2 "Sport" 3 "Sport Plus" 15 "Signal ungültig";
VAL_ 1071 SU_MDRV_2_EPAS 0 "keine Änderung" 1 "Komfort" 2 "Sport" 3 "Sport Plus" 15 "Signal ungültig";
VAL_ 1071 SU_MDRV_2_DISP_HUD 0 "Keine Änderung" 1 "M-spezifische Darstellung" 2 "AG-Darstellung" 3 "Gilt ab SP2015" 15 "Signal ungültig";
VAL_ 1071 SU_MDRV_2_DISP_SHLI 0 "Keine Änderung" 1 "Shiftlights AUS" 2 "Shiftlights EIN" 15 "Signal ungültig";
VAL_ 1071 SU_MDRV_2_MOD_GRB 0 "Keine Änderung" 1 "Automatic" 2 "Sequentiell" 7 "Signal ungültig";
VAL_ 1071 SU_MDRV_2_SRST 0 "Kein_Ruecksetzen" 1 "Neue M-Drive-Konfigurationsdaten übernehmen" 4 "Rücksetzen auf M-Drive_Defaultkonfiguration" 7 "Signal ungültig";
VAL_ 1071 SU_MDRV_2_AW 0 "Allradmodus 4WD Standard" 1 "Allradmodus 4WD Alternativ" 2 "Allradmodus 2WD" 3 "Allradmodus hat sich nicht verändert." 7 "Sendefunktion nicht in Betrieb";
VAL_ 775 CON_LVCH 0 "Kein_Niveauwechsel_moeglich" 1 "Niveauwechsel_nach_Normalniveau_moeglich" 2 "Niveauwechsel_nach_N1_moeglich" 4 "Niveauwechsel_nach_N2_moeglich" 8 "Niveauwechsel_nach_N3_moeglich" 16 "Niveauwechsel_nach_N4_moeglich" 253 "SIGNALTAG_FCTIF_NOT_AVAILABLE" 254 "SIGNALTAG_FCT_ERROR" 255 "Sendefunktion nicht in Betrieb";
VAL_ 775 REAS_PREV_LVCH 0 "Es liegt kein Regelverhinderer vor." 1 "Anhänger erkannt" 2 "Zuladung zu groß" 4 "Z.B. bei Radentlastungsfunktion, Achsverschränkung, Fahrzeugdynamik, Temperaturüberschreitung, Einschaltdauer" 8 "Geschwindigkeitsschwelle überschritten" 16 "Energiemenge nicht ausreichend" 32 "Tür offen" 1021 "SIGNALTAG_FCTIF_NOT_AVAILABLE" 1022 "SIGNALTAG_FCT_ERROR" 1023 "Sendefunktion nicht in Betrieb";
VAL_ 60 CTR_BS_PRTNT 0 "Keine Kommunikation" 1 "Kom_Parken_BN_niO" 2 "Kom_Parken_BN_iO" 3 "Kom_Standfunktionen_Kunde_nicht_im_FZG" 4 "reserviert" 5 "Kom_Wohnen" 6 "reserviert" 7 "Kom_Pruefen_Analyse_Diagnose" 8 "Kom_Fahrbereitschaft_herstellen" 9 "reserviert" 10 "Kom_Fahren" 11 "reserviert" 12 "Kom_Fahrbereitschaft_beenden" 13 "Hinweis: Reserviert für funktionale Kennung Signal-Tag." 14 "Hinweis: Reserviert für funktionale Kennung Signal-Tag." 15 "Signal_unbefuellt";
VAL_ 60 ST_CON_VEH 0 "reserviert" 1 "Parken_BN_niO" 2 "Parken_BN_iO" 3 "Standfunktionen_Kunde_nicht_im_FZG" 5 "Wohnen" 7 "Pruefen_Analyse_Diagnose" 8 "Fahrbereitschaft_herstellen" 10 "Fahren" 12 "Fahrbereitschaft_beenden" 13 "Hinweis: Reserviert für funktionale Kennung Signal-Tag." 14 "Hinweis: Reserviert für funktionale Kennung Signal-Tag." 15 "Signal_unbefuellt";
VAL_ 60 QU_ST_CON_VEH 2 "Signalwert gültig" 3 "Signalwert eingeschränkt gültig" 6 "Codierung wird nicht befüllt" 14 "Siehe Signalbeschreibung" 15 "Signal unbefüllt";
VAL_ 908 RLS_ACCM 0 "Keine Freigabe" 1 "Freigabe zum Betrieb des Klimakompressors" 3 "Signal ungültig";
VAL_ 908 RLS_PRECOND_PAIC 0 "Klimatisierung verboten" 1 "Klimatisierung erlaubt" 3 "Sendefunktion nicht in Betrieb";
VAL_ 871 QUAN_SER_BOS_DISP 15 "Signal ungültig";
VAL_ 871 NO_SER_BOS_DISP 15 "Signal ungültig";
VAL_ 871 VL_GAP_BOS_DISP -128 "wenn Einheit_Faktor_BOS_Anzeige = Fh  ist der Service nicht wegbasiert" -64 "und Einheit_Faktor_BOS_Anzeige = 7h";
VAL_ 871 YR_BOS_DISP 0 "Darstellung \"/----\"" 255 "wenn Monat_BOS_Anzeige = Fh ist der Service nicht zeitbasiert";
VAL_ 871 MON_BOS_DISP 0 "Darstellung \"--/\"" 15 "wenn Jahr_BOS_Anzeige = FFh, ist der Service nicht zeitbasiert.";
VAL_ 700 CTR_CHGP_LOK_CSM 0 "Keine Aktion" 1 "Diese Codierung wird ab SP2015 nicht verwendet" 2 "Ladestecker entriegeln" 3 "Signal ungültig";
VAL_ 524 CTR_SLCTN_RMV 1 "Reset_all" 3 "Sendefunktion nicht in Betrieb";
VAL_ 978 RQ_ENGMG_RST_OBD_DIAG 0 "Keine Anforderung Reset OBD_Diagnose" 2 "Anforderung Reset OBD_Diagnose" 3 "Signal ungültig";
VAL_ 222 CTR_DSC_PUP_INQY 0 "DSC Abfrage Pop-Up nicht aktiv" 1 "DSC Abfrage Pop-Up aktiv" 3 "Signal ungültig";
VAL_ 222 CTR_SYS_PUP_INQY 0 "Keine Anforderung" 1 "Fahrdynamik Pop-Up unterdrücken" 3 "Signal ungültig";
VAL_ 222 CTR_DISP_MDRV_3 0 "Kein Symbol anzeigen" 1 "M1 Symbol anzeigen" 2 "M2 Symbol anzeigen" 3 "M1 Symbol blinkend" 4 "M2 Symbol blinkend" 7 "Signal ungültig";
VAL_ 222 CTR_DISP_EPAS_MOD 0 "frei" 1 "Komfort" 2 "Sport" 3 "Sport Plus" 4 "Gilt ab SP2015" 7 "Signal ungültig";
VAL_ 222 CTR_DISP_FN_9_MIKO 0 "In M Fahrzeugen Motorsound Funktionsanzeige nicht aktiv." 1 "In M Fahrzeugen Motorsound Funktionsanzeige aktiv." 3 "Sendefunktion nicht in Betrieb";
VAL_ 222 CTR_DISP_EDC_MOD 0 "frei" 1 "Komfort" 2 "Sport" 3 "Sport Plus" 4 "Gilt ab SP2015" 7 "Signal ungültig";
VAL_ 222 CTR_DISP_ENG_MOD 0 "frei" 1 "Komfort" 2 "Sport" 3 "Sport Plus" 4 "Gilt ab SP2015" 7 "Signal ungültig";
VAL_ 222 CTR_DISP_ASR_MOD 0 "Status ASR ist aus" 1 "Status ASR ist an" 2 "Status ASR auf Dunkelschaltung" 3 "Sendefunktion nicht in Betrieb";
VAL_ 222 CTR_DISP_DRVGMOD 0 "Keine Aenderung" 1 "Einstellung Fahrmodus 1 (Default)" 2 "Einstellung Fahrmodus 1 (Individual)" 3 "Einstellung Fahrmodus 2 (Default)" 4 "Einstellung Fahrmodus 2 (Individual)" 5 "Einstellung Fahrmodus 3 (Default)" 6 "Einstellung Fahrmodus 3 (Individual)" 7 "Einstellung Fahrmodus 4 (Default)" 15 "Sendefunktion nicht in Betrieb";
VAL_ 222 CTR_DISP_LST_DRVGMOD 0 "Keine Liste anzeigen" 1 "Fahrmodusliste, FM1 aktiv" 2 "Fahrmodusliste, FM2 aktiv" 3 "Fahrmodusliste, FM3 aktiv" 4 "Fahrmodusliste, FM3 mit DSC OFF Symbol, FM1 aktiv" 5 "Fahrmodusliste, FM3 mit DSC OFF Symbol, FM2 aktiv" 6 "Fahrmodusliste, FM3 mit DSC OFF Symbol, FM3 aktiv" 7 "Fahrmodusliste, FM2+3 mit DSC OFF Symbol, FM1 aktiv" 8 "Fahrmodusliste, FM2+3 mit DSC OFF Symbol, FM2 aktiv" 9 "Fahrmodusliste, FM2+3 mit DSC OFF Symbol, FM3 aktiv" 15 "Sendefunktion nicht in Betrieb";
VAL_ 222 CTR_DISP_PUP_KI_INQY 0 "Kein Popup anzeigen" 1 "Fahrmoduswechsel von TRACK nach PURE" 2 "Fahrmoduswechsel von TRACK nach TRACK" 3 "Fahrmoduswechsel von PURE nach ROAD" 4 "Fahrmoduswechsel von PURE nach PURE" 5 "Fahrmoduswechsel von PURE nach TRACK" 6 "Fahrmoduswechsel von ROAD nach ROAD" 7 "Fahrmoduswechsel von ROAD nach PURE" 8 "Fahrmoduswechsel von ROAD nach TRACK" 16 "Fahrmoduswechsel mit DSC OFF" 32 "Fahrmoduswechsel mit MDM" 64 "M1 Tasterbetätigung" 128 "M2 Tasterbetätigung" 255 "Sendefunktion nicht in Betrieb";
VAL_ 222 CTR_DISP_PUP_KI_INFO 0 "Kein_Info_anzeigen" 1 "TRACK durch M1 Tasterbetätigung nur im Stand aktivierbar" 2 "TRACK durch M2 Tasterbetätigung nur im Stand aktivierbar" 3 "M1 Konfiguration wurde aktiviert" 4 "M2 Konfiguration wurde aktiviert" 5 "M1 Konfiguration wurde deaktiviert" 6 "M2 Konfiguration wurde deaktiviert" 7 "M1 Konfiguration nicht aktivierbar" 8 "M2 Konfiguration nicht aktivierbar" 9 "Funktion im TRACK nicht aktivierbar" 15 "Sendefunktion nicht in Betrieb";
VAL_ 222 CTR_DISP_CID 0 "Keine Tafel anzeigen" 1 "Aufruf Fahrmodus 1 Tafel" 2 "Aufruf Fahrmodus 2 Tafel" 3 "Aufruf Fahrmodus 3 Tafel" 4 "Aufruf Tafel Verlassensbestätigung" 5 "M1 Konfiguration ist aktiv" 6 "M1 Konfiguration ist nicht aktiv" 7 "M2 Konfiguration ist aktiv" 8 "M2 Konfiguration ist nicht aktiv" 15 "Sendefunktion nicht in Betrieb";
VAL_ 853 CTR_DRVBH_2_DISP 0 "Keine Änderung" 1 "Reset der Fahrstilanalyse" 7 "Signal ungültig";
VAL_ 202 CTR_T_MSECS_IDC 1021 "SIGNALTAG_FCTIF_NOT_AVAILABLE" 1022 "SIGNALTAG_FCT_ERROR" 1023 "Sendefunktion nicht in Betrieb";
VAL_ 202 CTR_T_SECS_IDC 13 "SIGNALTAG_FCTIF_NOT_AVAILABLE" 14 "SIGNALTAG_FCT_ERROR" 15 "Sendefunktion nicht in Betrieb";
VAL_ 556 CTR_GZADL 1 "DL_GZA AUS" 2 "DL_GZA EIN" 3 "Signal ungültig";
VAL_ 556 CTR_MOD_GZA_LH 0 "Kein Objekt anleuchten" 1 "Anleuchtart 1" 2 "Anleuchtart 2" 7 "Signal ungültig";
VAL_ 556 CTR_MOD_GZA_RH 0 "Kein Objekt anleuchten" 1 "Anleuchtart 1" 2 "Anleuchtart 2" 7 "Signal ungültig";
VAL_ 548 CTR_IDLI_DIPB 0 "Kontrolleuchte_Abblendlicht_Aus" 1 "Kontrolleuchte_Abblendlicht_Ein" 3 "Signal_unbefuellt";
VAL_ 548 CTR_IDLI_MBHF 0 "Kontrolleuchte_Fernlicht_Lichthupe_Aus" 1 "Kontrolleuchte_Fernlicht_Lichthupe_Ein" 3 "Signal_unbefuellt";
VAL_ 548 CTR_IDLI_POLI 0 "Kontrolleuchte_Standlicht_Aus" 1 "Kontrolleuchte_Standlicht_Ein" 3 "Signal_unbefuellt";
VAL_ 548 CTR_IDLI_FFLI 0 "Kontrolleuchte_Nebel_und_Schlechtwetterlicht_Aus" 1 "Kontrolleuchte_Nebel_und_Schlechtwetterlicht_Ein" 3 "Signal_unbefuellt";
VAL_ 548 CTR_IDLI_RFLI 0 "Kontrolleuchte_Nebelschlussleuchte_Aus" 1 "Kontrolleuchte_Nebelschlussleuchte_Ein" 3 "Signal_unbefuellt";
VAL_ 574 CTR_SWO_IDT_CHGNG_CA 0 "Keine CA_Schlüsselsuche aktiv bzw. beendet, IL_System kann über Aktivierung_Deaktiverung IL eigenständig entscheiden." 1 "Induktiv Laden System soll wegen angeforderter Schlüsselsuche Laden unterbrechen" 2 "Induktiv Laden System kann wieder aktiv werden" 3 "Sendefunktion nicht in Betrieb";
VAL_ 747 CTR_BRIGLEV_LP_EX 0 "Signal nach dem Aufwachen, bevor richtige Werte gesendet werden." 1 "Helligkeitssteuerung AUS" 15 "Signal ungültig";
VAL_ 747 CTR_FN_WELL 0 "Signal nach dem Aufwachen, bevor richtige Werte gesendet werden." 1 "OFF" 2 "Sofortiges Ausschalten" 3 "Welcome Light Modus 1" 4 "Welcome Light Modus 2" 5 "Welcome Light Modus 3" 6 "Welcome Light Modus 4" 7 "Welcome Light Modus 5. Gilt ab SP2018." 8 "Welcome Light Modus 6. Gilt ab SP2018." 15 "Signal ungültig";
VAL_ 747 CTR_FN_RFLP 0 "Signal nach dem Aufwachen, bevor richtige Werte gesendet werden." 1 "Zugfahrzeug: NSL AUS, Anhänger: NSL AUS" 2 "Zugfahrzeug: NSL EIN, Anhänger: NSL AUS" 3 "Zugfahrzeug: NSL EIN, Anhänger: NSL EIN" 4 "Zugfahrzeug: NSL AUS, Anhänger: NSL EIN" 8 "Blinkendes Nebelschlusslicht synchron" 9 "Blinkendes Nebelschlusslicht asynchron" 15 "Signal nicht gültig.";
VAL_ 747 CTR_FN_POLI 0 "Signal nach dem Aufwachen, bevor richtige Werte gesendet werden." 1 "Standlicht AUS" 2 "Standlicht Modus 1 EIN - Reduziertes Standlicht" 3 "Standlicht Modus 2 EIN - Normales Standlicht" 4 "Standlicht Modus 3 EIN - Standlicht Heck (bei Fahrlicht ohne Positionslicht in der Front)" 5 "Standlicht Modus 4 EIN - Standlicht Heck (alternatives Design). Gilt ab SP2018." 15 "Signal nicht gültig";
VAL_ 747 CTR_FN_PLI 0 "Signal nach dem Aufwachen, bevor richtige Werte gesendet werden." 1 "Parklicht links und rechts AUS" 2 "Parklicht links EIN, rechts AUS" 3 "Parklicht rechts EIN, links AUS" 15 "Signal nicht gültig.";
VAL_ 747 CTR_FN_RVLP 0 "Signal nach dem Aufwachen, bevor richtige Werte gesendet werden." 1 "Zugfahrzeug: Rückfahrlicht AUS, Anhänger: Rückfahrlicht AUS" 2 "Zugfahrzeug: Rückfahrlicht EIN, Anhänger: Rückfahrlicht EIN" 3 "Zugfahrzeug: Rückfahrlicht AUS, Anhänger: Rückfahrlicht EIN" 15 "Signal nicht gültig";
VAL_ 747 CTR_FN_BFD 0 "Signal nach dem Aufwachen, bevor richtige Werte gesendet werden." 1 "OFF" 2 "Flächenvergrößerung" 3 "Blinkendes Bremslicht Frequenz 1 (relevant bei Anhängerbetrieb): aufgrund unbekannter Leuchtmittel am Anhänger wird mit 3Hz geblinkt. Frequenz kann per Kodierung im Empfänger-Steuergerät modifiziert werden." 4 "Blinkendes Bremslicht Frequenz 2: 5Hz, wenn Bremslicht nur mit LEDs dargestellt ist. 3Hz, wenn Bremslicht mit Lampen dargestellt ist. Frequenz kann per Kodierung im Empfänger-Steuergerät modifiziert werden." 5 "Reserviert" 15 "Signal ungültig";
VAL_ 747 CTR_FN_DRL 0 "Signal nach dem Aufwachen, bevor richtige Werte gesendet werden." 1 "Tagfahrlicht AUS" 2 "Tagfahrlicht EIN" 6 "Tagfahrlicht EIN, Status TFL Links: i.O., Status TFL Rechts: ERROR - Funktionsfehler TFL Rechts vorne" 10 "Tagfahrlicht EIN, Status TFL Links: ERROR, Status TFL  Rechts: i.O. - Funktionsfehler TFL Links vorne" 14 "Tagfahrlicht EIN, Status TFL Links: ERROR, Status TFL Rechts: ERROR - Funktionsfehler TFL beidseitig" 15 "Signal nicht gültig.";
VAL_ 747 CTR_FN_BL 0 "Signal nach dem Aufwachen, bevor richtige Werte gesendet werden." 1 "Bremslicht AUS" 2 "Bremslicht EIN" 3 "Signal nicht gültig.";
VAL_ 747 CTR_FN_FMH 0 "Signal nach dem Aufwachen, bevor richtige Werte gesendet werden." 1 "Follow Me Home AUS" 2 "Follow Me Home EIN" 3 "Signal nicht gültig.";
VAL_ 747 CTR_FN_REMLI 0 "Signal nach dem Aufwachen, bevor richtige Werte gesendet werden." 1 "Remote-Light AUS" 2 "Remote-Light EIN - Phase EIN" 4 "Remote-Light EIN - Phase AUS" 15 "Signal nicht gültig.";
VAL_ 747 CTR_FN_GBL 0 "Signal nach dem Aufwachen, bevor richtige Werte gesendet werden." 1 "Ausschalten mit Rampe/ Sequenz" 2 "Sofortiges Ausschalten" 3 "Goodbye Light Modus 1" 13 "Hinweis: Reserviert für funktionale Kennung Signal-Tag." 14 "Hinweis: Reserviert für funktionale Kennung Signal-Tag." 15 "Sendefunktion nicht in Betrieb";
VAL_ 484 ControlFunctionLaserLeftHand 0 "Laser links AUS" 1 "Laser links EIN" 3 "Sendefunktion nicht in Betrieb";
VAL_ 484 ControlFunctionLaserRightHand 0 "Laser Rechts AUS" 1 "Laser Rechts EIN" 3 "Sendefunktion nicht in Betrieb";
VAL_ 484 CTR_LDSTR_LOWB_LH 1 "Schlechtwetter_C1" 2 "Schlechtwetter_C2" 3 "Stadt_V" 4 "Touristenmodus SAE" 5 "Default bzw. Failsafezustand (aktiv angesteuert) - wird auch bei Abblendlicht AUS gesendet" 6 "H_8_Autobahn_E3" 7 "H_6_Autobahn_E2" 8 "H_5_Autobahn_E1" 9 "H_4_Autobahn_E" 10 "H_10_Variante_1" 11 "H_10_Variante_2" 12 "Failsafe Lichtverteilung" 13 "Standby Lichtverteilung für blendfreies Fernlicht" 14 "Ab SP2015 gilt: blendfreies Fernlicht" 15 "Ab SP 2015 gilt: automatisches volles Fernlicht" 16 "Ab SP2015 gilt: Manuelles Fernlicht" 17 "Ab SP2015 gilt: Lichthupe" 18 "gilt nur ab SP2015: blendfreies Fernlicht Dimmung 1 (Vermeidung Eigenblendung an Verkehrsschildern)" 19 "gilt nur ab SP2015: blendfreies Fernlicht Dimmung 2 (Vermeidung Eigenblendung an Verkehrsschildern)" 20 "gilt nur ab SP2015: automatisches volles Fernlicht Dimmung 1 (Vermeidung Eigenblendung an Verkehrsschildern)" 21 "gilt nur ab SP2015: automatisches volles Fernlicht Dimmung 2 (Vermeidung Eigenblendung an Verkehrsschildern)" 22 "Aktivierung Matrixlicht. Ansteuerung erfolgt über CTR_LP_EX_ROI_1_LH/RH und CTR_LP_EX_ROI_2_LH/RH" 23 "Gilt nur ab SP2015" 24 "Gilt nur ab SP2015" 25 "Gilt nur ab SP2015" 26 "Gilt nur ab SP2015" 27 "Gilt nur ab SP2015" 28 "Gilt nur ab SP2015" 29 "Ab SP2015: Abblendlicht für Anleuchtfunktion DLS aktiv" 30 "Ab SP2015: Teilfernlicht für Anleuchtfunktion DLS aktiv" 31 "Sendefunktion nicht in Betrieb";
VAL_ 484 CTR_LDSTR_LOWB_RH 1 "Schlechtwetter_C1" 2 "Schlechtwetter_C2" 3 "Stadt_V" 4 "Touristenmodus SAE" 5 "Default bzw. Failsafezustand (aktiv angesteuert) - wird auch bei Abblendlicht AUS gesendet" 6 "H_8_Autobahn_E3" 7 "H_6_Autobahn_E2" 8 "H_5_Autobahn_E1" 9 "H_4_Autobahn_E" 10 "H_10_Variante_1" 11 "H_10_Variante_2" 12 "Failsafe Lichtverteilung" 13 "Standby Lichtverteilung für blendfreies Fernlicht" 14 "Ab SP2015 gilt: blendfreies Fernlicht" 15 "Ab SP 2015 gilt: automatisches volles Fernlicht" 16 "Ab SP2015 gilt: Manuelles Fernlicht" 17 "Ab SP2015 gilt: Lichthupe" 18 "gilt nur ab SP2015: blendfreies Fernlicht Dimmung 1 (Vermeidung Eigenblendung an Verkehrsschildern)" 19 "gilt nur ab SP2015: blendfreies Fernlicht Dimmung 2 (Vermeidung Eigenblendung an Verkehrsschildern)" 20 "gilt nur ab SP2015: automatisches volles Fernlicht Dimmung 1 (Vermeidung Eigenblendung an Verkehrsschildern)" 21 "gilt nur ab SP2015: automatisches volles Fernlicht Dimmung 2 (Vermeidung Eigenblendung an Verkehrsschildern)" 22 "Aktivierung Matrixlicht. Ansteuerung erfolgt über CTR_LP_EX_ROI_1_LH/RH und CTR_LP_EX_ROI_2_LH/RH" 23 "Gilt nur ab SP2015" 24 "Gilt nur ab SP2015" 25 "Gilt nur ab SP2015" 26 "Gilt nur ab SP2015" 27 "Gilt nur ab SP2015" 28 "Gilt nur ab SP2015" 29 "Ab SP2015: Abblendlicht für Anleuchtfunktion DLS aktiv" 30 "Ab SP2015: Teilfernlicht für Anleuchtfunktion DLS aktiv" 31 "Sendefunktion nicht in Betrieb";
VAL_ 484 CTR_FN_CORNL_LH 0 "Signal nach dem Aufwachen, bevor richtige Werte gesendet werden." 1 "Abbiegelicht links mit Rampe 1 AUS" 2 "Abbiegelicht links mit Rampe 2 AUS" 3 "Abbiegelicht links mit Rampe 3 AUS" 4 "Abbiegelicht links mit Rampe 1 EIN" 5 "Abbiegelicht links mit Rampe 2 EIN" 6 "Abbiegelicht links mit Rampe 3 EIN" 7 "Abbiegelicht links hart AUS" 9 "Abbiegelicht links hart EIN" 15 "Signal nicht gültig.";
VAL_ 484 CTR_FN_CORNL_RH 0 "Signal nach dem Aufwachen, bevor richtige Werte gesendet werden." 1 "Abbiegelicht rechts mit Rampe 1 AUS" 2 "Abbiegelicht rechts mit Rampe 2 AUS" 3 "Abbiegelicht rechts mit Rampe 3 AUS" 4 "Abbiegelicht rechts mit Rampe 1 EIN" 5 "Abbiegelicht rechts mit Rampe 2 EIN" 6 "Abbiegelicht rechts mit Rampe 3 EIN" 7 "Abbiegelicht rechts hart AUS" 9 "Abbiegelicht rechts hart EIN" 15 "Signal nicht gültig.";
VAL_ 484 CTR_PHA_FN_SPFLS 1 "Sonderblinken AUS" 2 "Sonderblinken EIN / Beidseitig Phase EIN" 3 "Sonderblinken EIN / Beidseitig Phase AUS" 5 "Sonderblinken EIN / Links Phase AUS, Rechts Phase EIN" 6 "Sonderblinken EIN / Links Phase EIN, Rechts Phase AUS" 15 "Signal nicht gültig.";
VAL_ 484 CTR_MOD_FN_SPFLS 1 "Sonderblinken AUS" 2 "Sonderblinken EIN - Modus DWA-Blinken" 3 "Sonderblinken EIN - Modus Panic-Mode" 4 "Sonderblinken EIN - Modus Fernlichtblinken" 5 "Sonderblinken EIN - Modus Überfallalarm" 15 "Signal nicht gültig.";
VAL_ 658 VLDY_OBJ_DT 1 "Objektdaten gültig" 2 "Objektdaten ungültig" 3 "Signal ungültig";
VAL_ 658 QUAN_DOM_NGL 13 "SIGNALTAG_FCTIF_NOT_AVAILABLE" 14 "SIGNALTAG_FCT_ERROR" 15 "Sendefunktion nicht in Betrieb";
VAL_ 658 REAS_SWO_MAB 0 "Nichts erkannt" 1 "Entgegenkommender Verkehr" 2 "Vorausfahrender Verkehr" 4 "Geschwindigkeitslimit" 8 "Umgebungshelligkeit" 16 "Ortschaftserkennung" 32 "Nebelerkennung" 64 "Autobahnmode" 128 "Verzögerungszeit" 255 "Signal ungültig";
VAL_ 658 REAS_SWO_MAB_2 0 "Nichts erkannt" 1 "Kamera erkennt Tunnel" 2 "Kamera meldet eine Sichtblockade" 4 "Kamera erkennt Rechtsverkehr (=0) oder Linksverkehr (=1)" 8 "Kamera meldet einen Failsafe Status" 16 "Kamera erkennt starken Schneefall" 32 "Kamera erkennt starken Regen" 64 "Kamera erkennt Stadt" 128 "Kamera erkennt einen Kreisverkehr" 255 "Signal ungültig";
VAL_ 658 MAB_DIM_1 0 "Fernlichthelligkeit 100%" 1 "z.B. Fernlichthelligkeit 85%" 2 "z.B. Fernlichthelligkeit 70%" 3 "Signal ungültig";
VAL_ 658 MAB_DIM_2 0 "Fernlichthelligkeit 100%" 1 "z.B. Fernlichthelligkeit 85%" 2 "z.B. Fernlichthelligkeit 70%" 3 "Signal ungültig";
VAL_ 658 MAB_DIM_3 0 "Fernlichthelligkeit 100%" 1 "z.B. Fernlichthelligkeit 85%" 2 "z.B. Fernlichthelligkeit 70%" 3 "Signal ungültig";
VAL_ 658 MAB_DIM_4 0 "Fernlichthelligkeit 100%" 1 "z.B. Fernlichthelligkeit 85%" 2 "z.B. Fernlichthelligkeit 70%" 3 "Signal ungültig";
VAL_ 658 MAB_DIM_5 0 "Fernlichthelligkeit 100%" 1 "z.B. Fernlichthelligkeit 85%" 2 "z.B. Fernlichthelligkeit 70%" 3 "Signal ungültig";
VAL_ 658 QU_FN_DIM 6 "Sendefunktion in Betrieb, meldet Fehler." 9 "Erkennung von blendenden Objekten uneingeschränkt möglich." 11 "Erkennung von blendenden Objekten möglich, jedoch ist mit Einschränkungen in der Genauigkeit zu rechnen." 14 "Keine Erkennung von blendenden Objekten möglich." 15 "Sendefunktion nicht in Betrieb";
VAL_ 658 HighBeamAssistEnabled 0 "Signalinhalt, während der Initialisierung" 1 "Der Fernlichtassistent ist noch nicht über SWT freigeschaltet" 2 "Der Fernlichtassistent ist über SWT freigeschaltet" 3 "Sendefunktion nicht in Betrieb";
VAL_ 899 CTR_EPS_SU 0 "Keine Aenderung" 1 "Servotronic auf Komfort Modus" 2 "Servotronic auf Sport Modus" 3 "Servotronic auf Sport Plus Modus" 15 "Sendefunktion nicht in Betrieb";
VAL_ 899 CTR_VDC_SU 0 "Keine Aenderung" 1 "EDC auf Komfort Modus" 2 "EDC auf Sport Modus" 3 "EDC auf Sport Plus Modus" 15 "Sendefunktion nicht in Betrieb";
VAL_ 899 CTR_ENG_SU 0 "Keine Aenderung" 1 "Motorsteuerung auf Komfort Modus" 2 "Motorsteuerung auf Sport Modus" 3 "Motorsteuerung auf Sport Plus Modus" 15 "Sendefunktion nicht in Betrieb";
VAL_ 899 CTR_ASR_SU 0 "Keine Aenderung" 1 "ASR Modus ist aus" 2 "ASR Modus ist an" 3 "Sendefunktion nicht in Betrieb";
VAL_ 899 CTR_DRVGMOD_INQY 0 "Keine Aenderung" 1 "Fahrmodus aktivieren nicht bestätigt." 2 "Fahrmodus aktivieren bestätigt." 3 "Sendefunktion nicht in Betrieb";
VAL_ 899 CTR_BRPD_SU 0 "Keine_Aenderung" 1 "Kennlinie_1" 2 "Kennlinie_2" 3 "Kennlinie_3" 15 "Sendefunktion nicht in Betrieb";
VAL_ 899 ControlDriftSupportLevelSetup 0 "Nicht_genutzt" 1 "Assistenz_Level_0" 2 "Assistenz_Level_1" 3 "Assistenz_Level_2" 4 "Assistenz_Level_3" 5 "Assistenz_Level_4" 6 "Assistenz_Level_5" 7 "Assistenz_Level_6" 8 "Assistenz_Level_7" 9 "Assistenz_Level_8" 10 "Assistenz_Level_9" 11 "Assistenz_Level_10" 13 "SIGNALTAG_FCTIF_NOT_AVAILABLE" 14 "SIGNALTAG_FCT_ERROR" 15 "Sendefunktion nicht in Betrieb";
VAL_ 899 ControlDriftMControlPlusTraction 0 "Nicht_genutzt" 1 "Traktion_Level_0" 2 "Traktion_Level_1" 3 "Traktion_Level_2" 4 "Traktion_Level_3" 5 "Traktion_Level_4" 6 "Traktion_Level_5" 7 "Traktion_Level_6" 8 "Traktion_Level_7" 9 "Traktion_Level_8" 10 "Traktion_Level_9" 11 "Traktion_Level_10" 13 "SIGNALTAG_FCTIF_NOT_AVAILABLE" 14 "SIGNALTAG_FCT_ERROR" 15 "Sendefunktion nicht in Betrieb";
VAL_ 899 ControlDriftMControlPlusBrakeBal 0 "Nicht_genutzt" 1 "Bremsbalance_Level_0" 2 "Bremsbalance_Level_1" 3 "Bremsbalance_Level_2" 4 "Bremsbalance_Level_3" 5 "Bremsbalance_Level_4" 6 "Bremsbalance_Level_5" 7 "Bremsbalance_Level_6" 8 "Bremsbalance_Level_7" 9 "Bremsbalance_Level_8" 10 "Bremsbalance_Level_9" 11 "Bremsbalance_Level_10" 13 "SIGNALTAG_FCTIF_NOT_AVAILABLE" 14 "SIGNALTAG_FCT_ERROR" 15 "Sendefunktion nicht in Betrieb";
VAL_ 899 ControlDriftSetup 0 "Keine_Aenderung" 1 "M_Drift_nicht_bestaetigt" 2 "M_Drift_bestaetigt" 3 "Sendefunktion nicht in Betrieb";
VAL_ 899 ControlDriftReset 0 "Keine_Bedienung" 1 "Reset_Last_Best_Drift" 3 "Sendefunktion nicht in Betrieb";
VAL_ 899 ControlDriftRecording 0 "Keine_Bedienung" 1 "Start_Recording" 2 "Stopp_Recording" 3 "Sendefunktion nicht in Betrieb";
VAL_ 640 RQ_BST_RPM_IDLG_SFYC 0 "Keine Anforderung einer Leerlaufdrehzahlerhöhung" 1 "Anforderung Leerlaufdrehzahlerhöhung bei schwacher Startbatterie" 2 "nicht verwendet" 3 "Signal ungültig";
VAL_ 223 CTR_DISP_SHLI_SEG 0 "Alle Segmente AUS" 1 "1 Segment  AN" 2 "2 Segmente AN" 3 "3 Segmente AN" 4 "4 Segmente AN" 5 "5 Segmente AN" 6 "6 Segmente AN" 7 "7 Segmente AN" 8 "8 Segmente AN" 15 "Signal ungültig";
VAL_ 223 CTR_DISP_SHLI_FLS 0 "frei" 1 "Shiftlights Blinken" 2 "Shiftlights nicht Blinken" 3 "Signal ungültig";
VAL_ 901 OptionSpeedLimitChangeWarning 0 "Auswahl nicht gesetzt" 1 "Auswahl gesetzt" 2 "Auswahl deaktiviert" 3 "Sendefunktion nicht in Betrieb";
VAL_ 901 OPTN_SLI_OFFS 61 "Hinweis: Reserviert für funktionale Kennung Signal-Tag." 62 "Hinweis: Reserviert für funktionale Kennung Signal-Tag." 63 "Sendefunktion nicht in Betrieb";
VAL_ 901 OPTN_SLI_DISP 0 "SLI-Anzeige deaktiviert" 1 "SLI-Anzeige aktiviert" 3 "Sendefunktion nicht in Betrieb";
VAL_ 901 OPTN_SLI_WARN 0 "Auswahl nicht gesetzt" 1 "Auswahl gesetzt" 2 "Auswahl deaktiviert" 3 "Sendefunktion nicht in Betrieb";
VAL_ 901 OPTN_SLI_STAG 0 "Auswahl nicht gesetzt" 1 "Auswahl gesetzt" 2 "Auswahl deaktiviert" 3 "Sendefunktion nicht in Betrieb";
VAL_ 901 OPTN_OFFS_SLOW 0 "Abschaltaufforderung" 1 "Einschaltaufforderung" 3 "Sendefunktion nicht in Betrieb";
VAL_ 901 OPTN_SLI_OFFS_SLOW 61 "Hinweis: Reserviert für funktionale Kennung Signal-Tag." 62 "Hinweis: Reserviert für funktionale Kennung Signal-Tag." 63 "Sendefunktion nicht in Betrieb";
VAL_ 901 OptionSpeedLimitWarningSecondLev 0 "Auswahl nicht gesetzt" 1 "Auswahl gesetzt" 2 "Auswahl deaktiviert" 3 "Sendefunktion nicht in Betrieb";
SIG_GROUP_ 409 e2eGrp_ACLNX_MASSCNTR 1 : CRC_ACLNX_COG ALIV_ACLNX_COG ACLNX_MASSCNTR_dummy_12_15 ACLNX_COG ACLNX_COG_ERR_AMP QU_ACLNX_COG;
SIG_GROUP_ 410 e2eGrp_ACLNY_MASSCNTR 1 : CRC_ACLNY_COG ALIV_ACLNY_COG ACLNY_MASSCNTR_dummy_12_15 ACLNY_COG ACLNY_COG_ERR_AMP QU_ACLNY_COG;
SIG_GROUP_ 217 e2eGrp_ANG_ACPD 1 : CRC_ANG_ACPD ALIV_ANG_ACPD ST_ECU_ANG_ACPD AVL_ANG_ACPD QU_AVL_ANG_ACPD AVL_ANG_ACPD_VIRT GRAD_AVL_ANG_ACPD ST_INTF_DRASY ECO_ANG_ACPD ANG_ACPD_dummy_62_63;
SIG_GROUP_ 239 e2eGrp_AVL_BRTORQ_SUM 1 : CRC_AVL_BRTORQ_SUM ALIV_AVL_BRTORQ_SUM AVL_BRTORQ_SUM_dummy_12_15 AVL_BRTORQ_SUM QU_AVL_BRTORQ_SUM QU_AVL_BRTORQ_SUM_DVCH AVL_BRTORQ_SUM_DVCH AVL_BRTORQ_SUM_DVCH_RAW;
SIG_GROUP_ 2161115410 signalGrp_CEMErrorEvent_DA12h 1 : CEMErrorEventDTC_DA12h CEMErrorEventTimeStampSec_DA12h CEMErrorEventTimeStampMSec_DA12h CEMErrorEventSyncMethod_DA12h CEMErrorEventECUAddress_DA12h;
SIG_GROUP_ 2161115667 signalGrp_CEMErrorEvent_DA13h 1 : CEMErrorEventDTC_DA13h CEMErrorEventTimeStampSec_DA13h CEMErrorEventTimeStampMSec_DA13h CEMErrorEventSyncMethod_DA13h CEMErrorEventECUAddress_DA13h;
SIG_GROUP_ 2161116184 signalGrp_CEMErrorEvent_DA18h 1 : CEMErrorEventDTC_DA18h CEMErrorEventTimeStampSec_DA18h CEMErrorEventTimeStampMSec_DA18h CEMErrorEventSyncMethod_DA18h CEMErrorEventECUAddress_DA18h;
SIG_GROUP_ 2161116445 signalGrp_CEMErrorEvent_DA1Dh 1 : CEMErrorEventDTC_DA1Dh CEMErrorEventTimeStampSec_DA1Dh CEMErrorEventTimeStampMSec_DA1Dh CEMErrorEventSyncMethod_DA1Dh CEMErrorEventECUAddress_DA1Dh;
SIG_GROUP_ 2161117269 signalGrp_CEMErrorEvent_DA55h 1 : CEMErrorEventDTC_DA55h CEMErrorEventTimeStampSec_DA55h CEMErrorEventTimeStampMSec_DA55h CEMErrorEventSyncMethod_DA55h CEMErrorEventECUAddress_DA55h;
SIG_GROUP_ 876 e2eGrp_CODO_LIM_V 1 : CRC_CODO_LIM_V ALIV_CODO_LIM_V ST_ECU_CODO_LIM_V QU_CODO_LIM_V CODO_LIM_V_dummy_20_23;
SIG_GROUP_ 60 e2eGrp_CON_VEH 1 : CRC_CON_VEH ALIV_CON_VEH CTR_BS_PRTNT CTR_FKTN_PRTNT ST_CON_VEH QU_ST_CON_VEH CON_VEH_dummy_56_63;
SIG_GROUP_ 202 e2eGrp_CTR_FN_IDC 1 : CRC_CTR_FNS_IDC ALIV_CTR_FNS_IDC CHL_CTR_FN_IDC CTR_FREQ_IDC CTR_SYNC_IDC CTR_IDC CTR_DISP_IDC ACV_FN_IDC OVLY_FN_IDC CTR_T_MSECS_IDC CTR_T_SECS_IDC CTR_FN_IDC_dummy_62_63;
SIG_GROUP_ 747 e2eGrp_CTR_LP_EX 1 : CRC_CTR_LP_EX ALIV_CTR_LP_EX CTR_BRIGLEV_LP_EX CTR_FN_WELL CTR_FN_RFLP CTR_FN_POLI CTR_FN_PLI CTR_FN_RVLP CTR_FN_BFD CTR_FN_DRL CTR_FN_BL CTR_FN_FMH CTR_FN_REMLI CTR_FN_GBL CTR_LP_EX_dummy_56_63;
SIG_GROUP_ 484 e2eGrp_CTR_LP_EX_2 1 : CRC_CTR_LP_EX_2 ALIV_CTR_LP_EX_2 ControlFunctionLaserLeftHand ControlFunctionLaserRightHand CTR_FN_DIPB_LH CTR_LDSTR_LOWB_LH CTR_FN_DIPB_RH CTR_LDSTR_LOWB_RH CTR_FN_CORNL_LH CTR_FN_CORNL_RH CTR_PHA_FN_SPFLS CTR_MOD_FN_SPFLS CTR_FN_MAB CTR_FN_OVT CTR_FN_FFLI CTR_FN_ML;
